VERSION ""

NS_ :

BS_:

BU_: BCMB_AUXM SCMB_PSM HVAC_RCCM SOBDMD_AHCM_FOH TRM GWM _delete RTM PDM SCMH SCMG RSM DDM RGTM DSM GENERIC TSTR

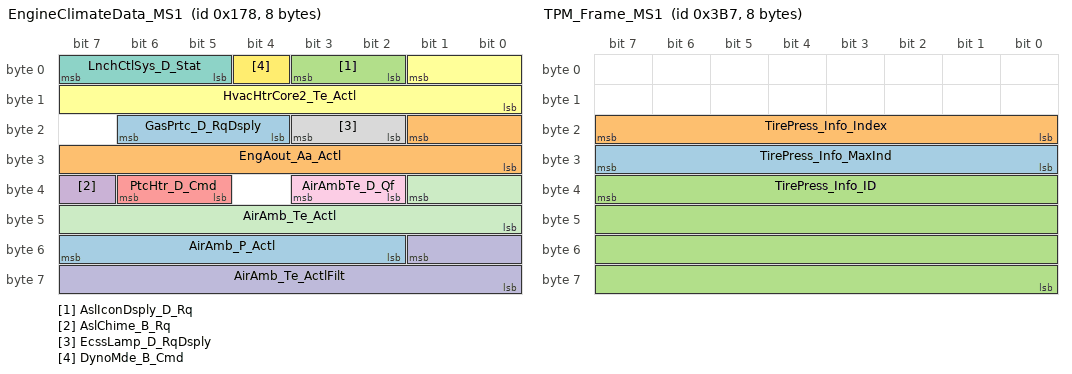
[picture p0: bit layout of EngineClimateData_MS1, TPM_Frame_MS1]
BO_ 376 EngineClimateData_MS1: 8 GWM
 SG_ GasPrtc_D_RqDsply : 22|3@0+ (1,0) [0|7] "SED"  GENERIC
 SG_ EngAout_Aa_Actl : 17|10@0+ (0.05,-25.6) [-25.6|25.55] "rpm/ms"  GENERIC
 SG_ AslIconDsply_D_Rq : 3|2@0+ (1,0) [0|3] "SED"  GENERIC
 SG_ AslChime_B_Rq : 39|1@0+ (1,0) [0|1] "SED"  GENERIC
 SG_ PtcHtr_D_Cmd : 38|2@0+ (1,0) [0|3] "SED"  GENERIC
 SG_ HvacHtrCore2_Te_Actl : 1|10@0+ (0.25,-50) [-50|205.5] "degC"  HVAC_RCCM
 SG_ LnchCtlSys_D_Stat : 7|3@0+ (1,0) [0|7] "SED" Vector__XXX
 SG_ EcssLamp_D_RqDsply : 19|2@0+ (1,0) [0|3] "SED"  GENERIC
 SG_ AirAmbTe_D_Qf : 35|2@0+ (1,0) [0|3] "SED"  HVAC_RCCM
 SG_ AirAmb_Te_ActlFilt : 49|10@0+ (0.25,-128) [-128|127.75] "deg C"  HVAC_RCCM
 SG_ AirAmb_Te_Actl : 33|10@0+ (0.25,-128) [-128|127.75] "degC"  HVAC_RCCM
 SG_ DynoMde_B_Cmd : 4|1@0+ (1,0) [0|1] "SED"  GENERIC
 SG_ AirAmb_P_Actl : 55|6@0+ (10,500) [500|1110] "mbar"  SOBDMD_AHCM_FOH

BO_ 951 TPM_Frame_MS1: 8 GWM
 SG_ TirePress_Info_MaxInd : 31|8@0+ (1,0) [0|255] "Unitless"  RTM
 SG_ TirePress_Info_Index : 23|8@0+ (1,0) [0|255] "Unitless"  RTM
 SG_ TirePress_Info_ID : 39|32@0+ (1,0) [0|4294967295] "Unitless"  RTM

BO_ 1068 Batt_Mgmt_Data_MS1: 8 GWM
 SG_ HvacAirFullOut_B_Rq_UB : 60|1@0+ (1,0) [0|1] "SED"  HVAC_RCCM
 SG_ HvacAirFullOut_B_Rq : 61|1@0+ (1,0) [0|1] "SED"  HVAC_RCCM
 SG_ HvacCmprLim_D_Stat_UB : 56|1@0+ (1,0) [0|1] "SED"  HVAC_RCCM
 SG_ HvacCmprLim_D_Stat : 59|3@0+ (1,0) [0|7] "SED"  HVAC_RCCM
 SG_ HvacAirFlw_B_RqBatt_UB : 62|1@0+ (1,0) [0|1] "SED"  HVAC_RCCM
 SG_ HvacAirFlw_B_RqBatt : 63|1@0+ (1,0) [0|1] "SED"  HVAC_RCCM
 SG_ HvacRec_D_RqMxBatt_UB : 21|1@0+ (1,0) [0|1] "SED"  HVAC_RCCM
 SG_ HvacRec_D_RqMxBatt : 20|4@0+ (1,0) [0|15] "SED"  HVAC_RCCM
 SG_ Batt_Lo_SoC_B_UB : 22|1@0+ (1,0) [0|1] "SED"  HVAC_RCCM,TRM
 SG_ Batt_Lo_SoC_B : 23|1@0+ (1,0) [0|1] "SED"  HVAC_RCCM,TRM
 SG_ Batt_Crit_SoC_B_UB : 14|1@0+ (1,0) [0|1] "SED"  HVAC_RCCM,TRM
 SG_ Batt_Crit_SoC_B : 15|1@0+ (1,0) [0|1] "SED"  HVAC_RCCM,TRM
 SG_ Shed_T_Eng_Off_B_UB : 12|1@0+ (1,0) [0|1] "SED"  HVAC_RCCM,TRM
 SG_ Shed_T_Eng_Off_B : 13|1@0+ (1,0) [0|1] "SED"  HVAC_RCCM,TRM
 SG_ Shed_Level_Req_UB : 8|1@0+ (1,0) [0|1] "SED"  HVAC_RCCM,DDM,PDM,TRM
 SG_ Shed_Level_Req : 11|3@0+ (1,0) [0|7] "SED"  HVAC_RCCM,DDM,PDM,TRM
 SG_ Shed_Feature_Group_ID_UB : 2|1@0+ (1,0) [0|1] "SED"  HVAC_RCCM,TRM
 SG_ Shed_Feature_Group_ID : 7|5@0+ (1,0) [0|31] "SED"  HVAC_RCCM,TRM
 SG_ Shed_Drain_Eng_Off_B_UB : 0|1@0+ (1,0) [0|1] "SED"  HVAC_RCCM,TRM
 SG_ Shed_Drain_Eng_Off_B : 1|1@0+ (1,0) [0|1] "SED"  HVAC_RCCM,TRM
 SG_ HvacAir_Flw_EstBatt_UB : 16|1@0+ (1,0) [0|1] "SED"  HVAC_RCCM
 SG_ HvacAir_Flw_EstBatt : 31|8@0+ (0.5,0) [0|127] "liter/second"  HVAC_RCCM
 SG_ AirCondRec_B_Rq_UB : 44|1@0+ (1,0) [0|1] "SED"  HVAC_RCCM
 SG_ AirCondFluidHi_P_Actl_UB : 45|1@0+ (1,0) [0|1] "SED"  HVAC_RCCM
 SG_ AirCondClutch_B_Stats_UB : 43|1@0+ (1,0) [0|1] "SED"  HVAC_RCCM
 SG_ AirCondRec_B_Rq : 47|1@0+ (1,0) [0|1] "SED"  HVAC_RCCM
 SG_ AirCondFluidHi_P_Actl : 39|8@0+ (0.125,0) [0|31.625] "bar"  HVAC_RCCM
 SG_ AirCondClutch_B_Stats : 46|1@0+ (1,0) [0|1] "SED"  HVAC_RCCM

BO_ 963 BCM_Lamp_Stat_MS1: 8 GWM
 SG_ Illuminated_Entry_Stat : 63|2@0+ (1,0) [0|3] "SED" Vector__XXX
 SG_ Dr_Courtesy_Light_Stat : 49|2@0+ (1,0) [0|3] "SED" Vector__XXX
 SG_ ImpactEvntFdbck_D_Stat : 53|2@0+ (1,0) [0|3] "SED"  GENERIC
 SG_ DrTgateLck_D_Stat : 61|2@0+ (1,0) [0|3] "SED"  GENERIC
 SG_ PudLampPsngr_D_Rq : 57|2@0+ (1,0) [0|3] "SED"  PDM
 SG_ HeadLampLoOut_B_Stat : 32|1@0+ (1,0) [0|1] "SED"  GENERIC
 SG_ CrnrLghtRight_Pc_Rq : 47|7@0+ (1,0) [0|100] "percent"  GENERIC
 SG_ CrnrLghtLeft_Pc_Rq : 39|7@0+ (1,0) [0|100] "percent"  GENERIC
 SG_ HeadLghtHiFdbck_D_Stat : 55|2@0+ (1,0) [0|3] "SED"  GENERIC
 SG_ PrkLightChime_B_Rq : 25|1@0+ (1,0) [0|1] "SED"  GENERIC
 SG_ TrnNotInPrkChime_B_Rq : 24|1@0+ (1,0) [0|1] "SED"  GENERIC
 SG_ HomeSafeLtChime_B_Rq : 28|1@0+ (1,0) [0|1] "SED"  GENERIC
 SG_ StopLghtOn_B_Stat : 8|1@0+ (1,0) [0|1] "SED"  RSM,TRM
 SG_ RvrseLghtOn_B_Stat : 9|1@0+ (1,0) [0|1] "SED"  TRM
 SG_ PrkLght_D_Stat : 13|2@0+ (1,0) [0|3] "SED"  TRM
 SG_ HeadLghtSwtch_D_Stat : 15|2@0+ (1,0) [0|3] "SED"  GENERIC
 SG_ KeyInIgnWarn_B_Cmd : 27|1@0+ (1,0) [0|1] "SED"  GENERIC
 SG_ HeadLampLoFrOn_B_Stat : 2|1@0+ (1,0) [0|1] "SED"  GENERIC
 SG_ HeadLampLoFlOn_B_Stat : 3|1@0+ (1,0) [0|1] "SED"  GENERIC
 SG_ Headlamp_On_Wrning_Cmd : 29|1@0+ (1,0) [0|1] "SED"  GENERIC
 SG_ HeadLampLoActv_B_Stat : 4|1@0+ (1,0) [0|1] "SED"  GENERIC
 SG_ HeadLghtHiOn_B_Stat : 1|1@0+ (1,0) [0|1] "SED"  GENERIC
 SG_ Park_Brake_Chime_Rqst : 26|1@0+ (1,0) [0|1] "SED"  GENERIC
 SG_ BrkWarnInd_B_Rq : 20|1@0+ (1,0) [0|1] "SED"  GENERIC
 SG_ Brk_Fluid_Lvl_Low : 31|2@0+ (1,0) [0|3] "SED"  GENERIC
 SG_ ReducedGuard_D_Stat : 19|2@0+ (1,0) [0|3] "SED"  GENERIC
 SG_ Courtesy_BSave_Stat : 7|2@0+ (1,0) [0|3] "SED"  DDM,PDM
 SG_ DayRnngLampOn_B_Stat : 5|1@0+ (1,0) [0|1] "SED"  GENERIC
 SG_ PerimeterAlarmChimeRq : 0|1@0+ (1,0) [0|1] "SED"  GENERIC
 SG_ PudLampDrv_D_Rq : 59|2@0+ (1,0) [0|3] "SED"  DDM
 SG_ Courtesy_Delay_Status : 51|2@0+ (1,0) [0|3] "SED" Vector__XXX
 SG_ Perimeter_Alarm_Status : 17|2@0+ (1,0) [0|3] "SED"  RSM,TRM
 SG_ WndwGlbl_D_Cmd : 23|3@0+ (1,0) [0|7] "SED"  DDM,PDM
 SG_ PudLamp_D_Rq : 11|2@0+ (1,0) [0|3] "SED"  DDM,PDM

BO_ 964 BodyInfo_MS1: 8 GWM
 SG_ FohEng_D_Rq_UB : 60|1@0+ (1,0) [0|1] "SED"  SOBDMD_AHCM_FOH
 SG_ FohEng_D_Rq : 62|2@0+ (1,0) [0|3] "SED"  SOBDMD_AHCM_FOH
 SG_ EcoMode_B_Stat_UB : 56|1@0+ (1,0) [0|1] "SED"  GENERIC
 SG_ Cta_D_Rq_UB : 57|1@0+ (1,0) [0|1] "SED" Vector__XXX
 SG_ Cta_D_Rq : 59|2@0+ (1,0) [0|3] "SED" Vector__XXX
 SG_ GearRvrse_D_Actl_UB : 48|1@0+ (1,0) [0|1] "SED"  HVAC_RCCM,PDM,DDM
 SG_ GearRvrse_D_Actl : 51|3@0+ (1,0) [0|7] "SED"  HVAC_RCCM,PDM,DDM
 SG_ TurnLghtSwtch_D_Stat_UB : 52|1@0+ (1,0) [0|1] "SED" Vector__XXX
 SG_ TurnLghtSwtch_D_Stat : 54|2@0+ (1,0) [0|3] "SED" Vector__XXX
 SG_ Power_Liftgate_Mode_Cmd_UB : 6|1@0+ (1,0) [0|1] "SED"  RGTM
 SG_ Power_Liftgate_Mode_Cmd : 7|1@0+ (1,0) [0|1] "SED"  RGTM
 SG_ EcoMode_B_Stat : 20|1@0+ (1,0) [0|1] "SED"  GENERIC
 SG_ MetricActvTe_B_Actl_UB : 2|1@0+ (1,0) [0|1] "SED"  HVAC_RCCM
 SG_ MetricActvTe_B_Actl : 3|1@0+ (1,0) [0|1] "SED"  HVAC_RCCM
 SG_ EngClntTe_D_Qf : 22|2@0+ (1,0) [0|3] "SED"  HVAC_RCCM
 SG_ Sod_D_Rq : 1|2@0+ (1,0) [0|3] "SED" Vector__XXX
 SG_ MetricActv_B_Actl : 5|1@0+ (1,0) [0|1] "SED"  HVAC_RCCM
 SG_ EngClnt_Te_Actl : 15|8@0+ (1,-60) [-60|195] "degC"  HVAC_RCCM
 SG_ MetricActv_B_Actl_UB : 4|1@0+ (1,0) [0|1] "SED"  HVAC_RCCM
 SG_ EngClnt_Te_Actl_UB : 23|1@0+ (1,0) [0|1] "SED"  HVAC_RCCM
 SG_ OCSSensrDataUpperLim_UB : 28|1@0+ (1,0) [0|1] "SED"  HVAC_RCCM,SCMG,SCMH
 SG_ OCSSensrDataUpperLim : 47|8@0+ (1,0) [0|254] "SED"  HVAC_RCCM,SCMG,SCMH
 SG_ OCSSensrDataLowerLim_UB : 29|1@0+ (1,0) [0|1] "SED"  HVAC_RCCM,SCMG,SCMH
 SG_ PrkAid_D_Falt : 18|3@0+ (1,0) [0|7] "SED"  GENERIC
 SG_ OCSSensrDataLowerLim : 39|8@0+ (1,0) [0|254] "SED"  HVAC_RCCM,SCMG,SCMH
 SG_ PrkAid_D_Falt_UB : 63|1@0+ (1,0) [0|1] "SED"  GENERIC
 SG_ WiprFront_D_Stat_UB : 55|1@0+ (1,0) [0|1] "SED"  HVAC_RCCM
 SG_ WiprFront_D_Stat : 27|4@0+ (1,0) [0|15] "SED"  HVAC_RCCM
 SG_ CamraDefog_B_Req_UB : 30|1@0+ (1,0) [0|1] "SED"  HVAC_RCCM
 SG_ Sod_D_Rq_UB : 19|1@0+ (1,0) [0|1] "SED" Vector__XXX
 SG_ CamraDefog_B_Req : 31|1@0+ (1,0) [0|1] "SED"  HVAC_RCCM

BO_ 1843 TesterPhysicalReqHVAC_RCCM: 8 TSTR
 SG_ TesterPhysicalReqHVAC_RCCM : 7|64@0+ (1,0) [0|1.84467E+019] "unitless"  HVAC_RCCM

BO_ 1851 TesterPhysicalResHVAC_RCCM: 8 HVAC_RCCM
 SG_ TesterPhysicalResHVAC_RCCM : 7|64@0+ (1,0) [0|1.84467E+019] "unitless"  TSTR

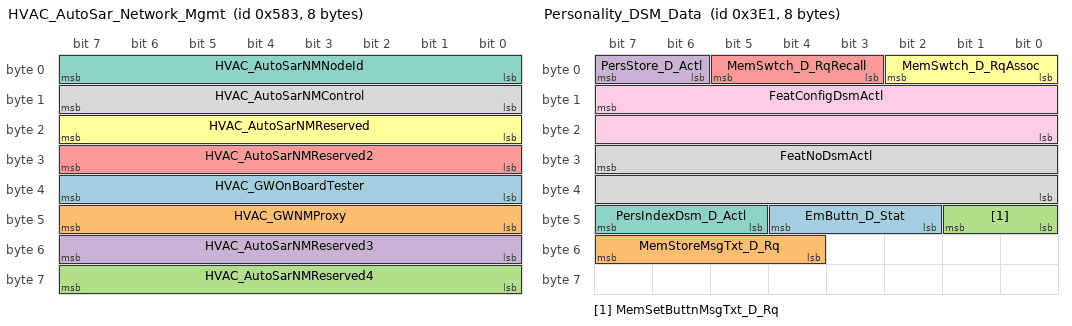
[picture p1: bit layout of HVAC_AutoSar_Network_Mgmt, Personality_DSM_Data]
BO_ 1411 HVAC_AutoSar_Network_Mgmt: 8 HVAC_RCCM
 SG_ HVAC_GWOnBoardTester : 39|8@0+ (1,0) [0|255] "unitless"  GWM
 SG_ HVAC_GWNMProxy : 47|8@0+ (1,0) [0|255] "unitless"  GWM
 SG_ HVAC_AutoSarNMReserved4 : 63|8@0+ (1,0) [0|255] "unitless"  GWM
 SG_ HVAC_AutoSarNMReserved3 : 55|8@0+ (1,0) [0|255] "unitless"  GWM
 SG_ HVAC_AutoSarNMReserved2 : 31|8@0+ (1,0) [0|255] "unitless"  GWM
 SG_ HVAC_AutoSarNMReserved : 23|8@0+ (1,0) [0|255] "unitless"  GWM
 SG_ HVAC_AutoSarNMNodeId : 7|8@0+ (1,0) [0|255] "unitless"  GWM
 SG_ HVAC_AutoSarNMControl : 15|8@0+ (1,0) [0|255] "unitless"  GWM

BO_ 993 Personality_DSM_Data: 8 DSM
 SG_ EmButtn_D_Stat : 44|3@0+ (1,0) [0|7] "SED"  DDM,GWM
 SG_ MemStoreMsgTxt_D_Rq : 55|4@0+ (1,0) [0|15] "SED"  GWM
 SG_ MemSetButtnMsgTxt_D_Rq : 41|2@0+ (1,0) [0|3] "SED"  GWM
 SG_ PersStore_D_Actl : 7|2@0+ (1,0) [0|3] "SED"  GWM
 SG_ MemSwtch_D_RqRecall : 5|3@0+ (1,0) [0|7] "SED"  GWM
 SG_ MemSwtch_D_RqAssoc : 2|3@0+ (1,0) [0|7] "SED"  GWM
 SG_ PersIndexDsm_D_Actl : 47|3@0+ (1,0) [0|7] "SED"  GENERIC,GWM
 SG_ FeatNoDsmActl : 31|16@0+ (1,0) [0|65535] "Number"  GWM
 SG_ FeatConfigDsmActl : 15|16@0+ (1,0) [0|65535] "Undefined"  GWM

BO_ 1881 TesterPhysicalResRTM: 8 RTM
 SG_ TesterPhysicalResRTM : 7|64@0+ (1,0) [0|1.84467E+019] "unitless"  TSTR

BO_ 1873 TesterPhysicalReqRTM: 8 TSTR
 SG_ TesterPhysicalReqRTM : 7|64@0+ (1,0) [0|1.84467E+019] "unitless"  RTM

BO_ 2015 TesterFunctionalReq_M1: 8 TSTR
 SG_ TesterFunctionalReq : 7|64@0+ (1,0) [0|1.84467E+019] "unitless"  BCMB_AUXM,SCMB_PSM,HVAC_RCCM,SOBDMD_AHCM_FOH,PDM,SCMG,SCMH,TRM,RSM,RTM,GWM,DDM,DSM,RGTM

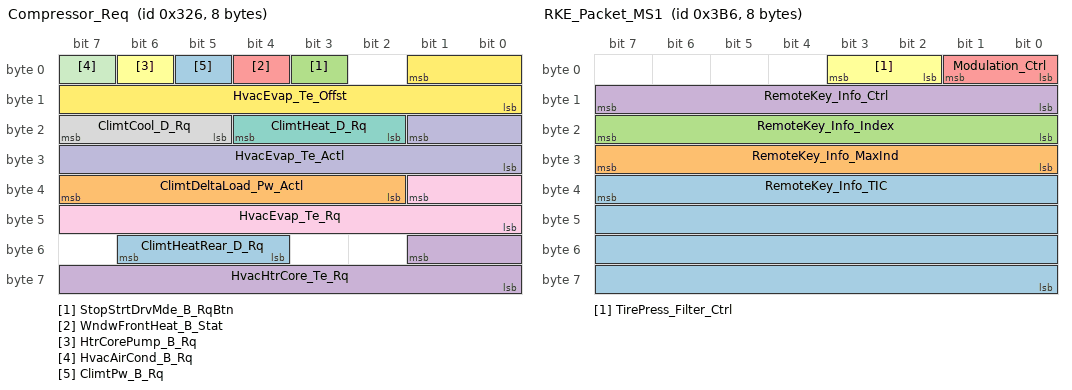
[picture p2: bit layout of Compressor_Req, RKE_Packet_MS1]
BO_ 806 Compressor_Req: 8 HVAC_RCCM
 SG_ ClimtHeatRear_D_Rq : 54|3@0+ (1,0) [0|7] "SED"  GWM
 SG_ ClimtDeltaLoad_Pw_Actl : 39|6@0+ (50,-1600) [-1600|1450] "watts"  GWM
 SG_ StopStrtDrvMde_B_RqBtn : 3|1@0+ (1,0) [0|1] "SED"  GWM
 SG_ HvacHtrCore_Te_Rq : 49|10@0+ (0.25,-50) [-50|205.75] "degC"  GWM
 SG_ WndwFrontHeat_B_Stat : 4|1@0+ (1,0) [0|1] "SED"  GWM
 SG_ HtrCorePump_B_Rq : 6|1@0+ (1,0) [0|1] "SED"  GWM
 SG_ ClimtHeat_D_Rq : 20|3@0+ (1,0) [0|7] "SED"  GWM
 SG_ ClimtCool_D_Rq : 23|3@0+ (1,0) [0|7] "SED"  GWM
 SG_ HvacEvap_Te_Rq : 33|10@0+ (0.125,-50) [-50|77.875] "Degrees C"  GWM
 SG_ HvacEvap_Te_Actl : 17|10@0+ (0.125,-50) [-50|77.75] "Degrees C"  GWM
 SG_ HvacAirCond_B_Rq : 7|1@0+ (1,0) [0|1] "SED"  GWM
 SG_ HvacEvap_Te_Offst : 1|10@0+ (0.125,-50) [-50|77.875] "Degrees C"  GWM
 SG_ ClimtPw_B_Rq : 5|1@0+ (1,0) [0|1] "SED"  GWM

BO_ 950 RKE_Packet_MS1: 8 GWM
 SG_ RemoteKey_Info_TIC : 39|32@0+ (1,0) [0|4294967295] "Unitless"  RTM
 SG_ RemoteKey_Info_MaxInd : 31|8@0+ (1,0) [0|255] "Unitless"  RTM
 SG_ RemoteKey_Info_Index : 23|8@0+ (1,0) [0|255] "Unitless"  RTM
 SG_ RemoteKey_Info_Ctrl : 15|8@0+ (1,0) [0|255] "Unitless"  GENERIC
 SG_ Modulation_Ctrl : 1|2@0+ (1,0) [0|3] "SED"  GENERIC
 SG_ TirePress_Filter_Ctrl : 3|2@0+ (1,0) [0|3] "SED"  RTM

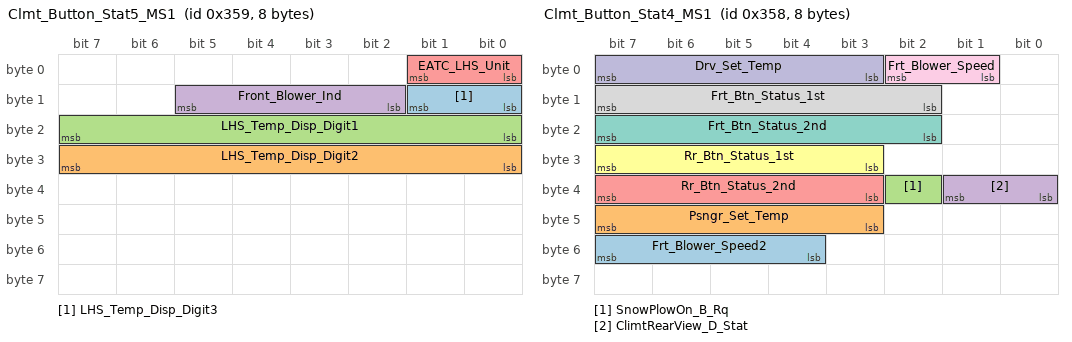
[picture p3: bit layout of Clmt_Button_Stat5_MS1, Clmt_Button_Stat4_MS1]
BO_ 857 Clmt_Button_Stat5_MS1: 8 GWM
 SG_ LHS_Temp_Disp_Digit3 : 9|2@0+ (1,0) [0|3] "SED"  HVAC_RCCM
 SG_ LHS_Temp_Disp_Digit2 : 31|8@0+ (1,0) [0|255] "ASCII"  HVAC_RCCM
 SG_ LHS_Temp_Disp_Digit1 : 23|8@0+ (1,0) [0|255] "ASCII"  HVAC_RCCM
 SG_ Front_Blower_Ind : 13|4@0+ (1,0) [0|15] "SED"  HVAC_RCCM
 SG_ EATC_LHS_Unit : 1|2@0+ (1,0) [0|3] "SED"  HVAC_RCCM

BO_ 856 Clmt_Button_Stat4_MS1: 8 GWM
 SG_ Frt_Blower_Speed2 : 55|4@0+ (1,0) [0|15] "SED"  HVAC_RCCM
 SG_ Psngr_Set_Temp : 47|5@0+ (1,0) [0|31] "SED"  HVAC_RCCM
 SG_ SnowPlowOn_B_Rq : 34|1@0+ (1,0) [0|1] "SED" Vector__XXX
 SG_ ClimtRearView_D_Stat : 33|2@0+ (1,0) [0|3] "SED" Vector__XXX
 SG_ Rr_Btn_Status_2nd : 39|5@0+ (1,0) [0|31] "SED" Vector__XXX
 SG_ Rr_Btn_Status_1st : 31|5@0+ (1,0) [0|31] "SED" Vector__XXX
 SG_ Frt_Btn_Status_2nd : 23|6@0+ (1,0) [0|63] "SED"  HVAC_RCCM
 SG_ Frt_Btn_Status_1st : 15|6@0+ (1,0) [0|63] "SED"  HVAC_RCCM
 SG_ Frt_Blower_Speed : 2|2@0+ (1,0) [0|3] "SED"  HVAC_RCCM
 SG_ Drv_Set_Temp : 7|5@0+ (1,0) [0|31] "SED"  HVAC_RCCM

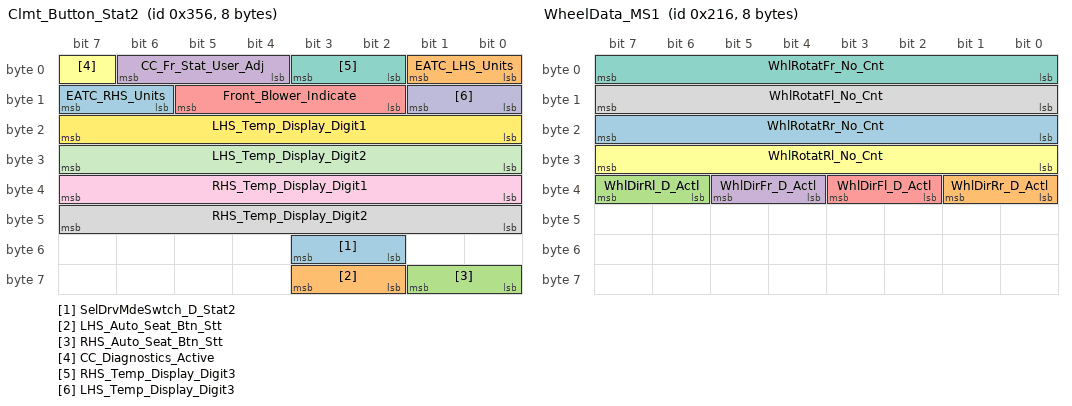
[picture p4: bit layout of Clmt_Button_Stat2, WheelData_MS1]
BO_ 854 Clmt_Button_Stat2: 8 HVAC_RCCM
 SG_ SelDrvMdeSwtch_D_Stat2 : 51|2@0+ (1,0) [0|3] "SED"  GWM
 SG_ LHS_Auto_Seat_Btn_Stt : 59|2@0+ (1,0) [0|3] "SED"  GWM
 SG_ RHS_Auto_Seat_Btn_Stt : 57|2@0+ (1,0) [0|3] "SED"  GWM
 SG_ CC_Fr_Stat_User_Adj : 6|3@0+ (1,0) [0|7] "SED"  GWM
 SG_ Front_Blower_Indicate : 13|4@0+ (1,0) [0|15] "SED"  GWM
 SG_ CC_Diagnostics_Active : 7|1@0+ (1,0) [0|1] "SED"  GWM
 SG_ RHS_Temp_Display_Digit3 : 3|2@0+ (1,0) [0|3] "SED"  GWM
 SG_ RHS_Temp_Display_Digit2 : 47|8@0+ (1,0) [0|255] "ASCII"  GWM
 SG_ RHS_Temp_Display_Digit1 : 39|8@0+ (1,0) [0|255] "ASCII"  GWM
 SG_ LHS_Temp_Display_Digit3 : 9|2@0+ (1,0) [0|3] "SED"  GWM
 SG_ LHS_Temp_Display_Digit2 : 31|8@0+ (1,0) [0|255] "ASCII"  GWM
 SG_ LHS_Temp_Display_Digit1 : 23|8@0+ (1,0) [0|255] "ASCII"  GWM
 SG_ EATC_RHS_Units : 15|2@0+ (1,0) [0|3] "SED"  GWM
 SG_ EATC_LHS_Units : 1|2@0+ (1,0) [0|3] "SED"  GWM

BO_ 534 WheelData_MS1: 8 GWM
 SG_ WhlRotatRr_No_Cnt : 23|8@0+ (1,0) [0|255] "Unitless" Vector__XXX
 SG_ WhlDirRr_D_Actl : 33|2@0+ (1,0) [0|3] "SED"  GENERIC
 SG_ WhlDirRl_D_Actl : 39|2@0+ (1,0) [0|3] "SED"  GENERIC
 SG_ WhlDirFr_D_Actl : 37|2@0+ (1,0) [0|3] "SED"  GENERIC
 SG_ WhlDirFl_D_Actl : 35|2@0+ (1,0) [0|3] "SED"  GENERIC
 SG_ WhlRotatRl_No_Cnt : 31|8@0+ (1,0) [0|255] "Unitless" Vector__XXX
 SG_ WhlRotatFr_No_Cnt : 7|8@0+ (1,0) [0|255] "Unitless" Vector__XXX
 SG_ WhlRotatFl_No_Cnt : 15|8@0+ (1,0) [0|255] "Unitless" Vector__XXX

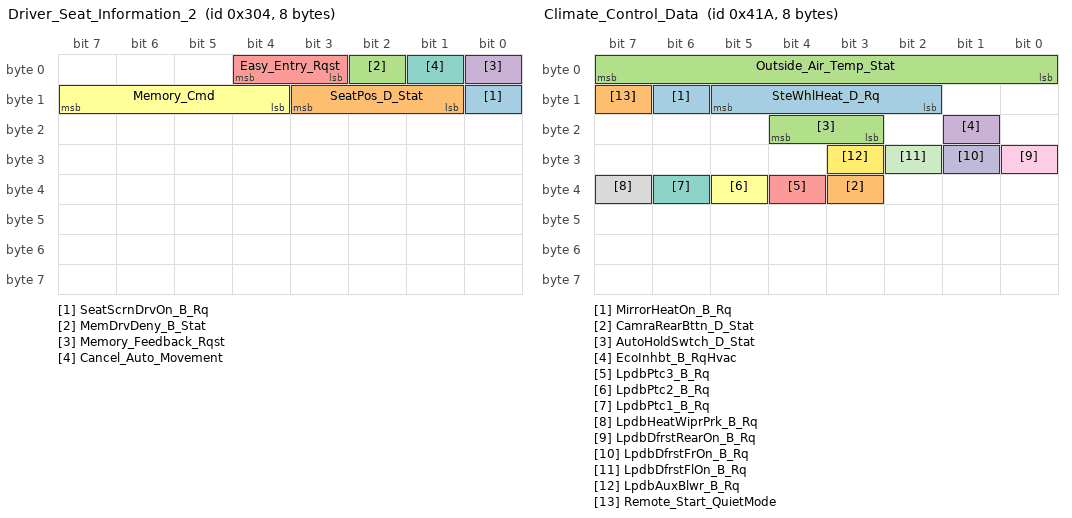
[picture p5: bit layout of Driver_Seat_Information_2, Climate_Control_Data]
BO_ 772 Driver_Seat_Information_2: 8 DSM
 SG_ SeatScrnDrvOn_B_Rq : 8|1@0+ (1,0) [0|1] "SED"  GWM
 SG_ SeatPos_D_Stat : 11|3@0+ (1,0) [0|7] "SED" Vector__XXX
 SG_ MemDrvDeny_B_Stat : 2|1@0+ (1,0) [0|1] "SED"  GWM
 SG_ Memory_Feedback_Rqst : 0|1@0+ (1,0) [0|1] "SED"  GWM
 SG_ Easy_Entry_Rqst : 4|2@0+ (1,0) [0|3] "SED"  SCMH,SCMG
 SG_ Memory_Cmd : 15|4@0+ (1,0) [0|15] "SED"  GWM,SCMH,DDM,PDM,SCMG
 SG_ Cancel_Auto_Movement : 1|1@0+ (1,0) [0|1] "SED"  SCMH,PDM,DDM,SCMG

BO_ 1070 EngineData_2_MS1: 8 GWM
 SG_ StopStrtStdby_D_Indic_UB : 43|1@0+ (1,0) [0|1] "SED"  HVAC_RCCM
 SG_ PassRstrnInd_Req_UB : 42|1@0+ (1,0) [0|1] "SED"  HVAC_RCCM
 SG_ HiElPwInhbt_B_Stat_UB : 61|1@0+ (1,0) [0|1] "SED"  DDM,PDM
 SG_ HiElPwInhbt_B_Stat : 47|1@0+ (1,0) [0|1] "SED"  DDM,PDM
 SG_ StopStrtStdby_D_Indic : 46|3@0+ (1,0) [0|7] "SED"  HVAC_RCCM
 SG_ CoolantFanStepAct_UB : 2|1@0+ (1,0) [0|1] "SED"  HVAC_RCCM
 SG_ CoolantFanStepAct : 7|5@0+ (1,0) [0|31] "Steps"  HVAC_RCCM
 SG_ Reserve_UB : 1|1@0+ (1,0) [0|1] "SED"  GENERIC
 SG_ RstrnImpactEvntStatus_UB : 56|1@0+ (1,0) [0|1] "SED"  DDM,PDM,HVAC_RCCM,SOBDMD_AHCM_FOH
 SG_ EngAirIn_Te_Actl_UB : 60|1@0+ (1,0) [0|1] "SED"  HVAC_RCCM
 SG_ RstrnImpactEvntStatus : 59|3@0+ (1,0) [0|7] "SED"  DDM,PDM,HVAC_RCCM,SOBDMD_AHCM_FOH
 SG_ EngAirIn_Te_Actl : 55|10@0+ (0.25,-128) [-128|127.25] "degC"  HVAC_RCCM
 SG_ EngAout_N_Actl_UB : 0|1@0+ (1,0) [0|1] "SED"  HVAC_RCCM,SOBDMD_AHCM_FOH
 SG_ EngAout_N_Actl : 28|13@0+ (2,0) [0|16382] "rpm"  HVAC_RCCM,SOBDMD_AHCM_FOH
 SG_ VehVActlEng_D_Qf : 31|2@0+ (1,0) [0|3] "SED"  SOBDMD_AHCM_FOH,HVAC_RCCM,DSM,RTM,DDM,PDM
 SG_ Veh_V_ActlEng_UB : 29|1@0+ (1,0) [0|1] "SED"  BCMB_AUXM,TRM,SOBDMD_AHCM_FOH,HVAC_RCCM,RGTM,DSM,SCMG,SCMH,DDM,PDM,RTM
 SG_ Veh_V_ActlEng : 15|16@0+ (0.01,0) [0|655.35] "kph"  BCMB_AUXM,TRM,HVAC_RCCM,SOBDMD_AHCM_FOH,RGTM,DSM,SCMG,SCMH,DDM,PDM,RTM
 SG_ PassRstrnInd_Req : 41|2@0+ (1,0) [0|3] "SED"  HVAC_RCCM

BO_ 1050 Climate_Control_Data: 8 HVAC_RCCM
 SG_ MirrorHeatOn_B_Rq : 14|1@0+ (1,0) [0|1] "SED"  DDM,PDM,GWM
 SG_ CamraRearBttn_D_Stat : 35|1@0+ (1,0) [0|1] "SED"  GWM
 SG_ AutoHoldSwtch_D_Stat : 20|2@0+ (1,0) [0|3] "SED"  GWM
 SG_ EcoInhbt_B_RqHvac : 17|1@0+ (1,0) [0|1] "SED"  GWM
 SG_ LpdbPtc3_B_Rq : 36|1@0+ (1,0) [0|1] "SED"  GWM
 SG_ LpdbPtc2_B_Rq : 37|1@0+ (1,0) [0|1] "SED"  GWM
 SG_ LpdbPtc1_B_Rq : 38|1@0+ (1,0) [0|1] "SED"  GWM
 SG_ LpdbHeatWiprPrk_B_Rq : 39|1@0+ (1,0) [0|1] "SED"  GWM
 SG_ LpdbDfrstRearOn_B_Rq : 24|1@0+ (1,0) [0|1] "SED"  GWM
 SG_ LpdbDfrstFrOn_B_Rq : 25|1@0+ (1,0) [0|1] "SED"  GWM
 SG_ LpdbDfrstFlOn_B_Rq : 26|1@0+ (1,0) [0|1] "SED"  GWM
 SG_ LpdbAuxBlwr_B_Rq : 27|1@0+ (1,0) [0|1] "SED"  GWM
 SG_ SteWhlHeat_D_Rq : 13|4@0+ (1,0) [0|15] "SED"  GWM
 SG_ Remote_Start_QuietMode : 15|1@0+ (1,0) [0|1] "SED"  GWM
 SG_ Outside_Air_Temp_Stat : 7|8@0+ (0.5,-40) [-40|86.5] "Degrees C"  RGTM,GWM,DDM,PDM,SOBDMD_AHCM_FOH

BO_ 1856 TesterPhysicalReqDDM: 8 TSTR
 SG_ TesterPhysicalReqDDM : 7|64@0+ (1,0) [0|1.84467E+019] "unitless"  DDM

BO_ 1864 TesterPhysicalResDDM: 8 DDM
 SG_ TesterPhysicalResDDM : 7|64@0+ (1,0) [0|1.84467E+019] "unitless"  TSTR

BO_ 1937 TesterPhysicalReqTRM: 8 TSTR
 SG_ TesterPhysicalReqTRM : 7|64@0+ (1,0) [0|1.84467E+019] "unitless"  TRM

BO_ 947 BodyInfo_3_MS1: 8 GWM
 SG_ DimmingLvlEvnt_No_Actl : 18|2@0+ (1,0) [0|3] "unitless"  GENERIC
 SG_ DrStatDrvErrCnt_B_Stat : 19|1@0+ (1,0) [0|1] "SED"  GENERIC
 SG_ TurnLghtRightOn_B_Stat : 35|1@0+ (1,0) [0|1] "SED"  GENERIC
 SG_ TurnLghtLeftOn_B_Stat : 54|1@0+ (1,0) [0|1] "SED"  GENERIC
 SG_ Backlit_LED_Status : 23|4@0+ (1,0) [0|15] "SED"  HVAC_RCCM,DDM,PDM
 SG_ FogLghtRearOn_B_Stat : 1|1@0+ (1,0) [0|1] "SED"  TRM
 SG_ ValetMode_D_Mem : 16|1@0+ (1,0) [0|1] "SED"  RGTM
 SG_ IgnKeyType_D_Actl : 39|4@0+ (1,0) [0|15] "SED"  RSM
 SG_ TurnLghtRight_D_Rq : 63|2@0+ (1,0) [0|3] "SED"  RSM,DDM,PDM,TRM
 SG_ Parklamp_Status : 3|2@0+ (1,0) [0|3] "SED"  HVAC_RCCM,TRM,PDM,DDM
 SG_ Litval : 47|8@0+ (1,0) [0|253] "SED"  BCMB_AUXM,HVAC_RCCM,DDM,PDM
 SG_ Key_In_Ignition_Stat : 11|1@0+ (1,0) [0|1] "SED"  RSM,SCMG,SCMH,DSM,RTM
 SG_ Ignition_Status : 7|4@0+ (1,0) [0|15] "SED"  BCMB_AUXM,SCMB_PSM,HVAC_RCCM,RSM,DDM,DSM,PDM,RGTM,RTM,SCMG,SCMH,TRM,SOBDMD_AHCM_FOH
 SG_ Dimming_Lvl : 31|8@0+ (1,0) [0|253] "SED"  BCMB_AUXM,HVAC_RCCM,DDM,PDM
 SG_ Day_Night_Status : 15|2@0+ (1,0) [0|3] "SED"  BCMB_AUXM,TRM,HVAC_RCCM,DDM,PDM
 SG_ Remote_Start_Status : 13|2@0+ (1,0) [0|3] "SED"  HVAC_RCCM,RSM
 SG_ DrStatTgate_B_Actl : 0|1@0+ (1,0) [0|1] "SED"  BCMB_AUXM,DDM,PDM,RSM,TRM,HVAC_RCCM
 SG_ DrStatRr_B_Actl : 49|1@0+ (1,0) [0|1] "SED"  BCMB_AUXM,HVAC_RCCM,DDM,PDM,RSM
 SG_ DrStatRl_B_Actl : 48|1@0+ (1,0) [0|1] "SED"  BCMB_AUXM,HVAC_RCCM,DDM,PDM,RSM
 SG_ DrStatPsngr_B_Actl : 60|1@0+ (1,0) [0|1] "SED"  BCMB_AUXM,SCMB_PSM,DDM,PDM,RSM,HVAC_RCCM
 SG_ DrStatInnrTgate_B_Actl : 58|1@0+ (1,0) [0|1] "SED"  TRM,DDM,RSM,HVAC_RCCM,GENERIC
 SG_ DrStatHood_B_Actl : 59|1@0+ (1,0) [0|1] "SED"  RSM,GENERIC
 SG_ DrStatDrv_B_Actl : 61|1@0+ (1,0) [0|1] "SED"  BCMB_AUXM,TRM,HVAC_RCCM,DDM,PDM,RSM,DSM
 SG_ PrkBrkActv_B_Actl : 55|1@0+ (1,0) [0|1] "SED"  GENERIC
 SG_ LifeCycMde_D_Actl : 53|4@0+ (1,0) [0|15] "SED"  SCMB_PSM,HVAC_RCCM,RGTM,TRM,RTM,DDM,PDM,SOBDMD_AHCM_FOH
 SG_ Delay_Accy : 57|1@0+ (1,0) [0|1] "SED"  DDM,PDM
 SG_ FogLghtFrontOn_B_Stat : 56|1@0+ (1,0) [0|1] "SED"  GENERIC
 SG_ TurnLghtLeft_D_Rq : 9|2@0+ (1,0) [0|3] "SED"  RSM,DDM,PDM,TRM
 SG_ CrashEvnt_D_Stat : 34|2@0+ (1,0) [0|3] "SED"  DDM,PDM,HVAC_RCCM
 SG_ FuelPmpInhbt_B_Stat : 32|1@0+ (1,0) [0|1] "SED"  HVAC_RCCM
 SG_ BodySrvcRqd_B_Rq : 10|1@0+ (1,0) [0|1] "SED"  GENERIC

BO_ 1841 TesterPhysicalReqANT: 8 TSTR
 SG_ TesterPhysicalReqANT : 7|64@0+ (1,0) [0|1.84467E+019] "unitless"  GENERIC

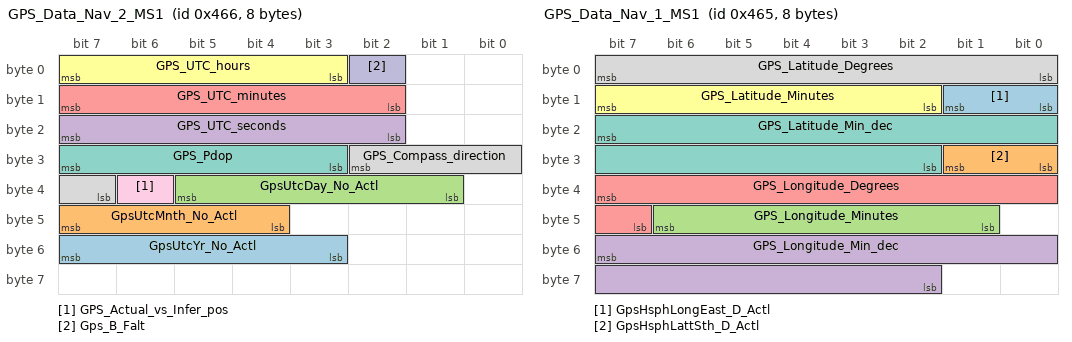
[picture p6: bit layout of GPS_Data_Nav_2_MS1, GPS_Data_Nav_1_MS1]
BO_ 1126 GPS_Data_Nav_2_MS1: 8 GWM
 SG_ GpsUtcYr_No_Actl : 55|5@0+ (1,2010) [2010|2040] "Year" Vector__XXX
 SG_ GpsUtcMnth_No_Actl : 47|4@0+ (1,1) [1|15] "Month" Vector__XXX
 SG_ GpsUtcDay_No_Actl : 37|5@0+ (1,1) [1|32] "Day" Vector__XXX
 SG_ GPS_UTC_seconds : 23|6@0+ (1,0) [0|59] "seconds" Vector__XXX
 SG_ GPS_UTC_minutes : 15|6@0+ (1,0) [0|59] "Minutes" Vector__XXX
 SG_ GPS_UTC_hours : 7|5@0+ (1,0) [0|23] "Hours" Vector__XXX
 SG_ GPS_Pdop : 31|5@0+ (0.2,0) [0|5.8] "unitless" Vector__XXX
 SG_ GPS_Compass_direction : 26|4@0+ (1,0) [0|15] "SED" Vector__XXX
 SG_ GPS_Actual_vs_Infer_pos : 38|1@0+ (1,0) [0|1] "SED" Vector__XXX
 SG_ Gps_B_Falt : 2|1@0+ (1,0) [0|1] "SED" Vector__XXX

BO_ 1125 GPS_Data_Nav_1_MS1: 8 GWM
 SG_ GpsHsphLongEast_D_Actl : 9|2@0+ (1,0) [0|3] "SED" Vector__XXX
 SG_ GpsHsphLattSth_D_Actl : 25|2@0+ (1,0) [0|3] "SED" Vector__XXX
 SG_ GPS_Longitude_Minutes : 46|6@0+ (1,0) [0|61] "Minutes" Vector__XXX
 SG_ GPS_Longitude_Min_dec : 55|14@0+ (0.0001,0) [0|1.6381] "Minutes" Vector__XXX
 SG_ GPS_Longitude_Degrees : 39|9@0+ (1,-179) [-179|330] "Degrees" Vector__XXX
 SG_ GPS_Latitude_Minutes : 15|6@0+ (1,0) [0|61] "Minutes" Vector__XXX
 SG_ GPS_Latitude_Min_dec : 23|14@0+ (0.0001,0) [0|1.6381] "Minutes" Vector__XXX
 SG_ GPS_Latitude_Degrees : 7|8@0+ (1,-89) [-89|164] "Degrees" Vector__XXX

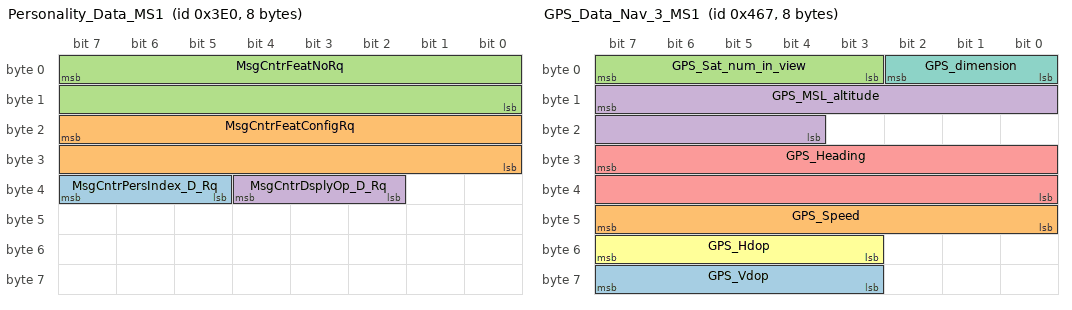
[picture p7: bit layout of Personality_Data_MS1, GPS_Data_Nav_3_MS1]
BO_ 992 Personality_Data_MS1: 8 GWM
 SG_ MsgCntrPersIndex_D_Rq : 39|3@0+ (1,0) [0|7] "SED"  HVAC_RCCM,PDM,DDM,DSM
 SG_ MsgCntrFeatConfigRq : 23|16@0+ (1,0) [0|65535] "unitless"  HVAC_RCCM,PDM,DDM,DSM
 SG_ MsgCntrFeatNoRq : 7|16@0+ (1,0) [0|65535] "Number"  HVAC_RCCM,PDM,DDM,DSM
 SG_ MsgCntrDsplyOp_D_Rq : 36|3@0+ (1,0) [0|7] "SED"  HVAC_RCCM,PDM,DDM,DSM

BO_ 1127 GPS_Data_Nav_3_MS1: 8 GWM
 SG_ GPS_Vdop : 63|5@0+ (0.2,0) [0|5.8] "unitless" Vector__XXX
 SG_ GPS_Speed : 47|8@0+ (1,0) [0|253] "MPH" Vector__XXX
 SG_ GPS_Sat_num_in_view : 7|5@0+ (1,0) [0|29] "unitless" Vector__XXX
 SG_ GPS_MSL_altitude : 15|12@0+ (10,-20460) [-20460|20470] "feet" Vector__XXX
 SG_ GPS_Heading : 31|16@0+ (0.01,0) [0|655.33] "Degrees" Vector__XXX
 SG_ GPS_Hdop : 55|5@0+ (0.2,0) [0|5.8] "unitless" Vector__XXX
 SG_ GPS_dimension : 2|3@0+ (1,0) [0|7] "SED" Vector__XXX

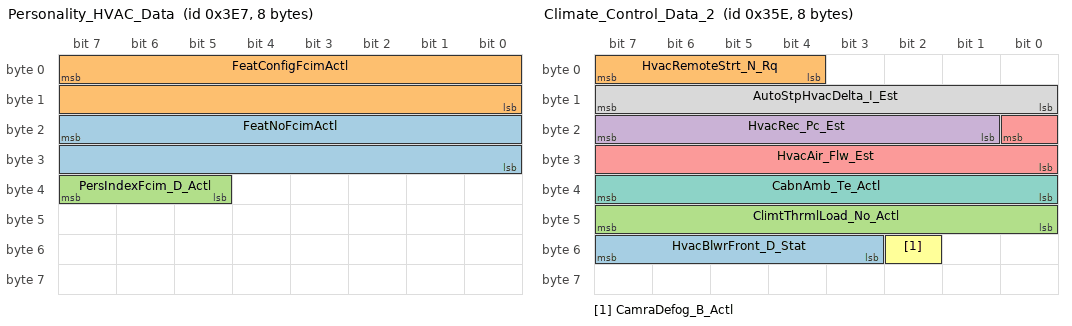
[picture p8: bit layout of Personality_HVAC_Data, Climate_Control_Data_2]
BO_ 999 Personality_HVAC_Data: 8 HVAC_RCCM
 SG_ FeatNoFcimActl : 23|16@0+ (1,0) [0|65535] "Number"  GWM
 SG_ FeatConfigFcimActl : 7|16@0+ (1,0) [0|65535] "Undefined"  GWM
 SG_ PersIndexFcim_D_Actl : 39|3@0+ (1,0) [0|7] "SED"  GWM

BO_ 2027 TesterPhysicalResAHCM: 8 SOBDMD_AHCM_FOH
 SG_ TesterPhysicalResAHCM : 7|64@0+ (1,0) [0|1.84467E+019] "unitless"  TSTR

BO_ 2019 TesterPhysicalReqAHCM: 8 TSTR
 SG_ TesterPhysicalReqAHCM : 7|64@0+ (1,0) [0|1.84467E+019] "unitless"  SOBDMD_AHCM_FOH

BO_ 862 Climate_Control_Data_2: 8 HVAC_RCCM
 SG_ HvacBlwrFront_D_Stat : 55|5@0+ (1,0) [0|31] "SED"  GWM
 SG_ HvacRemoteStrt_N_Rq : 7|4@0+ (100,450) [450|1950] "RPM"  GWM
 SG_ ClimtThrmlLoad_No_Actl : 47|8@0+ (1,0) [0|254] "unitless"  GWM
 SG_ HvacRec_Pc_Est : 23|7@0+ (1,0) [0|127] "Percent"  GWM
 SG_ HvacAir_Flw_Est : 16|9@0+ (0.5,0) [0|255.5] "liter/second"  GWM
 SG_ CamraDefog_B_Actl : 50|1@0+ (1,0) [0|1] "SED"  GWM
 SG_ CabnAmb_Te_Actl : 39|8@0+ (0.5,-57) [-57|70] "degreesC"  SOBDMD_AHCM_FOH,GWM
 SG_ AutoStpHvacDelta_I_Est : 15|8@0+ (1,-192) [-192|62] "ampere"  GWM

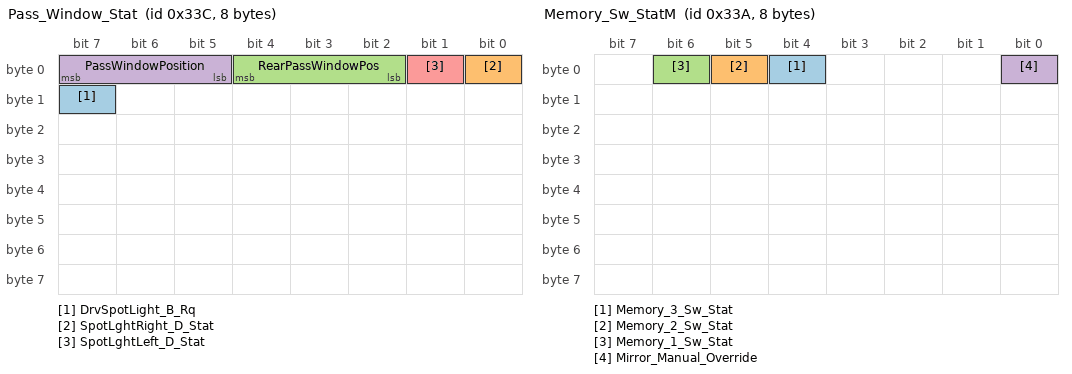
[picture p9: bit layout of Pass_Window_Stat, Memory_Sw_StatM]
BO_ 828 Pass_Window_Stat: 8 PDM
 SG_ DrvSpotLight_B_Rq : 15|1@0+ (1,0) [0|1] "SED"  GWM,DDM
 SG_ SpotLghtRight_D_Stat : 0|1@0+ (1,0) [0|1] "SED"  GWM
 SG_ RearPassWindowPos : 4|3@0+ (1,0) [0|7] "SED"  HVAC_RCCM,GWM
 SG_ PassWindowPosition : 7|3@0+ (1,0) [0|7] "SED"  HVAC_RCCM,GWM
 SG_ SpotLghtLeft_D_Stat : 1|1@0+ (1,0) [0|1] "SED"  GWM

BO_ 1909 TesterPhysicalReqRGTM: 8 TSTR
 SG_ TesterPhysicalReqRGTM : 7|64@0+ (1,0) [0|1.84467E+019] "unitless"  RGTM

BO_ 1917 TesterPhysicalResRGTM: 8 RGTM
 SG_ TesterPhysicalResRGTM : 7|64@0+ (1,0) [0|1.84467E+019] "unitless"  TSTR

BO_ 1860 TesterPhysicalReqDSM: 8 TSTR
 SG_ TesterPhysicalReqDSM : 7|64@0+ (1,0) [0|1.84467E+019] "unitless"  DSM

BO_ 1868 TesterPhysicalResDSM: 8 DSM
 SG_ TesterPhysicalResDSM : 7|64@0+ (1,0) [0|1.84467E+019] "unitless"  TSTR

BO_ 1814 TesterPhysicalReqGWM_M1: 8 TSTR
 SG_ TesterPhysicalReqGWM_M1 : 7|64@0+ (1,0) [0|1.84467E+019] "unitless"  GWM

BO_ 1822 TesterPhysicalResGWM_MS1: 8 GWM
 SG_ TesterPhysicalResGWM_M1 : 7|64@0+ (1,0) [0|1.84467E+019] "unitless"  TSTR

BO_ 826 Memory_Sw_StatM: 8 DDM
 SG_ Memory_3_Sw_Stat : 4|1@0+ (1,0) [0|1] "SED"  GWM,GENERIC,DSM
 SG_ Memory_2_Sw_Stat : 5|1@0+ (1,0) [0|1] "SED"  GWM,GENERIC,DSM
 SG_ Memory_1_Sw_Stat : 6|1@0+ (1,0) [0|1] "SED"  GWM,GENERIC,DSM
 SG_ Mirror_Manual_Override : 0|1@0+ (1,0) [0|1] "SED"  GWM,GENERIC,DSM

BO_ 1098 TrailerInfo_2: 8 TRM

BO_ 853 Clmt_Button_Stat1: 8 HVAC_RCCM
 SG_ RHS_Htd_Seat_Btn_Stt : 53|2@0+ (1,0) [0|3] "SED"  GWM
 SG_ RHS_Cld_Seat_Btn_Stt : 55|2@0+ (1,0) [0|3] "SED"  GWM
 SG_ Outside_Btn_Stt : 47|2@0+ (1,0) [0|3] "SED"  GWM
 SG_ LHS_Htd_Seat_Btn_Stt : 39|2@0+ (1,0) [0|3] "SED"  GWM
 SG_ LHS_Cld_Seat_Btn_Stt : 25|2@0+ (1,0) [0|3] "SED"  GWM
 SG_ FrontMnu_Buttn_Stat : 49|1@0+ (1,0) [0|1] "SED"  GWM
 SG_ Defrost_Btn_Stt : 3|2@0+ (1,0) [0|3] "SED"  GWM
 SG_ Auto_Recirc_Btn_Stt : 5|2@0+ (1,0) [0|3] "SED"  GWM
 SG_ Front_AUTO_Blwr_Lvl : 60|2@0+ (1,0) [0|3] "SED"  GWM
 SG_ RHS_Cond_Seat_Status : 63|3@0+ (1,0) [0|7] "SED"  GWM
 SG_ LHS_Cond_Seat_Status : 10|3@0+ (1,0) [0|7] "SED"  GWM
 SG_ Htd_Strg_Whl_Status : 27|2@0+ (1,0) [0|3] "SED"  GWM
 SG_ Htd_Strg_Whl_Btn_Stt : 29|2@0+ (1,0) [0|3] "SED"  GWM
 SG_ CC_Fr_Btn_User_Adj : 15|5@0+ (1,0) [0|31] "SED"  GWM
 SG_ Htd_Frt_Wsh_Btn_Stt : 31|2@0+ (1,0) [0|3] "SED"  GWM
 SG_ Recirc_Btn_Stt : 41|2@0+ (1,0) [0|3] "SED"  GWM
 SG_ Rear_Defrost_Btn_Stt : 43|2@0+ (1,0) [0|3] "SED"  GWM
 SG_ My_Temp_Btn_Stt : 33|2@0+ (1,0) [0|3] "SED"  GWM
 SG_ Max_Defrost_Btn_Stt : 35|2@0+ (1,0) [0|3] "SED"  GWM
 SG_ Max_AC_Btn_Stt : 37|2@0+ (1,0) [0|3] "SED"  GWM
 SG_ Front_AUTO_Label : 19|2@0+ (1,0) [0|3] "SED"  GWM
 SG_ Windscreen_Btn_Stt : 51|2@0+ (1,0) [0|3] "SED"  GWM
 SG_ Panel_Btn_Stt : 45|2@0+ (1,0) [0|3] "SED"  GWM
 SG_ Front_Power_Btn_Stt : 17|2@0+ (1,0) [0|3] "SED"  GWM
 SG_ Front_AUTO_Btn_Stt : 21|2@0+ (1,0) [0|3] "SED"  GWM
 SG_ Floor_Btn_Stt : 23|2@0+ (1,0) [0|3] "SED"  GWM
 SG_ Dual_Button_Stt : 1|2@0+ (1,0) [0|3] "SED"  GWM
 SG_ AC_Btn_Stt : 7|2@0+ (1,0) [0|3] "SED"  GWM

BO_ 1034 GGCC_Config_Mgmt_ID_1_MS1: 8 GWM
 SG_ VehicleGGCCData : 7|64@0+ (1,0) [0|1.84467E+019] "mixed"  HVAC_RCCM,TRM,PDM,SOBDMD_AHCM_FOH,RTM,DDM,GENERIC,RGTM

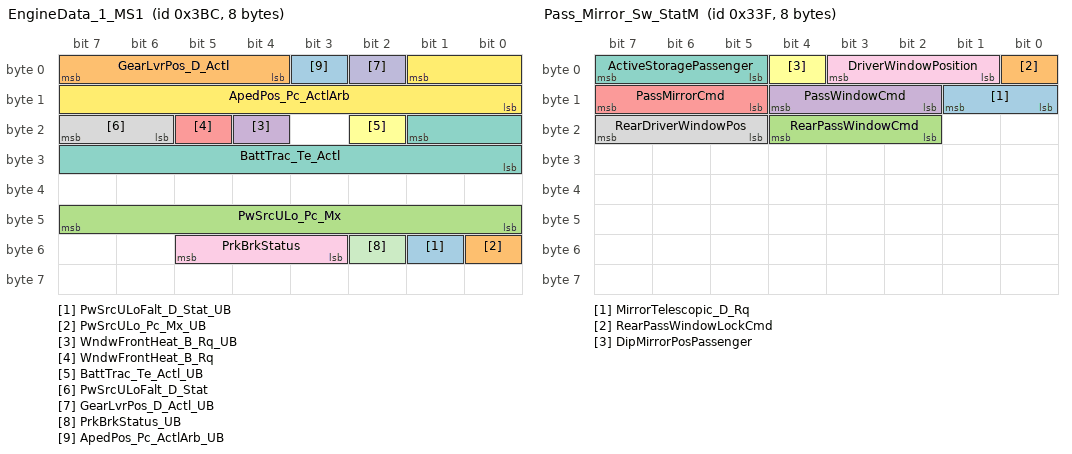
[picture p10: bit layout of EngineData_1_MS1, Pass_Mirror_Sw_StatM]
BO_ 956 EngineData_1_MS1: 8 GWM
 SG_ PwSrcULoFalt_D_Stat_UB : 49|1@0+ (1,0) [0|1] "SED"  HVAC_RCCM
 SG_ PwSrcULo_Pc_Mx_UB : 48|1@0+ (1,0) [0|1] "SED"  HVAC_RCCM
 SG_ PwSrcULo_Pc_Mx : 47|8@0+ (0.4,0) [0|101.6] "%"  HVAC_RCCM
 SG_ WndwFrontHeat_B_Rq_UB : 20|1@0+ (1,0) [0|1] "SED"  HVAC_RCCM
 SG_ WndwFrontHeat_B_Rq : 21|1@0+ (1,0) [0|1] "SED"  HVAC_RCCM
 SG_ BattTrac_Te_Actl_UB : 18|1@0+ (1,0) [0|1] "SED"  HVAC_RCCM
 SG_ BattTrac_Te_Actl : 17|10@0+ (0.5,-50) [-50|460.5] "degC"  HVAC_RCCM
 SG_ PwSrcULoFalt_D_Stat : 23|2@0+ (1,0) [0|3] "SED"  HVAC_RCCM
 SG_ PrkBrkStatus : 53|3@0+ (1,0) [0|7] "SED"  HVAC_RCCM
 SG_ GearLvrPos_D_Actl_UB : 2|1@0+ (1,0) [0|1] "SED"  TRM,SCMB_PSM,HVAC_RCCM,RGTM,DSM,SCMG,SCMH,DDM,PDM
 SG_ PrkBrkStatus_UB : 50|1@0+ (1,0) [0|1] "SED"  HVAC_RCCM
 SG_ ApedPos_Pc_ActlArb : 1|10@0+ (0.1,0) [0|102.3] "%"  HVAC_RCCM
 SG_ ApedPos_Pc_ActlArb_UB : 3|1@0+ (1,0) [0|1] "SED"  HVAC_RCCM
 SG_ GearLvrPos_D_Actl : 7|4@0+ (1,0) [0|15] "SED"  TRM,SCMB_PSM,HVAC_RCCM,RGTM,DSM,SCMG,SCMH,DDM,PDM

BO_ 831 Pass_Mirror_Sw_StatM: 8 DDM
 SG_ MirrorTelescopic_D_Rq : 9|2@0+ (1,0) [0|3] "SED"  PDM,GWM
 SG_ RearPassWindowLockCmd : 0|1@0+ (1,0) [0|1] "SED"  GWM,PDM
 SG_ RearPassWindowCmd : 20|3@0+ (1,0) [0|7] "SED"  GWM,PDM
 SG_ PassWindowCmd : 12|3@0+ (1,0) [0|7] "SED"  GWM,PDM
 SG_ PassMirrorCmd : 15|3@0+ (1,0) [0|7] "SED"  GWM,PDM
 SG_ DipMirrorPosPassenger : 4|1@0+ (1,0) [0|1] "SED"  GWM,PDM
 SG_ ActiveStoragePassenger : 7|3@0+ (1,0) [0|7] "SED"  GWM,PDM
 SG_ RearDriverWindowPos : 23|3@0+ (1,0) [0|7] "SED"  HVAC_RCCM,GWM
 SG_ DriverWindowPosition : 3|3@0+ (1,0) [0|7] "SED"  HVAC_RCCM,GWM

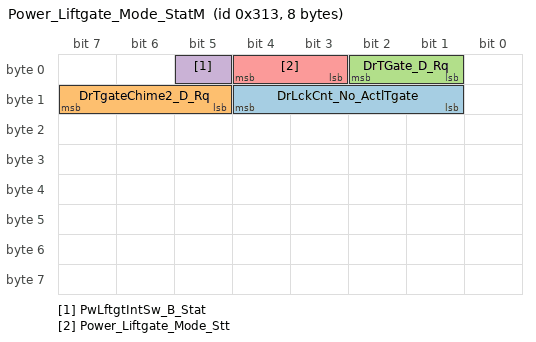
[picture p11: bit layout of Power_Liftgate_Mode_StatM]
BO_ 787 Power_Liftgate_Mode_StatM: 8 RGTM
 SG_ DrLckCnt_No_ActlTgate : 12|4@0+ (1,0) [0|15] "unitless"  GENERIC,GWM
 SG_ DrTgateChime2_D_Rq : 15|3@0+ (1,0) [0|7] "SED"  GENERIC,GWM
 SG_ DrTGate_D_Rq : 2|2@0+ (1,0) [0|3] "SED"  HVAC_RCCM,GWM
 SG_ PwLftgtIntSw_B_Stat : 5|1@0+ (1,0) [0|1] "SED"  GENERIC,GWM
 SG_ Power_Liftgate_Mode_Stt : 4|2@0+ (1,0) [0|3] "SED"  GENERIC,GWM

CM_ SG_ 376 EngAout_Aa_Actl "Signal not transmitted on HEV variants.";
CM_ SG_ 1068 AirCondRec_B_Rq "Signal not transmitted on diesel variants.";
CM_ SG_ 1068 AirCondClutch_B_Stats "Signal not transmitted on diesel variants.";
CM_ SG_ 964 FohEng_D_Rq "Signal not transmitted on vehicles that do not have the fuel operated heater feature.";
CM_ SG_ 964 GearRvrse_D_Actl "Do not implement GearRvrse_D_Actl  until eTracker 8804151 is approved, 11/24/09";
CM_ SG_ 964 MetricActv_B_Actl "0 =Inactive(English), 1=Active(Metric)";
CM_ BO_ 2015 "OBDII Request ($7DF) messages are for FNOS 1.0.1 only.
Diagnostic Functional Addressing ($7DF) and Dual Rate Periodic messages are for FNOS I3 only.";
CM_ SG_ 857 LHS_Temp_Disp_Digit3 "Added for MY 08";
CM_ SG_ 857 LHS_Temp_Disp_Digit2 "Added for MY 08";
CM_ SG_ 857 LHS_Temp_Disp_Digit1 "Added for MY 08";
CM_ SG_ 857 EATC_LHS_Unit "Added for MY 08";
CM_ SG_ 854 RHS_Temp_Display_Digit3 "Added for MY 08";
CM_ SG_ 854 RHS_Temp_Display_Digit2 "Added for MY 08";
CM_ SG_ 854 RHS_Temp_Display_Digit1 "Added for MY 08";
CM_ SG_ 854 LHS_Temp_Display_Digit3 "Added for MY 08";
CM_ SG_ 854 LHS_Temp_Display_Digit2 "Added for MY 08";
CM_ SG_ 854 LHS_Temp_Display_Digit1 "Added for MY 08";
CM_ SG_ 854 EATC_RHS_Units "Added for MY 08";
CM_ SG_ 854 EATC_LHS_Units "Added for MY 08";
CM_ SG_ 534 WhlRotatRr_No_Cnt "DCR 1833 to update Tx from GWM to EP100ms. Wheel Count signals are used by complex algorithm to determine Tire Pressure by Location & can't change from 20msec. (jweinfur)";
CM_ SG_ 534 WhlRotatRl_No_Cnt "DCR 1833 to update Tx from GWM to EP100ms. Wheel Count signals are used by complex algorithm to determine Tire Pressure by Location & can't change from 20msec. (jweinfur)";
CM_ SG_ 534 WhlRotatFr_No_Cnt "DCR 1833 to update Tx from GWM to EP100ms. Wheel Count signals are used by complex algorithm to determine Tire Pressure by Location & can't change from 20msec. (jweinfur)";
CM_ SG_ 534 WhlRotatFl_No_Cnt "DCR 1833 to update Tx from GWM to EP100ms. Wheel Count signals are used by complex algorithm to determine Tire Pressure by Location & can't change from 20msec. (jweinfur)";
CM_ SG_ 772 Memory_Feedback_Rqst "Updated to 1 bit for CGEA, Not backwards compatible";
CM_ SG_ 1070 HiElPwInhbt_B_Stat "Signal not transmitted on HEV programs";
CM_ SG_ 1070 Reserve_UB "Reserve for legacy VehVActlEng_D_Qf";
CM_ SG_ 1050 Outside_Air_Temp_Stat "Filtered value, i.e. same as disply for customer";
CM_ SG_ 947 Dimming_Lvl "Refer to Vehicle Interior Illum Dimming Ctrl Sys Eng Spec, Table 2

";
CM_ SG_ 947 PrkBrkActv_B_Actl "Signal not transmitted on vehicles with electric park brake. ";
CM_ BO_ 1126 "HS3 APIM Sync Gen3 Tx 0x463.  FrameGateway to 0x466 on HS1, HS2, HS3 and MS1.";
CM_ BO_ 1125 "HS3 APIM Sync Gen3 Tx 0x462.  FrameGateway to 0x465 on HS1, HS2, HS3 and MS1.";
CM_ BO_ 1127 "HS3 APIM Sync Gen3 Tx 0x464.  FrameGateway to 0x467 on HS1, HS2, HS3 and MS1.";
CM_ BO_ 828 "Set GenSigSendType = NoSigSendType (Cyclic) for the following signals, D.Card 3/31/08
Driver_Lock_Sw_Stat
";
CM_ SG_ 1034 VehicleGGCCData "RCMGenSigTimeout=6000";
BA_DEF_ BO_  "FrameRouting" STRING ;
BA_DEF_ BO_  "FrameGatewayNetwork" STRING ;
BA_DEF_ BO_  "NetworkInitialization" ENUM  "No","Yes";
BA_DEF_ BO_  "FrameGatewayId" HEX 0 1407;
BA_DEF_ BO_  "EventRateOfChange" INT 10 10000;
BA_DEF_ BO_  "GenMsgStartDelayTime" INT 0 10000;
BA_DEF_ BO_  "GenMsgNrOfRepetition" INT 0 100;
BA_DEF_ BO_  "GenMsgDelayTime" INT 0 1000;
BA_DEF_ BO_  "GenMsgCycleTime" INT 0 100000;
BA_DEF_ BO_  "GenMsgSendType" ENUM  "FixedPeriodic","Event","EnabledPeriodic","NotUsed","NotUsed","EventPeriodic","NotUsed","NotUsed","NoMsgSendType";
BA_DEF_ SG_  "U_CD764_MY2022_Tx" ENUM  "No","Yes";
BA_DEF_ SG_  "U_U55X_MY2022_Tx" ENUM  "No","Yes";
BA_DEF_ SG_  "U_CD542_MY2021_Tx" ENUM  "No","Yes";
BA_DEF_ SG_  "ECGUsedTxSignal" ENUM  "No","Yes";
BA_DEF_ SG_  "U_T6_MCA_MY2020_Tx" ENUM  "No","Yes";
BA_DEF_ SG_  "U_P702_MY2021_Tx" ENUM  "No","Yes";
BA_DEF_ SG_  "U_CX727_MY2021_Tx" ENUM  "No","Yes";
BA_DEF_ SG_  "U_CD764_MY2022_Rx" ENUM  "No","Yes";
BA_DEF_ SG_  "U_U55X_MY2022_Rx" ENUM  "No","Yes";
BA_DEF_ SG_  "U_CD542_MY2021_Rx" ENUM  "No","Yes";
BA_DEF_ SG_  "ECGUsedRxSignal" ENUM  "No","Yes";
BA_DEF_ SG_  "U_T6_MCA_MY2020_Rx" ENUM  "No","Yes";
BA_DEF_ SG_  "U_P702_MY2021_Rx" ENUM  "No","Yes";
BA_DEF_ SG_  "U_CX727_MY2021_Rx" ENUM  "No","Yes";
BA_DEF_ SG_  "GenSigStartValue" HEX 0 268435455;
BA_DEF_ SG_  "MetaData" ENUM  "No","Yes";
BA_DEF_ SG_  "ContentDependant" ENUM  "No","Yes";
BA_DEF_ SG_  "GenSigStartValueInteger" INT 0 1000000000;
BA_DEF_ SG_  "UsedOnPgmDBC" ENUM  "No","Yes";
BA_DEF_ SG_  "WakeupSignal" ENUM  "No","Yes";
BA_DEF_ SG_  "GenSigInactiveValue" INT 0 100000;
BA_DEF_ SG_  "GenSigSendType" ENUM  "Cyclic","OnWrite","vector_leerstring","OnChange","vector_leerstring","IfActive","vector_leerstring","NoSigSendType";
BA_DEF_ BO_  "OvtpPushApplication" ENUM  "FALSE","TRUE";
BA_DEF_ BO_  "SCP_FreshnessValueLength" INT 0 512;
BA_DEF_ BO_  "SCP_FreshnessValueTxLength" INT 0 512;
BA_DEF_ BO_  "SCP_AuthInfoTxLength" INT 0 512;
BA_DEF_ BO_  "GenMsgRoutingTimeoutTime" INT 0 5000;
BA_DEF_ BO_  "MessageGateway" ENUM  "No","Yes";
BA_DEF_ BO_  "NmAsrMessage" ENUM  "No","Yes";
BA_DEF_ BO_  "DiagState" ENUM  "No","Yes";
BA_DEF_ BO_  "TpTxIndex" INT 0 536870911;
BA_DEF_ BO_  "DiagRequest" ENUM  "No","Yes";
BA_DEF_ BO_  "DiagResponse" ENUM  "No","Yes";
BA_DEF_ BO_  "NmMessage" ENUM  "No","Yes";
BA_DEF_ BO_  "GenMsgILSupport" ENUM  "No","Yes";
BA_DEF_DEF_  "FrameRouting" "";
BA_DEF_DEF_  "FrameGatewayNetwork" "NONE";
BA_DEF_DEF_  "NetworkInitialization" "Yes";
BA_DEF_DEF_  "FrameGatewayId" 0;
BA_DEF_DEF_  "EventRateOfChange" 10000;
BA_DEF_DEF_  "GenMsgStartDelayTime" 0;
BA_DEF_DEF_  "GenMsgNrOfRepetition" 1;
BA_DEF_DEF_  "GenMsgDelayTime" 20;
BA_DEF_DEF_  "GenMsgCycleTime" 0;
BA_DEF_DEF_  "GenMsgSendType" "NoMsgSendType";
BA_DEF_DEF_  "U_CD764_MY2022_Tx" "No";
BA_DEF_DEF_  "U_U55X_MY2022_Tx" "No";
BA_DEF_DEF_  "U_CD542_MY2021_Tx" "No";
BA_DEF_DEF_  "ECGUsedTxSignal" "No";
BA_DEF_DEF_  "U_T6_MCA_MY2020_Tx" "No";
BA_DEF_DEF_  "U_P702_MY2021_Tx" "No";
BA_DEF_DEF_  "U_CX727_MY2021_Tx" "No";
BA_DEF_DEF_  "U_CD764_MY2022_Rx" "No";
BA_DEF_DEF_  "U_U55X_MY2022_Rx" "No";
BA_DEF_DEF_  "U_CD542_MY2021_Rx" "No";
BA_DEF_DEF_  "ECGUsedRxSignal" "No";
BA_DEF_DEF_  "U_T6_MCA_MY2020_Rx" "No";
BA_DEF_DEF_  "U_P702_MY2021_Rx" "No";
BA_DEF_DEF_  "U_CX727_MY2021_Rx" "No";
BA_DEF_DEF_  "GenSigStartValue" 0;
BA_DEF_DEF_  "MetaData" "No";
BA_DEF_DEF_  "ContentDependant" "No";
BA_DEF_DEF_  "GenSigStartValueInteger" 0;
BA_DEF_DEF_  "UsedOnPgmDBC" "Yes";
BA_DEF_DEF_  "WakeupSignal" "No";
BA_DEF_DEF_  "GenSigInactiveValue" 0;
BA_DEF_DEF_  "GenSigSendType" "NoSigSendType";
BA_DEF_DEF_  "OvtpPushApplication" "FALSE";
BA_DEF_DEF_  "SCP_FreshnessValueLength" 64;
BA_DEF_DEF_  "SCP_FreshnessValueTxLength" 11;
BA_DEF_DEF_  "SCP_AuthInfoTxLength" 53;
BA_DEF_DEF_  "GenMsgRoutingTimeoutTime" 0;
BA_DEF_DEF_  "MessageGateway" "No";
BA_DEF_DEF_  "NmAsrMessage" "No";
BA_DEF_DEF_  "DiagState" "No";
BA_DEF_DEF_  "TpTxIndex" 0;
BA_DEF_DEF_  "DiagRequest" "No";
BA_DEF_DEF_  "DiagResponse" "No";
BA_DEF_DEF_  "NmMessage" "No";
BA_DEF_DEF_  "GenMsgILSupport" "Yes";
BA_ "FrameRouting" BO_ 376 "FD1_CAN,0x178;";
BA_ "FrameGatewayNetwork" BO_ 376 "FD1_CAN";
BA_ "FrameGatewayId" BO_ 376 376;
BA_ "FrameRouting" BO_ 951 "HS1_CAN,0x3B7;";
BA_ "FrameGatewayNetwork" BO_ 951 "HS1_CAN";
BA_ "FrameGatewayId" BO_ 951 951;
BA_ "GenMsgCycleTime" BO_ 1068 50;
BA_ "GenMsgSendType" BO_ 1068 0;
BA_ "FrameRouting" BO_ 963 "HS1_CAN,0x3C3;";
BA_ "FrameGatewayNetwork" BO_ 963 "HS1_CAN";
BA_ "FrameGatewayId" BO_ 963 963;
BA_ "GenMsgCycleTime" BO_ 964 200;
BA_ "GenMsgSendType" BO_ 964 5;
BA_ "NetworkInitialization" BO_ 1843 0;
BA_ "GenMsgDelayTime" BO_ 1843 0;
BA_ "GenMsgSendType" BO_ 1843 1;
BA_ "DiagRequest" BO_ 1843 1;
BA_ "GenMsgILSupport" BO_ 1843 0;
BA_ "NetworkInitialization" BO_ 1851 0;
BA_ "GenMsgDelayTime" BO_ 1851 0;
BA_ "GenMsgSendType" BO_ 1851 1;
BA_ "DiagResponse" BO_ 1851 1;
BA_ "GenMsgILSupport" BO_ 1851 0;
BA_ "NetworkInitialization" BO_ 1411 0;
BA_ "GenMsgCycleTime" BO_ 1411 1000;
BA_ "GenMsgSendType" BO_ 1411 0;
BA_ "NmAsrMessage" BO_ 1411 1;
BA_ "GenMsgILSupport" BO_ 1411 0;
BA_ "GenMsgStartDelayTime" BO_ 993 100;
BA_ "GenMsgCycleTime" BO_ 993 1000;
BA_ "GenMsgSendType" BO_ 993 5;
BA_ "NetworkInitialization" BO_ 1881 0;
BA_ "GenMsgDelayTime" BO_ 1881 0;
BA_ "GenMsgSendType" BO_ 1881 1;
BA_ "DiagResponse" BO_ 1881 1;
BA_ "GenMsgILSupport" BO_ 1881 0;
BA_ "NetworkInitialization" BO_ 1873 0;
BA_ "GenMsgDelayTime" BO_ 1873 0;
BA_ "GenMsgSendType" BO_ 1873 1;
BA_ "DiagRequest" BO_ 1873 1;
BA_ "GenMsgILSupport" BO_ 1873 0;
BA_ "NetworkInitialization" BO_ 2015 0;
BA_ "GenMsgDelayTime" BO_ 2015 0;
BA_ "GenMsgSendType" BO_ 2015 1;
BA_ "DiagState" BO_ 2015 1;
BA_ "GenMsgILSupport" BO_ 2015 0;
BA_ "GenMsgCycleTime" BO_ 806 100;
BA_ "GenMsgSendType" BO_ 806 0;
BA_ "FrameRouting" BO_ 950 "HS1_CAN,0x3B6;";
BA_ "FrameGatewayNetwork" BO_ 950 "HS1_CAN";
BA_ "FrameGatewayId" BO_ 950 950;
BA_ "FrameRouting" BO_ 857 "HS3_CAN,0x363;";
BA_ "FrameGatewayNetwork" BO_ 857 "HS3_CAN";
BA_ "FrameGatewayId" BO_ 857 867;
BA_ "FrameRouting" BO_ 856 "HS3_CAN,0x362;";
BA_ "FrameGatewayNetwork" BO_ 856 "HS3_CAN";
BA_ "FrameGatewayId" BO_ 856 866;
BA_ "GenMsgCycleTime" BO_ 854 1000;
BA_ "GenMsgSendType" BO_ 854 5;
BA_ "GenMsgDelayTime" BO_ 534 10;
BA_ "GenMsgCycleTime" BO_ 534 100;
BA_ "GenMsgSendType" BO_ 534 0;
BA_ "GenMsgRoutingTimeoutTime" BO_ 534 60;
BA_ "MessageGateway" BO_ 534 1;
BA_ "GenMsgCycleTime" BO_ 772 1000;
BA_ "GenMsgSendType" BO_ 772 5;
BA_ "GenMsgCycleTime" BO_ 1070 100;
BA_ "GenMsgSendType" BO_ 1070 5;
BA_ "GenMsgCycleTime" BO_ 1050 1000;
BA_ "GenMsgSendType" BO_ 1050 5;
BA_ "NetworkInitialization" BO_ 1856 0;
BA_ "GenMsgDelayTime" BO_ 1856 0;
BA_ "GenMsgSendType" BO_ 1856 1;
BA_ "DiagRequest" BO_ 1856 1;
BA_ "GenMsgILSupport" BO_ 1856 0;
BA_ "NetworkInitialization" BO_ 1864 0;
BA_ "GenMsgDelayTime" BO_ 1864 0;
BA_ "GenMsgSendType" BO_ 1864 1;
BA_ "DiagResponse" BO_ 1864 1;
BA_ "GenMsgILSupport" BO_ 1864 0;
BA_ "NetworkInitialization" BO_ 1937 0;
BA_ "GenMsgDelayTime" BO_ 1937 0;
BA_ "GenMsgSendType" BO_ 1937 1;
BA_ "DiagRequest" BO_ 1937 1;
BA_ "GenMsgILSupport" BO_ 1937 0;
BA_ "FrameRouting" BO_ 947 "HS1_CAN,0x3B3;";
BA_ "FrameGatewayNetwork" BO_ 947 "HS1_CAN";
BA_ "FrameGatewayId" BO_ 947 947;
BA_ "NetworkInitialization" BO_ 1841 0;
BA_ "GenMsgDelayTime" BO_ 1841 0;
BA_ "GenMsgSendType" BO_ 1841 1;
BA_ "DiagRequest" BO_ 1841 1;
BA_ "GenMsgILSupport" BO_ 1841 0;
BA_ "FrameRouting" BO_ 1126 "HS3_CAN,0x463;";
BA_ "FrameGatewayNetwork" BO_ 1126 "HS3_CAN";
BA_ "FrameGatewayId" BO_ 1126 1123;
BA_ "FrameRouting" BO_ 1125 "HS3_CAN,0x462;";
BA_ "FrameGatewayNetwork" BO_ 1125 "HS3_CAN";
BA_ "FrameGatewayId" BO_ 1125 1122;
BA_ "FrameRouting" BO_ 992 "HS3_CAN,0x3E0;";
BA_ "FrameGatewayNetwork" BO_ 992 "HS3_CAN";
BA_ "FrameGatewayId" BO_ 992 992;
BA_ "FrameRouting" BO_ 1127 "HS3_CAN,0x464;";
BA_ "FrameGatewayNetwork" BO_ 1127 "HS3_CAN";
BA_ "FrameGatewayId" BO_ 1127 1124;
BA_ "GenMsgCycleTime" BO_ 999 1000;
BA_ "GenMsgSendType" BO_ 999 5;
BA_ "NetworkInitialization" BO_ 2027 0;
BA_ "GenMsgDelayTime" BO_ 2027 0;
BA_ "GenMsgSendType" BO_ 2027 1;
BA_ "DiagResponse" BO_ 2027 1;
BA_ "GenMsgILSupport" BO_ 2027 0;
BA_ "NetworkInitialization" BO_ 2019 0;
BA_ "GenMsgDelayTime" BO_ 2019 0;
BA_ "GenMsgSendType" BO_ 2019 1;
BA_ "DiagRequest" BO_ 2019 1;
BA_ "GenMsgILSupport" BO_ 2019 0;
BA_ "GenMsgCycleTime" BO_ 862 1000;
BA_ "GenMsgSendType" BO_ 862 5;
BA_ "GenMsgCycleTime" BO_ 828 1000;
BA_ "GenMsgSendType" BO_ 828 5;
BA_ "NetworkInitialization" BO_ 1909 0;
BA_ "GenMsgDelayTime" BO_ 1909 0;
BA_ "GenMsgSendType" BO_ 1909 1;
BA_ "DiagRequest" BO_ 1909 1;
BA_ "GenMsgILSupport" BO_ 1909 0;
BA_ "NetworkInitialization" BO_ 1917 0;
BA_ "GenMsgDelayTime" BO_ 1917 0;
BA_ "GenMsgSendType" BO_ 1917 1;
BA_ "DiagResponse" BO_ 1917 1;
BA_ "GenMsgILSupport" BO_ 1917 0;
BA_ "NetworkInitialization" BO_ 1860 0;
BA_ "GenMsgDelayTime" BO_ 1860 0;
BA_ "GenMsgSendType" BO_ 1860 1;
BA_ "DiagRequest" BO_ 1860 1;
BA_ "GenMsgILSupport" BO_ 1860 0;
BA_ "NetworkInitialization" BO_ 1868 0;
BA_ "GenMsgDelayTime" BO_ 1868 0;
BA_ "GenMsgSendType" BO_ 1868 1;
BA_ "DiagResponse" BO_ 1868 1;
BA_ "GenMsgILSupport" BO_ 1868 0;
BA_ "NetworkInitialization" BO_ 1814 0;
BA_ "GenMsgDelayTime" BO_ 1814 0;
BA_ "GenMsgSendType" BO_ 1814 1;
BA_ "DiagRequest" BO_ 1814 1;
BA_ "GenMsgILSupport" BO_ 1814 0;
BA_ "NetworkInitialization" BO_ 1822 0;
BA_ "GenMsgDelayTime" BO_ 1822 0;
BA_ "GenMsgSendType" BO_ 1822 1;
BA_ "DiagResponse" BO_ 1822 1;
BA_ "GenMsgILSupport" BO_ 1822 0;
BA_ "GenMsgStartDelayTime" BO_ 826 100;
BA_ "GenMsgCycleTime" BO_ 826 100;
BA_ "GenMsgSendType" BO_ 826 5;
BA_ "GenMsgCycleTime" BO_ 1098 50;
BA_ "GenMsgSendType" BO_ 1098 0;
BA_ "GenMsgCycleTime" BO_ 853 1000;
BA_ "GenMsgSendType" BO_ 853 5;
BA_ "FrameRouting" BO_ 1034 "HS1_CAN,0x40A;";
BA_ "FrameGatewayNetwork" BO_ 1034 "HS1_CAN";
BA_ "FrameGatewayId" BO_ 1034 1034;
BA_ "GenMsgCycleTime" BO_ 956 50;
BA_ "GenMsgSendType" BO_ 956 0;
BA_ "GenMsgStartDelayTime" BO_ 831 200;
BA_ "GenMsgCycleTime" BO_ 831 1000;
BA_ "GenMsgSendType" BO_ 831 5;
BA_ "GenMsgCycleTime" BO_ 787 1000;
BA_ "GenMsgSendType" BO_ 787 5;
BA_ "ContentDependant" SG_ 376 EngAout_Aa_Actl 1;
BA_ "U_CD764_MY2022_Rx" SG_ 376 HvacHtrCore2_Te_Actl 1;
BA_ "U_U55X_MY2022_Rx" SG_ 376 HvacHtrCore2_Te_Actl 1;
BA_ "U_CD542_MY2021_Rx" SG_ 376 HvacHtrCore2_Te_Actl 1;
BA_ "U_P702_MY2021_Rx" SG_ 376 HvacHtrCore2_Te_Actl 1;
BA_ "U_CX727_MY2021_Rx" SG_ 376 HvacHtrCore2_Te_Actl 1;
BA_ "GenSigStartValueInteger" SG_ 376 HvacHtrCore2_Te_Actl 200;
BA_ "U_CD764_MY2022_Rx" SG_ 376 AirAmbTe_D_Qf 1;
BA_ "U_U55X_MY2022_Rx" SG_ 376 AirAmbTe_D_Qf 1;
BA_ "U_CD542_MY2021_Rx" SG_ 376 AirAmbTe_D_Qf 1;
BA_ "U_T6_MCA_MY2020_Rx" SG_ 376 AirAmbTe_D_Qf 1;
BA_ "U_P702_MY2021_Rx" SG_ 376 AirAmbTe_D_Qf 1;
BA_ "U_CX727_MY2021_Rx" SG_ 376 AirAmbTe_D_Qf 1;
BA_ "GenSigStartValue" SG_ 376 AirAmbTe_D_Qf 1;
BA_ "MetaData" SG_ 376 AirAmbTe_D_Qf 1;
BA_ "GenSigStartValueInteger" SG_ 376 AirAmbTe_D_Qf 1;
BA_ "U_CD764_MY2022_Rx" SG_ 376 AirAmb_Te_ActlFilt 1;
BA_ "U_CD542_MY2021_Rx" SG_ 376 AirAmb_Te_ActlFilt 1;
BA_ "U_T6_MCA_MY2020_Rx" SG_ 376 AirAmb_Te_ActlFilt 1;
BA_ "U_P702_MY2021_Rx" SG_ 376 AirAmb_Te_ActlFilt 1;
BA_ "U_CX727_MY2021_Rx" SG_ 376 AirAmb_Te_ActlFilt 1;
BA_ "U_U55X_MY2022_Rx" SG_ 376 AirAmb_Te_ActlFilt 1;
BA_ "GenSigStartValueInteger" SG_ 376 AirAmb_Te_ActlFilt 512;
BA_ "U_CD764_MY2022_Rx" SG_ 376 AirAmb_Te_Actl 1;
BA_ "U_U55X_MY2022_Rx" SG_ 376 AirAmb_Te_Actl 1;
BA_ "U_CD542_MY2021_Rx" SG_ 376 AirAmb_Te_Actl 1;
BA_ "U_T6_MCA_MY2020_Rx" SG_ 376 AirAmb_Te_Actl 1;
BA_ "U_P702_MY2021_Rx" SG_ 376 AirAmb_Te_Actl 1;
BA_ "U_CX727_MY2021_Rx" SG_ 376 AirAmb_Te_Actl 1;
BA_ "GenSigStartValueInteger" SG_ 376 AirAmb_Te_Actl 512;
BA_ "U_U55X_MY2022_Rx" SG_ 951 TirePress_Info_MaxInd 1;
BA_ "U_T6_MCA_MY2020_Rx" SG_ 951 TirePress_Info_MaxInd 1;
BA_ "U_P702_MY2021_Rx" SG_ 951 TirePress_Info_MaxInd 1;
BA_ "U_CX727_MY2021_Rx" SG_ 951 TirePress_Info_MaxInd 1;
BA_ "U_U55X_MY2022_Rx" SG_ 951 TirePress_Info_Index 1;
BA_ "U_T6_MCA_MY2020_Rx" SG_ 951 TirePress_Info_Index 1;
BA_ "U_P702_MY2021_Rx" SG_ 951 TirePress_Info_Index 1;
BA_ "U_CX727_MY2021_Rx" SG_ 951 TirePress_Info_Index 1;
BA_ "U_U55X_MY2022_Rx" SG_ 951 TirePress_Info_ID 1;
BA_ "U_T6_MCA_MY2020_Rx" SG_ 951 TirePress_Info_ID 1;
BA_ "U_P702_MY2021_Rx" SG_ 951 TirePress_Info_ID 1;
BA_ "U_CX727_MY2021_Rx" SG_ 951 TirePress_Info_ID 1;
BA_ "U_CD764_MY2022_Rx" SG_ 1068 HvacAirFullOut_B_Rq_UB 1;
BA_ "U_U55X_MY2022_Rx" SG_ 1068 HvacAirFullOut_B_Rq_UB 1;
BA_ "U_CD542_MY2021_Rx" SG_ 1068 HvacAirFullOut_B_Rq_UB 1;
BA_ "U_T6_MCA_MY2020_Rx" SG_ 1068 HvacAirFullOut_B_Rq_UB 1;
BA_ "U_P702_MY2021_Rx" SG_ 1068 HvacAirFullOut_B_Rq_UB 1;
BA_ "U_CD764_MY2022_Rx" SG_ 1068 HvacAirFullOut_B_Rq 1;
BA_ "U_U55X_MY2022_Rx" SG_ 1068 HvacAirFullOut_B_Rq 1;
BA_ "U_CD542_MY2021_Rx" SG_ 1068 HvacAirFullOut_B_Rq 1;
BA_ "U_T6_MCA_MY2020_Rx" SG_ 1068 HvacAirFullOut_B_Rq 1;
BA_ "U_P702_MY2021_Rx" SG_ 1068 HvacAirFullOut_B_Rq 1;
BA_ "U_CD764_MY2022_Rx" SG_ 1068 HvacCmprLim_D_Stat_UB 1;
BA_ "U_U55X_MY2022_Rx" SG_ 1068 HvacCmprLim_D_Stat_UB 1;
BA_ "U_CD542_MY2021_Rx" SG_ 1068 HvacCmprLim_D_Stat_UB 1;
BA_ "U_T6_MCA_MY2020_Rx" SG_ 1068 HvacCmprLim_D_Stat_UB 1;
BA_ "U_CD764_MY2022_Rx" SG_ 1068 HvacCmprLim_D_Stat 1;
BA_ "U_U55X_MY2022_Rx" SG_ 1068 HvacCmprLim_D_Stat 1;
BA_ "U_CD542_MY2021_Rx" SG_ 1068 HvacCmprLim_D_Stat 1;
BA_ "U_T6_MCA_MY2020_Rx" SG_ 1068 HvacCmprLim_D_Stat 1;
BA_ "U_CX727_MY2021_Rx" SG_ 1068 HvacAirFlw_B_RqBatt_UB 1;
BA_ "U_CX727_MY2021_Rx" SG_ 1068 HvacAirFlw_B_RqBatt 1;
BA_ "WakeupSignal" SG_ 1068 HvacAirFlw_B_RqBatt 1;
BA_ "U_CD764_MY2022_Rx" SG_ 1068 HvacRec_D_RqMxBatt_UB 1;
BA_ "U_U55X_MY2022_Rx" SG_ 1068 HvacRec_D_RqMxBatt_UB 1;
BA_ "U_CD542_MY2021_Rx" SG_ 1068 HvacRec_D_RqMxBatt_UB 1;
BA_ "U_CX727_MY2021_Rx" SG_ 1068 HvacRec_D_RqMxBatt_UB 1;
BA_ "U_CD764_MY2022_Rx" SG_ 1068 HvacRec_D_RqMxBatt 1;
BA_ "U_U55X_MY2022_Rx" SG_ 1068 HvacRec_D_RqMxBatt 1;
BA_ "U_CD542_MY2021_Rx" SG_ 1068 HvacRec_D_RqMxBatt 1;
BA_ "U_CX727_MY2021_Rx" SG_ 1068 HvacRec_D_RqMxBatt 1;
BA_ "GenSigStartValue" SG_ 1068 HvacRec_D_RqMxBatt 10;
BA_ "GenSigStartValueInteger" SG_ 1068 HvacRec_D_RqMxBatt 10;
BA_ "U_CD764_MY2022_Rx" SG_ 1068 Batt_Lo_SoC_B_UB 1;
BA_ "U_U55X_MY2022_Rx" SG_ 1068 Batt_Lo_SoC_B_UB 1;
BA_ "U_CX727_MY2021_Rx" SG_ 1068 Batt_Lo_SoC_B_UB 1;
BA_ "U_CD542_MY2021_Rx" SG_ 1068 Batt_Lo_SoC_B_UB 1;
BA_ "U_T6_MCA_MY2020_Rx" SG_ 1068 Batt_Lo_SoC_B_UB 1;
BA_ "U_P702_MY2021_Rx" SG_ 1068 Batt_Lo_SoC_B_UB 1;
BA_ "U_CD764_MY2022_Rx" SG_ 1068 Batt_Lo_SoC_B 1;
BA_ "U_U55X_MY2022_Rx" SG_ 1068 Batt_Lo_SoC_B 1;
BA_ "U_CX727_MY2021_Rx" SG_ 1068 Batt_Lo_SoC_B 1;
BA_ "U_CD542_MY2021_Rx" SG_ 1068 Batt_Lo_SoC_B 1;
BA_ "U_T6_MCA_MY2020_Rx" SG_ 1068 Batt_Lo_SoC_B 1;
BA_ "U_P702_MY2021_Rx" SG_ 1068 Batt_Lo_SoC_B 1;
BA_ "U_CD764_MY2022_Rx" SG_ 1068 Batt_Crit_SoC_B_UB 1;
BA_ "U_U55X_MY2022_Rx" SG_ 1068 Batt_Crit_SoC_B_UB 1;
BA_ "U_CX727_MY2021_Rx" SG_ 1068 Batt_Crit_SoC_B_UB 1;
BA_ "U_CD542_MY2021_Rx" SG_ 1068 Batt_Crit_SoC_B_UB 1;
BA_ "U_T6_MCA_MY2020_Rx" SG_ 1068 Batt_Crit_SoC_B_UB 1;
BA_ "U_P702_MY2021_Rx" SG_ 1068 Batt_Crit_SoC_B_UB 1;
BA_ "U_CD764_MY2022_Rx" SG_ 1068 Batt_Crit_SoC_B 1;
BA_ "U_U55X_MY2022_Rx" SG_ 1068 Batt_Crit_SoC_B 1;
BA_ "U_CX727_MY2021_Rx" SG_ 1068 Batt_Crit_SoC_B 1;
BA_ "U_CD542_MY2021_Rx" SG_ 1068 Batt_Crit_SoC_B 1;
BA_ "U_T6_MCA_MY2020_Rx" SG_ 1068 Batt_Crit_SoC_B 1;
BA_ "U_P702_MY2021_Rx" SG_ 1068 Batt_Crit_SoC_B 1;
BA_ "U_CD764_MY2022_Rx" SG_ 1068 Shed_T_Eng_Off_B_UB 1;
BA_ "U_CX727_MY2021_Rx" SG_ 1068 Shed_T_Eng_Off_B_UB 1;
BA_ "U_U55X_MY2022_Rx" SG_ 1068 Shed_T_Eng_Off_B_UB 1;
BA_ "U_CD542_MY2021_Rx" SG_ 1068 Shed_T_Eng_Off_B_UB 1;
BA_ "U_T6_MCA_MY2020_Rx" SG_ 1068 Shed_T_Eng_Off_B_UB 1;
BA_ "U_P702_MY2021_Rx" SG_ 1068 Shed_T_Eng_Off_B_UB 1;
BA_ "U_CD764_MY2022_Rx" SG_ 1068 Shed_T_Eng_Off_B 1;
BA_ "U_CX727_MY2021_Rx" SG_ 1068 Shed_T_Eng_Off_B 1;
BA_ "U_U55X_MY2022_Rx" SG_ 1068 Shed_T_Eng_Off_B 1;
BA_ "U_CD542_MY2021_Rx" SG_ 1068 Shed_T_Eng_Off_B 1;
BA_ "U_T6_MCA_MY2020_Rx" SG_ 1068 Shed_T_Eng_Off_B 1;
BA_ "U_P702_MY2021_Rx" SG_ 1068 Shed_T_Eng_Off_B 1;
BA_ "U_CX727_MY2021_Rx" SG_ 1068 Shed_Level_Req_UB 1;
BA_ "U_CD764_MY2022_Rx" SG_ 1068 Shed_Level_Req_UB 1;
BA_ "U_U55X_MY2022_Rx" SG_ 1068 Shed_Level_Req_UB 1;
BA_ "U_CD542_MY2021_Rx" SG_ 1068 Shed_Level_Req_UB 1;
BA_ "U_T6_MCA_MY2020_Rx" SG_ 1068 Shed_Level_Req_UB 1;
BA_ "U_P702_MY2021_Rx" SG_ 1068 Shed_Level_Req_UB 1;
BA_ "U_CX727_MY2021_Rx" SG_ 1068 Shed_Level_Req 1;
BA_ "U_CD764_MY2022_Rx" SG_ 1068 Shed_Level_Req 1;
BA_ "U_U55X_MY2022_Rx" SG_ 1068 Shed_Level_Req 1;
BA_ "U_CD542_MY2021_Rx" SG_ 1068 Shed_Level_Req 1;
BA_ "U_T6_MCA_MY2020_Rx" SG_ 1068 Shed_Level_Req 1;
BA_ "U_P702_MY2021_Rx" SG_ 1068 Shed_Level_Req 1;
BA_ "WakeupSignal" SG_ 1068 Shed_Level_Req 1;
BA_ "U_CD764_MY2022_Rx" SG_ 1068 Shed_Feature_Group_ID_UB 1;
BA_ "U_CX727_MY2021_Rx" SG_ 1068 Shed_Feature_Group_ID_UB 1;
BA_ "U_U55X_MY2022_Rx" SG_ 1068 Shed_Feature_Group_ID_UB 1;
BA_ "U_CD542_MY2021_Rx" SG_ 1068 Shed_Feature_Group_ID_UB 1;
BA_ "U_T6_MCA_MY2020_Rx" SG_ 1068 Shed_Feature_Group_ID_UB 1;
BA_ "U_P702_MY2021_Rx" SG_ 1068 Shed_Feature_Group_ID_UB 1;
BA_ "U_CD764_MY2022_Rx" SG_ 1068 Shed_Feature_Group_ID 1;
BA_ "U_CX727_MY2021_Rx" SG_ 1068 Shed_Feature_Group_ID 1;
BA_ "U_U55X_MY2022_Rx" SG_ 1068 Shed_Feature_Group_ID 1;
BA_ "U_CD542_MY2021_Rx" SG_ 1068 Shed_Feature_Group_ID 1;
BA_ "U_T6_MCA_MY2020_Rx" SG_ 1068 Shed_Feature_Group_ID 1;
BA_ "U_P702_MY2021_Rx" SG_ 1068 Shed_Feature_Group_ID 1;
BA_ "WakeupSignal" SG_ 1068 Shed_Feature_Group_ID 1;
BA_ "U_CD764_MY2022_Rx" SG_ 1068 Shed_Drain_Eng_Off_B_UB 1;
BA_ "U_CX727_MY2021_Rx" SG_ 1068 Shed_Drain_Eng_Off_B_UB 1;
BA_ "U_U55X_MY2022_Rx" SG_ 1068 Shed_Drain_Eng_Off_B_UB 1;
BA_ "U_CD542_MY2021_Rx" SG_ 1068 Shed_Drain_Eng_Off_B_UB 1;
BA_ "U_T6_MCA_MY2020_Rx" SG_ 1068 Shed_Drain_Eng_Off_B_UB 1;
BA_ "U_P702_MY2021_Rx" SG_ 1068 Shed_Drain_Eng_Off_B_UB 1;
BA_ "U_CD764_MY2022_Rx" SG_ 1068 Shed_Drain_Eng_Off_B 1;
BA_ "U_CX727_MY2021_Rx" SG_ 1068 Shed_Drain_Eng_Off_B 1;
BA_ "U_U55X_MY2022_Rx" SG_ 1068 Shed_Drain_Eng_Off_B 1;
BA_ "U_CD542_MY2021_Rx" SG_ 1068 Shed_Drain_Eng_Off_B 1;
BA_ "U_T6_MCA_MY2020_Rx" SG_ 1068 Shed_Drain_Eng_Off_B 1;
BA_ "U_P702_MY2021_Rx" SG_ 1068 Shed_Drain_Eng_Off_B 1;
BA_ "U_CX727_MY2021_Rx" SG_ 1068 HvacAir_Flw_EstBatt_UB 1;
BA_ "U_CX727_MY2021_Rx" SG_ 1068 HvacAir_Flw_EstBatt 1;
BA_ "U_CD764_MY2022_Rx" SG_ 1068 AirCondRec_B_Rq_UB 1;
BA_ "U_U55X_MY2022_Rx" SG_ 1068 AirCondRec_B_Rq_UB 1;
BA_ "U_CD542_MY2021_Rx" SG_ 1068 AirCondRec_B_Rq_UB 1;
BA_ "U_T6_MCA_MY2020_Rx" SG_ 1068 AirCondRec_B_Rq_UB 1;
BA_ "U_P702_MY2021_Rx" SG_ 1068 AirCondRec_B_Rq_UB 1;
BA_ "U_CX727_MY2021_Rx" SG_ 1068 AirCondRec_B_Rq_UB 1;
BA_ "U_CD764_MY2022_Rx" SG_ 1068 AirCondFluidHi_P_Actl_UB 1;
BA_ "U_U55X_MY2022_Rx" SG_ 1068 AirCondFluidHi_P_Actl_UB 1;
BA_ "U_CD542_MY2021_Rx" SG_ 1068 AirCondFluidHi_P_Actl_UB 1;
BA_ "U_T6_MCA_MY2020_Rx" SG_ 1068 AirCondFluidHi_P_Actl_UB 1;
BA_ "U_P702_MY2021_Rx" SG_ 1068 AirCondFluidHi_P_Actl_UB 1;
BA_ "U_CX727_MY2021_Rx" SG_ 1068 AirCondFluidHi_P_Actl_UB 1;
BA_ "U_CD764_MY2022_Rx" SG_ 1068 AirCondClutch_B_Stats_UB 1;
BA_ "U_U55X_MY2022_Rx" SG_ 1068 AirCondClutch_B_Stats_UB 1;
BA_ "U_CD542_MY2021_Rx" SG_ 1068 AirCondClutch_B_Stats_UB 1;
BA_ "U_T6_MCA_MY2020_Rx" SG_ 1068 AirCondClutch_B_Stats_UB 1;
BA_ "U_P702_MY2021_Rx" SG_ 1068 AirCondClutch_B_Stats_UB 1;
BA_ "U_CX727_MY2021_Rx" SG_ 1068 AirCondClutch_B_Stats_UB 1;
BA_ "U_CD764_MY2022_Rx" SG_ 1068 AirCondRec_B_Rq 1;
BA_ "U_U55X_MY2022_Rx" SG_ 1068 AirCondRec_B_Rq 1;
BA_ "U_CD542_MY2021_Rx" SG_ 1068 AirCondRec_B_Rq 1;
BA_ "U_T6_MCA_MY2020_Rx" SG_ 1068 AirCondRec_B_Rq 1;
BA_ "U_P702_MY2021_Rx" SG_ 1068 AirCondRec_B_Rq 1;
BA_ "U_CX727_MY2021_Rx" SG_ 1068 AirCondRec_B_Rq 1;
BA_ "ContentDependant" SG_ 1068 AirCondRec_B_Rq 1;
BA_ "U_CD764_MY2022_Rx" SG_ 1068 AirCondFluidHi_P_Actl 1;
BA_ "U_U55X_MY2022_Rx" SG_ 1068 AirCondFluidHi_P_Actl 1;
BA_ "U_CD542_MY2021_Rx" SG_ 1068 AirCondFluidHi_P_Actl 1;
BA_ "U_T6_MCA_MY2020_Rx" SG_ 1068 AirCondFluidHi_P_Actl 1;
BA_ "U_P702_MY2021_Rx" SG_ 1068 AirCondFluidHi_P_Actl 1;
BA_ "U_CX727_MY2021_Rx" SG_ 1068 AirCondFluidHi_P_Actl 1;
BA_ "U_CD764_MY2022_Rx" SG_ 1068 AirCondClutch_B_Stats 1;
BA_ "U_U55X_MY2022_Rx" SG_ 1068 AirCondClutch_B_Stats 1;
BA_ "U_CD542_MY2021_Rx" SG_ 1068 AirCondClutch_B_Stats 1;
BA_ "U_T6_MCA_MY2020_Rx" SG_ 1068 AirCondClutch_B_Stats 1;
BA_ "U_P702_MY2021_Rx" SG_ 1068 AirCondClutch_B_Stats 1;
BA_ "U_CX727_MY2021_Rx" SG_ 1068 AirCondClutch_B_Stats 1;
BA_ "ContentDependant" SG_ 1068 AirCondClutch_B_Stats 1;
BA_ "WakeupSignal" SG_ 963 ImpactEvntFdbck_D_Stat 1;
BA_ "U_CD764_MY2022_Rx" SG_ 963 PudLampPsngr_D_Rq 1;
BA_ "U_CD542_MY2021_Rx" SG_ 963 PudLampPsngr_D_Rq 1;
BA_ "U_T6_MCA_MY2020_Rx" SG_ 963 PudLampPsngr_D_Rq 1;
BA_ "U_P702_MY2021_Rx" SG_ 963 PudLampPsngr_D_Rq 1;
BA_ "U_U55X_MY2022_Rx" SG_ 963 PudLampPsngr_D_Rq 1;
BA_ "WakeupSignal" SG_ 963 HomeSafeLtChime_B_Rq 1;
BA_ "U_U55X_MY2022_Rx" SG_ 963 StopLghtOn_B_Stat 1;
BA_ "U_CX727_MY2021_Rx" SG_ 963 StopLghtOn_B_Stat 1;
BA_ "U_CD542_MY2021_Rx" SG_ 963 StopLghtOn_B_Stat 1;
BA_ "U_T6_MCA_MY2020_Rx" SG_ 963 StopLghtOn_B_Stat 1;
BA_ "U_P702_MY2021_Rx" SG_ 963 StopLghtOn_B_Stat 1;
BA_ "WakeupSignal" SG_ 963 StopLghtOn_B_Stat 1;
BA_ "U_CD542_MY2021_Rx" SG_ 963 RvrseLghtOn_B_Stat 1;
BA_ "U_T6_MCA_MY2020_Rx" SG_ 963 RvrseLghtOn_B_Stat 1;
BA_ "U_P702_MY2021_Rx" SG_ 963 RvrseLghtOn_B_Stat 1;
BA_ "U_CD542_MY2021_Rx" SG_ 963 PrkLght_D_Stat 1;
BA_ "U_T6_MCA_MY2020_Rx" SG_ 963 PrkLght_D_Stat 1;
BA_ "U_P702_MY2021_Rx" SG_ 963 PrkLght_D_Stat 1;
BA_ "WakeupSignal" SG_ 963 PrkLght_D_Stat 1;
BA_ "GenSigStartValue" SG_ 963 HeadLghtSwtch_D_Stat 2;
BA_ "GenSigStartValueInteger" SG_ 963 HeadLghtSwtch_D_Stat 2;
BA_ "WakeupSignal" SG_ 963 HeadLghtSwtch_D_Stat 1;
BA_ "WakeupSignal" SG_ 963 KeyInIgnWarn_B_Cmd 1;
BA_ "GenSigStartValue" SG_ 963 HeadLampLoFrOn_B_Stat 1;
BA_ "GenSigStartValueInteger" SG_ 963 HeadLampLoFrOn_B_Stat 1;
BA_ "GenSigStartValue" SG_ 963 HeadLampLoFlOn_B_Stat 1;
BA_ "GenSigStartValueInteger" SG_ 963 HeadLampLoFlOn_B_Stat 1;
BA_ "WakeupSignal" SG_ 963 Headlamp_On_Wrning_Cmd 1;
BA_ "GenSigStartValue" SG_ 963 HeadLampLoActv_B_Stat 1;
BA_ "GenSigStartValueInteger" SG_ 963 HeadLampLoActv_B_Stat 1;
BA_ "WakeupSignal" SG_ 963 HeadLghtHiOn_B_Stat 1;
BA_ "U_CX727_MY2021_Rx" SG_ 963 Courtesy_BSave_Stat 1;
BA_ "U_CD764_MY2022_Rx" SG_ 963 Courtesy_BSave_Stat 1;
BA_ "U_U55X_MY2022_Rx" SG_ 963 Courtesy_BSave_Stat 1;
BA_ "U_CD542_MY2021_Rx" SG_ 963 Courtesy_BSave_Stat 1;
BA_ "U_T6_MCA_MY2020_Rx" SG_ 963 Courtesy_BSave_Stat 1;
BA_ "U_P702_MY2021_Rx" SG_ 963 Courtesy_BSave_Stat 1;
BA_ "GenSigStartValue" SG_ 963 Courtesy_BSave_Stat 1;
BA_ "GenSigStartValueInteger" SG_ 963 Courtesy_BSave_Stat 1;
BA_ "WakeupSignal" SG_ 963 Courtesy_BSave_Stat 1;
BA_ "WakeupSignal" SG_ 963 PerimeterAlarmChimeRq 1;
BA_ "U_CD764_MY2022_Rx" SG_ 963 PudLampDrv_D_Rq 1;
BA_ "U_CX727_MY2021_Rx" SG_ 963 PudLampDrv_D_Rq 1;
BA_ "U_CD542_MY2021_Rx" SG_ 963 PudLampDrv_D_Rq 1;
BA_ "U_T6_MCA_MY2020_Rx" SG_ 963 PudLampDrv_D_Rq 1;
BA_ "U_P702_MY2021_Rx" SG_ 963 PudLampDrv_D_Rq 1;
BA_ "U_U55X_MY2022_Rx" SG_ 963 PudLampDrv_D_Rq 1;
BA_ "U_U55X_MY2022_Rx" SG_ 963 Perimeter_Alarm_Status 1;
BA_ "U_P702_MY2021_Rx" SG_ 963 Perimeter_Alarm_Status 1;
BA_ "U_CX727_MY2021_Rx" SG_ 963 Perimeter_Alarm_Status 1;
BA_ "U_T6_MCA_MY2020_Rx" SG_ 963 Perimeter_Alarm_Status 1;
BA_ "WakeupSignal" SG_ 963 Perimeter_Alarm_Status 1;
BA_ "U_CX727_MY2021_Rx" SG_ 963 WndwGlbl_D_Cmd 1;
BA_ "U_CD764_MY2022_Rx" SG_ 963 WndwGlbl_D_Cmd 1;
BA_ "U_U55X_MY2022_Rx" SG_ 963 WndwGlbl_D_Cmd 1;
BA_ "U_CD542_MY2021_Rx" SG_ 963 WndwGlbl_D_Cmd 1;
BA_ "U_T6_MCA_MY2020_Rx" SG_ 963 WndwGlbl_D_Cmd 1;
BA_ "U_P702_MY2021_Rx" SG_ 963 WndwGlbl_D_Cmd 1;
BA_ "WakeupSignal" SG_ 963 WndwGlbl_D_Cmd 1;
BA_ "U_CX727_MY2021_Rx" SG_ 963 PudLamp_D_Rq 1;
BA_ "U_CD764_MY2022_Rx" SG_ 963 PudLamp_D_Rq 1;
BA_ "U_U55X_MY2022_Rx" SG_ 963 PudLamp_D_Rq 1;
BA_ "U_CD542_MY2021_Rx" SG_ 963 PudLamp_D_Rq 1;
BA_ "U_T6_MCA_MY2020_Rx" SG_ 963 PudLamp_D_Rq 1;
BA_ "U_P702_MY2021_Rx" SG_ 963 PudLamp_D_Rq 1;
BA_ "WakeupSignal" SG_ 963 PudLamp_D_Rq 1;
BA_ "GenSigSendType" SG_ 964 FohEng_D_Rq 3;
BA_ "GenSigStartValue" SG_ 964 FohEng_D_Rq 2;
BA_ "ContentDependant" SG_ 964 FohEng_D_Rq 1;
BA_ "GenSigStartValueInteger" SG_ 964 FohEng_D_Rq 2;
BA_ "U_U55X_MY2022_Rx" SG_ 964 EcoMode_B_Stat_UB 1;
BA_ "U_T6_MCA_MY2020_Rx" SG_ 964 EcoMode_B_Stat_UB 1;
BA_ "U_T6_MCA_MY2020_Rx" SG_ 964 Cta_D_Rq_UB 1;
BA_ "U_CX727_MY2021_Rx" SG_ 964 Cta_D_Rq_UB 1;
BA_ "U_T6_MCA_MY2020_Rx" SG_ 964 Cta_D_Rq 1;
BA_ "U_CX727_MY2021_Rx" SG_ 964 Cta_D_Rq 1;
BA_ "GenSigSendType" SG_ 964 Cta_D_Rq 3;
BA_ "GenSigStartValue" SG_ 964 Cta_D_Rq 1;
BA_ "GenSigStartValueInteger" SG_ 964 Cta_D_Rq 1;
BA_ "U_CD764_MY2022_Rx" SG_ 964 GearRvrse_D_Actl_UB 1;
BA_ "U_U55X_MY2022_Rx" SG_ 964 GearRvrse_D_Actl_UB 1;
BA_ "U_CD542_MY2021_Rx" SG_ 964 GearRvrse_D_Actl_UB 1;
BA_ "U_T6_MCA_MY2020_Rx" SG_ 964 GearRvrse_D_Actl_UB 1;
BA_ "U_P702_MY2021_Rx" SG_ 964 GearRvrse_D_Actl_UB 1;
BA_ "U_CX727_MY2021_Rx" SG_ 964 GearRvrse_D_Actl_UB 1;
BA_ "U_CD764_MY2022_Rx" SG_ 964 GearRvrse_D_Actl 1;
BA_ "U_U55X_MY2022_Rx" SG_ 964 GearRvrse_D_Actl 1;
BA_ "U_CD542_MY2021_Rx" SG_ 964 GearRvrse_D_Actl 1;
BA_ "U_T6_MCA_MY2020_Rx" SG_ 964 GearRvrse_D_Actl 1;
BA_ "U_P702_MY2021_Rx" SG_ 964 GearRvrse_D_Actl 1;
BA_ "U_CX727_MY2021_Rx" SG_ 964 GearRvrse_D_Actl 1;
BA_ "GenSigSendType" SG_ 964 GearRvrse_D_Actl 3;
BA_ "GenSigStartValue" SG_ 964 GearRvrse_D_Actl 7;
BA_ "GenSigStartValueInteger" SG_ 964 GearRvrse_D_Actl 7;
BA_ "U_T6_MCA_MY2020_Rx" SG_ 964 TurnLghtSwtch_D_Stat_UB 1;
BA_ "U_CX727_MY2021_Rx" SG_ 964 TurnLghtSwtch_D_Stat_UB 1;
BA_ "U_T6_MCA_MY2020_Rx" SG_ 964 TurnLghtSwtch_D_Stat 1;
BA_ "U_CX727_MY2021_Rx" SG_ 964 TurnLghtSwtch_D_Stat 1;
BA_ "GenSigSendType" SG_ 964 TurnLghtSwtch_D_Stat 3;
BA_ "WakeupSignal" SG_ 964 TurnLghtSwtch_D_Stat 1;
BA_ "U_U55X_MY2022_Rx" SG_ 964 Power_Liftgate_Mode_Cmd_UB 1;
BA_ "U_CD542_MY2021_Rx" SG_ 964 Power_Liftgate_Mode_Cmd_UB 1;
BA_ "U_T6_MCA_MY2020_Rx" SG_ 964 Power_Liftgate_Mode_Cmd_UB 1;
BA_ "U_CX727_MY2021_Rx" SG_ 964 Power_Liftgate_Mode_Cmd_UB 1;
BA_ "U_U55X_MY2022_Rx" SG_ 964 Power_Liftgate_Mode_Cmd 1;
BA_ "U_CD542_MY2021_Rx" SG_ 964 Power_Liftgate_Mode_Cmd 1;
BA_ "U_T6_MCA_MY2020_Rx" SG_ 964 Power_Liftgate_Mode_Cmd 1;
BA_ "U_CX727_MY2021_Rx" SG_ 964 Power_Liftgate_Mode_Cmd 1;
BA_ "GenSigSendType" SG_ 964 Power_Liftgate_Mode_Cmd 3;
BA_ "WakeupSignal" SG_ 964 Power_Liftgate_Mode_Cmd 1;
BA_ "U_U55X_MY2022_Rx" SG_ 964 EcoMode_B_Stat 1;
BA_ "U_T6_MCA_MY2020_Rx" SG_ 964 EcoMode_B_Stat 1;
BA_ "GenSigSendType" SG_ 964 EcoMode_B_Stat 3;
BA_ "U_CD764_MY2022_Rx" SG_ 964 MetricActvTe_B_Actl_UB 1;
BA_ "U_U55X_MY2022_Rx" SG_ 964 MetricActvTe_B_Actl_UB 1;
BA_ "U_CD542_MY2021_Rx" SG_ 964 MetricActvTe_B_Actl_UB 1;
BA_ "U_T6_MCA_MY2020_Rx" SG_ 964 MetricActvTe_B_Actl_UB 1;
BA_ "U_P702_MY2021_Rx" SG_ 964 MetricActvTe_B_Actl_UB 1;
BA_ "U_CX727_MY2021_Rx" SG_ 964 MetricActvTe_B_Actl_UB 1;
BA_ "U_CD764_MY2022_Rx" SG_ 964 MetricActvTe_B_Actl 1;
BA_ "U_U55X_MY2022_Rx" SG_ 964 MetricActvTe_B_Actl 1;
BA_ "U_CD542_MY2021_Rx" SG_ 964 MetricActvTe_B_Actl 1;
BA_ "U_T6_MCA_MY2020_Rx" SG_ 964 MetricActvTe_B_Actl 1;
BA_ "U_P702_MY2021_Rx" SG_ 964 MetricActvTe_B_Actl 1;
BA_ "U_CX727_MY2021_Rx" SG_ 964 MetricActvTe_B_Actl 1;
BA_ "GenSigSendType" SG_ 964 MetricActvTe_B_Actl 3;
BA_ "U_CD764_MY2022_Rx" SG_ 964 EngClntTe_D_Qf 1;
BA_ "U_U55X_MY2022_Rx" SG_ 964 EngClntTe_D_Qf 1;
BA_ "U_CD542_MY2021_Rx" SG_ 964 EngClntTe_D_Qf 1;
BA_ "U_T6_MCA_MY2020_Rx" SG_ 964 EngClntTe_D_Qf 1;
BA_ "U_P702_MY2021_Rx" SG_ 964 EngClntTe_D_Qf 1;
BA_ "U_CX727_MY2021_Rx" SG_ 964 EngClntTe_D_Qf 1;
BA_ "GenSigSendType" SG_ 964 EngClntTe_D_Qf 3;
BA_ "MetaData" SG_ 964 EngClntTe_D_Qf 1;
BA_ "U_T6_MCA_MY2020_Rx" SG_ 964 Sod_D_Rq 1;
BA_ "U_CX727_MY2021_Rx" SG_ 964 Sod_D_Rq 1;
BA_ "GenSigSendType" SG_ 964 Sod_D_Rq 3;
BA_ "GenSigStartValue" SG_ 964 Sod_D_Rq 2;
BA_ "GenSigStartValueInteger" SG_ 964 Sod_D_Rq 2;
BA_ "U_CD764_MY2022_Rx" SG_ 964 MetricActv_B_Actl 1;
BA_ "U_U55X_MY2022_Rx" SG_ 964 MetricActv_B_Actl 1;
BA_ "U_CD542_MY2021_Rx" SG_ 964 MetricActv_B_Actl 1;
BA_ "U_T6_MCA_MY2020_Rx" SG_ 964 MetricActv_B_Actl 1;
BA_ "U_P702_MY2021_Rx" SG_ 964 MetricActv_B_Actl 1;
BA_ "U_CX727_MY2021_Rx" SG_ 964 MetricActv_B_Actl 1;
BA_ "GenSigSendType" SG_ 964 MetricActv_B_Actl 3;
BA_ "U_CD764_MY2022_Rx" SG_ 964 EngClnt_Te_Actl 1;
BA_ "U_U55X_MY2022_Rx" SG_ 964 EngClnt_Te_Actl 1;
BA_ "U_CD542_MY2021_Rx" SG_ 964 EngClnt_Te_Actl 1;
BA_ "U_T6_MCA_MY2020_Rx" SG_ 964 EngClnt_Te_Actl 1;
BA_ "U_P702_MY2021_Rx" SG_ 964 EngClnt_Te_Actl 1;
BA_ "U_CX727_MY2021_Rx" SG_ 964 EngClnt_Te_Actl 1;
BA_ "GenSigSendType" SG_ 964 EngClnt_Te_Actl 3;
BA_ "U_CD764_MY2022_Rx" SG_ 964 MetricActv_B_Actl_UB 1;
BA_ "U_U55X_MY2022_Rx" SG_ 964 MetricActv_B_Actl_UB 1;
BA_ "U_CD542_MY2021_Rx" SG_ 964 MetricActv_B_Actl_UB 1;
BA_ "U_T6_MCA_MY2020_Rx" SG_ 964 MetricActv_B_Actl_UB 1;
BA_ "U_P702_MY2021_Rx" SG_ 964 MetricActv_B_Actl_UB 1;
BA_ "U_CX727_MY2021_Rx" SG_ 964 MetricActv_B_Actl_UB 1;
BA_ "U_CD764_MY2022_Rx" SG_ 964 EngClnt_Te_Actl_UB 1;
BA_ "U_U55X_MY2022_Rx" SG_ 964 EngClnt_Te_Actl_UB 1;
BA_ "U_CD542_MY2021_Rx" SG_ 964 EngClnt_Te_Actl_UB 1;
BA_ "U_T6_MCA_MY2020_Rx" SG_ 964 EngClnt_Te_Actl_UB 1;
BA_ "U_P702_MY2021_Rx" SG_ 964 EngClnt_Te_Actl_UB 1;
BA_ "U_CX727_MY2021_Rx" SG_ 964 EngClnt_Te_Actl_UB 1;
BA_ "U_CD542_MY2021_Rx" SG_ 964 OCSSensrDataUpperLim_UB 1;
BA_ "U_T6_MCA_MY2020_Rx" SG_ 964 OCSSensrDataUpperLim_UB 1;
BA_ "U_CX727_MY2021_Rx" SG_ 964 OCSSensrDataUpperLim_UB 1;
BA_ "U_CD764_MY2022_Rx" SG_ 964 OCSSensrDataUpperLim_UB 1;
BA_ "U_U55X_MY2022_Rx" SG_ 964 OCSSensrDataUpperLim_UB 1;
BA_ "U_P702_MY2021_Rx" SG_ 964 OCSSensrDataUpperLim_UB 1;
BA_ "U_CD542_MY2021_Rx" SG_ 964 OCSSensrDataUpperLim 1;
BA_ "U_T6_MCA_MY2020_Rx" SG_ 964 OCSSensrDataUpperLim 1;
BA_ "U_CX727_MY2021_Rx" SG_ 964 OCSSensrDataUpperLim 1;
BA_ "U_CD764_MY2022_Rx" SG_ 964 OCSSensrDataUpperLim 1;
BA_ "U_U55X_MY2022_Rx" SG_ 964 OCSSensrDataUpperLim 1;
BA_ "U_P702_MY2021_Rx" SG_ 964 OCSSensrDataUpperLim 1;
BA_ "GenSigSendType" SG_ 964 OCSSensrDataUpperLim 3;
BA_ "U_CD542_MY2021_Rx" SG_ 964 OCSSensrDataLowerLim_UB 1;
BA_ "U_T6_MCA_MY2020_Rx" SG_ 964 OCSSensrDataLowerLim_UB 1;
BA_ "U_CX727_MY2021_Rx" SG_ 964 OCSSensrDataLowerLim_UB 1;
BA_ "U_CD764_MY2022_Rx" SG_ 964 OCSSensrDataLowerLim_UB 1;
BA_ "U_U55X_MY2022_Rx" SG_ 964 OCSSensrDataLowerLim_UB 1;
BA_ "U_P702_MY2021_Rx" SG_ 964 OCSSensrDataLowerLim_UB 1;
BA_ "GenSigSendType" SG_ 964 PrkAid_D_Falt 3;
BA_ "U_CD542_MY2021_Rx" SG_ 964 OCSSensrDataLowerLim 1;
BA_ "U_T6_MCA_MY2020_Rx" SG_ 964 OCSSensrDataLowerLim 1;
BA_ "U_CX727_MY2021_Rx" SG_ 964 OCSSensrDataLowerLim 1;
BA_ "U_CD764_MY2022_Rx" SG_ 964 OCSSensrDataLowerLim 1;
BA_ "U_U55X_MY2022_Rx" SG_ 964 OCSSensrDataLowerLim 1;
BA_ "U_P702_MY2021_Rx" SG_ 964 OCSSensrDataLowerLim 1;
BA_ "GenSigSendType" SG_ 964 OCSSensrDataLowerLim 3;
BA_ "U_CD764_MY2022_Rx" SG_ 964 WiprFront_D_Stat_UB 1;
BA_ "U_U55X_MY2022_Rx" SG_ 964 WiprFront_D_Stat_UB 1;
BA_ "U_CD542_MY2021_Rx" SG_ 964 WiprFront_D_Stat_UB 1;
BA_ "U_P702_MY2021_Rx" SG_ 964 WiprFront_D_Stat_UB 1;
BA_ "U_T6_MCA_MY2020_Rx" SG_ 964 WiprFront_D_Stat_UB 1;
BA_ "U_CX727_MY2021_Rx" SG_ 964 WiprFront_D_Stat_UB 1;
BA_ "U_CD764_MY2022_Rx" SG_ 964 WiprFront_D_Stat 1;
BA_ "U_U55X_MY2022_Rx" SG_ 964 WiprFront_D_Stat 1;
BA_ "U_CD542_MY2021_Rx" SG_ 964 WiprFront_D_Stat 1;
BA_ "U_P702_MY2021_Rx" SG_ 964 WiprFront_D_Stat 1;
BA_ "U_T6_MCA_MY2020_Rx" SG_ 964 WiprFront_D_Stat 1;
BA_ "U_CX727_MY2021_Rx" SG_ 964 WiprFront_D_Stat 1;
BA_ "GenSigSendType" SG_ 964 WiprFront_D_Stat 3;
BA_ "GenSigStartValue" SG_ 964 WiprFront_D_Stat 15;
BA_ "GenSigStartValueInteger" SG_ 964 WiprFront_D_Stat 15;
BA_ "U_CD764_MY2022_Rx" SG_ 964 CamraDefog_B_Req_UB 1;
BA_ "U_U55X_MY2022_Rx" SG_ 964 CamraDefog_B_Req_UB 1;
BA_ "U_CD542_MY2021_Rx" SG_ 964 CamraDefog_B_Req_UB 1;
BA_ "U_CX727_MY2021_Rx" SG_ 964 CamraDefog_B_Req_UB 1;
BA_ "U_T6_MCA_MY2020_Rx" SG_ 964 Sod_D_Rq_UB 1;
BA_ "U_CX727_MY2021_Rx" SG_ 964 Sod_D_Rq_UB 1;
BA_ "U_CD764_MY2022_Rx" SG_ 964 CamraDefog_B_Req 1;
BA_ "U_U55X_MY2022_Rx" SG_ 964 CamraDefog_B_Req 1;
BA_ "U_CD542_MY2021_Rx" SG_ 964 CamraDefog_B_Req 1;
BA_ "U_CX727_MY2021_Rx" SG_ 964 CamraDefog_B_Req 1;
BA_ "GenSigSendType" SG_ 964 CamraDefog_B_Req 3;
BA_ "U_CD764_MY2022_Rx" SG_ 1843 TesterPhysicalReqHVAC_RCCM 1;
BA_ "U_U55X_MY2022_Rx" SG_ 1843 TesterPhysicalReqHVAC_RCCM 1;
BA_ "U_CD542_MY2021_Rx" SG_ 1843 TesterPhysicalReqHVAC_RCCM 1;
BA_ "U_T6_MCA_MY2020_Rx" SG_ 1843 TesterPhysicalReqHVAC_RCCM 1;
BA_ "U_P702_MY2021_Rx" SG_ 1843 TesterPhysicalReqHVAC_RCCM 1;
BA_ "U_CX727_MY2021_Rx" SG_ 1843 TesterPhysicalReqHVAC_RCCM 1;
BA_ "GenSigSendType" SG_ 1843 TesterPhysicalReqHVAC_RCCM 3;
BA_ "U_CD764_MY2022_Tx" SG_ 1851 TesterPhysicalResHVAC_RCCM 1;
BA_ "U_U55X_MY2022_Tx" SG_ 1851 TesterPhysicalResHVAC_RCCM 1;
BA_ "U_CD542_MY2021_Tx" SG_ 1851 TesterPhysicalResHVAC_RCCM 1;
BA_ "U_T6_MCA_MY2020_Tx" SG_ 1851 TesterPhysicalResHVAC_RCCM 1;
BA_ "U_P702_MY2021_Tx" SG_ 1851 TesterPhysicalResHVAC_RCCM 1;
BA_ "U_CX727_MY2021_Tx" SG_ 1851 TesterPhysicalResHVAC_RCCM 1;
BA_ "GenSigSendType" SG_ 1851 TesterPhysicalResHVAC_RCCM 3;
BA_ "U_CD764_MY2022_Tx" SG_ 1411 HVAC_GWOnBoardTester 1;
BA_ "U_U55X_MY2022_Tx" SG_ 1411 HVAC_GWOnBoardTester 1;
BA_ "U_CD542_MY2021_Tx" SG_ 1411 HVAC_GWOnBoardTester 1;
BA_ "U_T6_MCA_MY2020_Tx" SG_ 1411 HVAC_GWOnBoardTester 1;
BA_ "U_P702_MY2021_Tx" SG_ 1411 HVAC_GWOnBoardTester 1;
BA_ "U_CX727_MY2021_Tx" SG_ 1411 HVAC_GWOnBoardTester 1;
BA_ "GenSigStartValue" SG_ 1411 HVAC_GWOnBoardTester 255;
BA_ "ContentDependant" SG_ 1411 HVAC_GWOnBoardTester 1;
BA_ "GenSigStartValueInteger" SG_ 1411 HVAC_GWOnBoardTester 255;
BA_ "U_CD764_MY2022_Tx" SG_ 1411 HVAC_GWNMProxy 1;
BA_ "U_U55X_MY2022_Tx" SG_ 1411 HVAC_GWNMProxy 1;
BA_ "U_CD542_MY2021_Tx" SG_ 1411 HVAC_GWNMProxy 1;
BA_ "U_T6_MCA_MY2020_Tx" SG_ 1411 HVAC_GWNMProxy 1;
BA_ "U_P702_MY2021_Tx" SG_ 1411 HVAC_GWNMProxy 1;
BA_ "U_CX727_MY2021_Tx" SG_ 1411 HVAC_GWNMProxy 1;
BA_ "GenSigStartValue" SG_ 1411 HVAC_GWNMProxy 255;
BA_ "ContentDependant" SG_ 1411 HVAC_GWNMProxy 1;
BA_ "GenSigStartValueInteger" SG_ 1411 HVAC_GWNMProxy 255;
BA_ "U_CD764_MY2022_Tx" SG_ 1411 HVAC_AutoSarNMReserved4 1;
BA_ "U_U55X_MY2022_Tx" SG_ 1411 HVAC_AutoSarNMReserved4 1;
BA_ "U_CD542_MY2021_Tx" SG_ 1411 HVAC_AutoSarNMReserved4 1;
BA_ "U_T6_MCA_MY2020_Tx" SG_ 1411 HVAC_AutoSarNMReserved4 1;
BA_ "U_P702_MY2021_Tx" SG_ 1411 HVAC_AutoSarNMReserved4 1;
BA_ "U_CX727_MY2021_Tx" SG_ 1411 HVAC_AutoSarNMReserved4 1;
BA_ "GenSigStartValue" SG_ 1411 HVAC_AutoSarNMReserved4 255;
BA_ "ContentDependant" SG_ 1411 HVAC_AutoSarNMReserved4 1;
BA_ "GenSigStartValueInteger" SG_ 1411 HVAC_AutoSarNMReserved4 255;
BA_ "U_CD764_MY2022_Tx" SG_ 1411 HVAC_AutoSarNMReserved3 1;
BA_ "U_U55X_MY2022_Tx" SG_ 1411 HVAC_AutoSarNMReserved3 1;
BA_ "U_CD542_MY2021_Tx" SG_ 1411 HVAC_AutoSarNMReserved3 1;
BA_ "U_T6_MCA_MY2020_Tx" SG_ 1411 HVAC_AutoSarNMReserved3 1;
BA_ "U_P702_MY2021_Tx" SG_ 1411 HVAC_AutoSarNMReserved3 1;
BA_ "U_CX727_MY2021_Tx" SG_ 1411 HVAC_AutoSarNMReserved3 1;
BA_ "GenSigStartValue" SG_ 1411 HVAC_AutoSarNMReserved3 255;
BA_ "ContentDependant" SG_ 1411 HVAC_AutoSarNMReserved3 1;
BA_ "GenSigStartValueInteger" SG_ 1411 HVAC_AutoSarNMReserved3 255;
BA_ "U_CD764_MY2022_Tx" SG_ 1411 HVAC_AutoSarNMReserved2 1;
BA_ "U_U55X_MY2022_Tx" SG_ 1411 HVAC_AutoSarNMReserved2 1;
BA_ "U_CD542_MY2021_Tx" SG_ 1411 HVAC_AutoSarNMReserved2 1;
BA_ "U_T6_MCA_MY2020_Tx" SG_ 1411 HVAC_AutoSarNMReserved2 1;
BA_ "U_P702_MY2021_Tx" SG_ 1411 HVAC_AutoSarNMReserved2 1;
BA_ "U_CX727_MY2021_Tx" SG_ 1411 HVAC_AutoSarNMReserved2 1;
BA_ "GenSigStartValue" SG_ 1411 HVAC_AutoSarNMReserved2 255;
BA_ "ContentDependant" SG_ 1411 HVAC_AutoSarNMReserved2 1;
BA_ "GenSigStartValueInteger" SG_ 1411 HVAC_AutoSarNMReserved2 255;
BA_ "U_CD764_MY2022_Tx" SG_ 1411 HVAC_AutoSarNMReserved 1;
BA_ "U_U55X_MY2022_Tx" SG_ 1411 HVAC_AutoSarNMReserved 1;
BA_ "U_CD542_MY2021_Tx" SG_ 1411 HVAC_AutoSarNMReserved 1;
BA_ "U_T6_MCA_MY2020_Tx" SG_ 1411 HVAC_AutoSarNMReserved 1;
BA_ "U_P702_MY2021_Tx" SG_ 1411 HVAC_AutoSarNMReserved 1;
BA_ "U_CX727_MY2021_Tx" SG_ 1411 HVAC_AutoSarNMReserved 1;
BA_ "GenSigStartValue" SG_ 1411 HVAC_AutoSarNMReserved 255;
BA_ "ContentDependant" SG_ 1411 HVAC_AutoSarNMReserved 1;
BA_ "GenSigStartValueInteger" SG_ 1411 HVAC_AutoSarNMReserved 255;
BA_ "U_CD764_MY2022_Tx" SG_ 1411 HVAC_AutoSarNMNodeId 1;
BA_ "U_U55X_MY2022_Tx" SG_ 1411 HVAC_AutoSarNMNodeId 1;
BA_ "U_CD542_MY2021_Tx" SG_ 1411 HVAC_AutoSarNMNodeId 1;
BA_ "U_T6_MCA_MY2020_Tx" SG_ 1411 HVAC_AutoSarNMNodeId 1;
BA_ "U_P702_MY2021_Tx" SG_ 1411 HVAC_AutoSarNMNodeId 1;
BA_ "U_CX727_MY2021_Tx" SG_ 1411 HVAC_AutoSarNMNodeId 1;
BA_ "GenSigStartValue" SG_ 1411 HVAC_AutoSarNMNodeId 131;
BA_ "ContentDependant" SG_ 1411 HVAC_AutoSarNMNodeId 1;
BA_ "GenSigStartValueInteger" SG_ 1411 HVAC_AutoSarNMNodeId 83;
BA_ "U_CD764_MY2022_Tx" SG_ 1411 HVAC_AutoSarNMControl 1;
BA_ "U_U55X_MY2022_Tx" SG_ 1411 HVAC_AutoSarNMControl 1;
BA_ "U_CD542_MY2021_Tx" SG_ 1411 HVAC_AutoSarNMControl 1;
BA_ "U_T6_MCA_MY2020_Tx" SG_ 1411 HVAC_AutoSarNMControl 1;
BA_ "U_P702_MY2021_Tx" SG_ 1411 HVAC_AutoSarNMControl 1;
BA_ "U_CX727_MY2021_Tx" SG_ 1411 HVAC_AutoSarNMControl 1;
BA_ "ContentDependant" SG_ 1411 HVAC_AutoSarNMControl 1;
BA_ "U_CD764_MY2022_Tx" SG_ 993 EmButtn_D_Stat 1;
BA_ "U_U55X_MY2022_Tx" SG_ 993 EmButtn_D_Stat 1;
BA_ "U_CD542_MY2021_Tx" SG_ 993 EmButtn_D_Stat 1;
BA_ "U_T6_MCA_MY2020_Tx" SG_ 993 EmButtn_D_Stat 1;
BA_ "U_P702_MY2021_Tx" SG_ 993 EmButtn_D_Stat 1;
BA_ "U_CX727_MY2021_Tx" SG_ 993 EmButtn_D_Stat 1;
BA_ "GenSigSendType" SG_ 993 EmButtn_D_Stat 3;
BA_ "U_CD542_MY2021_Tx" SG_ 993 MemStoreMsgTxt_D_Rq 1;
BA_ "U_T6_MCA_MY2020_Tx" SG_ 993 MemStoreMsgTxt_D_Rq 1;
BA_ "GenSigSendType" SG_ 993 MemStoreMsgTxt_D_Rq 3;
BA_ "GenSigSendType" SG_ 993 MemSetButtnMsgTxt_D_Rq 3;
BA_ "U_CD764_MY2022_Tx" SG_ 993 PersStore_D_Actl 1;
BA_ "U_U55X_MY2022_Tx" SG_ 993 PersStore_D_Actl 1;
BA_ "U_CD542_MY2021_Tx" SG_ 993 PersStore_D_Actl 1;
BA_ "U_T6_MCA_MY2020_Tx" SG_ 993 PersStore_D_Actl 1;
BA_ "U_P702_MY2021_Tx" SG_ 993 PersStore_D_Actl 1;
BA_ "U_CX727_MY2021_Tx" SG_ 993 PersStore_D_Actl 1;
BA_ "GenSigSendType" SG_ 993 PersStore_D_Actl 3;
BA_ "U_CD764_MY2022_Tx" SG_ 993 MemSwtch_D_RqRecall 1;
BA_ "U_U55X_MY2022_Tx" SG_ 993 MemSwtch_D_RqRecall 1;
BA_ "U_CD542_MY2021_Tx" SG_ 993 MemSwtch_D_RqRecall 1;
BA_ "U_T6_MCA_MY2020_Tx" SG_ 993 MemSwtch_D_RqRecall 1;
BA_ "U_P702_MY2021_Tx" SG_ 993 MemSwtch_D_RqRecall 1;
BA_ "U_CX727_MY2021_Tx" SG_ 993 MemSwtch_D_RqRecall 1;
BA_ "U_U55X_MY2022_Rx" SG_ 993 MemSwtch_D_RqRecall 1;
BA_ "GenSigSendType" SG_ 993 MemSwtch_D_RqRecall 3;
BA_ "WakeupSignal" SG_ 993 MemSwtch_D_RqRecall 1;
BA_ "U_CD764_MY2022_Tx" SG_ 993 MemSwtch_D_RqAssoc 1;
BA_ "U_U55X_MY2022_Tx" SG_ 993 MemSwtch_D_RqAssoc 1;
BA_ "U_CD542_MY2021_Tx" SG_ 993 MemSwtch_D_RqAssoc 1;
BA_ "U_T6_MCA_MY2020_Tx" SG_ 993 MemSwtch_D_RqAssoc 1;
BA_ "U_P702_MY2021_Tx" SG_ 993 MemSwtch_D_RqAssoc 1;
BA_ "U_CX727_MY2021_Tx" SG_ 993 MemSwtch_D_RqAssoc 1;
BA_ "GenSigSendType" SG_ 993 MemSwtch_D_RqAssoc 3;
BA_ "WakeupSignal" SG_ 993 MemSwtch_D_RqAssoc 1;
BA_ "U_CD764_MY2022_Tx" SG_ 993 PersIndexDsm_D_Actl 1;
BA_ "U_U55X_MY2022_Tx" SG_ 993 PersIndexDsm_D_Actl 1;
BA_ "U_CD542_MY2021_Tx" SG_ 993 PersIndexDsm_D_Actl 1;
BA_ "U_T6_MCA_MY2020_Tx" SG_ 993 PersIndexDsm_D_Actl 1;
BA_ "U_P702_MY2021_Tx" SG_ 993 PersIndexDsm_D_Actl 1;
BA_ "U_CX727_MY2021_Tx" SG_ 993 PersIndexDsm_D_Actl 1;
BA_ "GenSigSendType" SG_ 993 PersIndexDsm_D_Actl 3;
BA_ "GenSigStartValue" SG_ 993 PersIndexDsm_D_Actl 4;
BA_ "GenSigStartValueInteger" SG_ 993 PersIndexDsm_D_Actl 4;
BA_ "U_CD764_MY2022_Tx" SG_ 993 FeatNoDsmActl 1;
BA_ "U_U55X_MY2022_Tx" SG_ 993 FeatNoDsmActl 1;
BA_ "U_CD542_MY2021_Tx" SG_ 993 FeatNoDsmActl 1;
BA_ "U_T6_MCA_MY2020_Tx" SG_ 993 FeatNoDsmActl 1;
BA_ "U_P702_MY2021_Tx" SG_ 993 FeatNoDsmActl 1;
BA_ "U_CX727_MY2021_Tx" SG_ 993 FeatNoDsmActl 1;
BA_ "GenSigSendType" SG_ 993 FeatNoDsmActl 3;
BA_ "U_CD764_MY2022_Tx" SG_ 993 FeatConfigDsmActl 1;
BA_ "U_U55X_MY2022_Tx" SG_ 993 FeatConfigDsmActl 1;
BA_ "U_CD542_MY2021_Tx" SG_ 993 FeatConfigDsmActl 1;
BA_ "U_T6_MCA_MY2020_Tx" SG_ 993 FeatConfigDsmActl 1;
BA_ "U_P702_MY2021_Tx" SG_ 993 FeatConfigDsmActl 1;
BA_ "U_CX727_MY2021_Tx" SG_ 993 FeatConfigDsmActl 1;
BA_ "GenSigSendType" SG_ 993 FeatConfigDsmActl 3;
BA_ "U_U55X_MY2022_Tx" SG_ 1881 TesterPhysicalResRTM 1;
BA_ "U_T6_MCA_MY2020_Tx" SG_ 1881 TesterPhysicalResRTM 1;
BA_ "U_P702_MY2021_Tx" SG_ 1881 TesterPhysicalResRTM 1;
BA_ "U_CX727_MY2021_Tx" SG_ 1881 TesterPhysicalResRTM 1;
BA_ "GenSigSendType" SG_ 1881 TesterPhysicalResRTM 3;
BA_ "U_U55X_MY2022_Rx" SG_ 1873 TesterPhysicalReqRTM 1;
BA_ "U_T6_MCA_MY2020_Rx" SG_ 1873 TesterPhysicalReqRTM 1;
BA_ "U_P702_MY2021_Rx" SG_ 1873 TesterPhysicalReqRTM 1;
BA_ "U_CX727_MY2021_Rx" SG_ 1873 TesterPhysicalReqRTM 1;
BA_ "GenSigSendType" SG_ 1873 TesterPhysicalReqRTM 3;
BA_ "ECGUsedRxSignal" SG_ 2015 TesterFunctionalReq 1;
BA_ "U_CD764_MY2022_Rx" SG_ 2015 TesterFunctionalReq 1;
BA_ "U_CD542_MY2021_Rx" SG_ 2015 TesterFunctionalReq 1;
BA_ "U_T6_MCA_MY2020_Rx" SG_ 2015 TesterFunctionalReq 1;
BA_ "U_CX727_MY2021_Rx" SG_ 2015 TesterFunctionalReq 1;
BA_ "U_P702_MY2021_Rx" SG_ 2015 TesterFunctionalReq 1;
BA_ "U_U55X_MY2022_Rx" SG_ 2015 TesterFunctionalReq 1;
BA_ "GenSigSendType" SG_ 2015 TesterFunctionalReq 3;
BA_ "GenSigSendType" SG_ 806 ClimtHeatRear_D_Rq 3;
BA_ "U_CD764_MY2022_Tx" SG_ 806 ClimtDeltaLoad_Pw_Actl 1;
BA_ "U_U55X_MY2022_Tx" SG_ 806 ClimtDeltaLoad_Pw_Actl 1;
BA_ "U_CD542_MY2021_Tx" SG_ 806 ClimtDeltaLoad_Pw_Actl 1;
BA_ "U_T6_MCA_MY2020_Tx" SG_ 806 ClimtDeltaLoad_Pw_Actl 1;
BA_ "U_CX727_MY2021_Tx" SG_ 806 ClimtDeltaLoad_Pw_Actl 1;
BA_ "GenSigStartValueInteger" SG_ 806 ClimtDeltaLoad_Pw_Actl 32;
BA_ "U_CD764_MY2022_Tx" SG_ 806 StopStrtDrvMde_B_RqBtn 1;
BA_ "U_U55X_MY2022_Tx" SG_ 806 StopStrtDrvMde_B_RqBtn 1;
BA_ "U_CD542_MY2021_Tx" SG_ 806 StopStrtDrvMde_B_RqBtn 1;
BA_ "U_T6_MCA_MY2020_Tx" SG_ 806 StopStrtDrvMde_B_RqBtn 1;
BA_ "U_CX727_MY2021_Tx" SG_ 806 StopStrtDrvMde_B_RqBtn 1;
BA_ "GenSigSendType" SG_ 806 StopStrtDrvMde_B_RqBtn 3;
BA_ "U_CD764_MY2022_Tx" SG_ 806 HvacHtrCore_Te_Rq 1;
BA_ "U_U55X_MY2022_Tx" SG_ 806 HvacHtrCore_Te_Rq 1;
BA_ "U_CD542_MY2021_Tx" SG_ 806 HvacHtrCore_Te_Rq 1;
BA_ "U_T6_MCA_MY2020_Tx" SG_ 806 HvacHtrCore_Te_Rq 1;
BA_ "U_CX727_MY2021_Tx" SG_ 806 HvacHtrCore_Te_Rq 1;
BA_ "U_CD764_MY2022_Tx" SG_ 806 WndwFrontHeat_B_Stat 1;
BA_ "U_U55X_MY2022_Tx" SG_ 806 WndwFrontHeat_B_Stat 1;
BA_ "U_CD542_MY2021_Tx" SG_ 806 WndwFrontHeat_B_Stat 1;
BA_ "U_T6_MCA_MY2020_Tx" SG_ 806 WndwFrontHeat_B_Stat 1;
BA_ "U_CX727_MY2021_Tx" SG_ 806 WndwFrontHeat_B_Stat 1;
BA_ "U_CX727_MY2021_Tx" SG_ 806 HtrCorePump_B_Rq 1;
BA_ "U_CD764_MY2022_Tx" SG_ 806 ClimtHeat_D_Rq 1;
BA_ "U_U55X_MY2022_Tx" SG_ 806 ClimtHeat_D_Rq 1;
BA_ "U_CD542_MY2021_Tx" SG_ 806 ClimtHeat_D_Rq 1;
BA_ "U_T6_MCA_MY2020_Tx" SG_ 806 ClimtHeat_D_Rq 1;
BA_ "U_P702_MY2021_Tx" SG_ 806 ClimtHeat_D_Rq 1;
BA_ "U_CX727_MY2021_Tx" SG_ 806 ClimtHeat_D_Rq 1;
BA_ "U_CD764_MY2022_Tx" SG_ 806 ClimtCool_D_Rq 1;
BA_ "U_U55X_MY2022_Tx" SG_ 806 ClimtCool_D_Rq 1;
BA_ "U_CD542_MY2021_Tx" SG_ 806 ClimtCool_D_Rq 1;
BA_ "U_T6_MCA_MY2020_Tx" SG_ 806 ClimtCool_D_Rq 1;
BA_ "U_P702_MY2021_Tx" SG_ 806 ClimtCool_D_Rq 1;
BA_ "U_CX727_MY2021_Tx" SG_ 806 ClimtCool_D_Rq 1;
BA_ "U_CD764_MY2022_Tx" SG_ 806 HvacEvap_Te_Rq 1;
BA_ "U_U55X_MY2022_Tx" SG_ 806 HvacEvap_Te_Rq 1;
BA_ "U_CD542_MY2021_Tx" SG_ 806 HvacEvap_Te_Rq 1;
BA_ "U_T6_MCA_MY2020_Tx" SG_ 806 HvacEvap_Te_Rq 1;
BA_ "U_P702_MY2021_Tx" SG_ 806 HvacEvap_Te_Rq 1;
BA_ "U_CX727_MY2021_Tx" SG_ 806 HvacEvap_Te_Rq 1;
BA_ "GenSigStartValueInteger" SG_ 806 HvacEvap_Te_Rq 400;
BA_ "U_CD764_MY2022_Tx" SG_ 806 HvacEvap_Te_Actl 1;
BA_ "U_U55X_MY2022_Tx" SG_ 806 HvacEvap_Te_Actl 1;
BA_ "U_CD542_MY2021_Tx" SG_ 806 HvacEvap_Te_Actl 1;
BA_ "U_T6_MCA_MY2020_Tx" SG_ 806 HvacEvap_Te_Actl 1;
BA_ "U_P702_MY2021_Tx" SG_ 806 HvacEvap_Te_Actl 1;
BA_ "U_CX727_MY2021_Tx" SG_ 806 HvacEvap_Te_Actl 1;
BA_ "GenSigStartValueInteger" SG_ 806 HvacEvap_Te_Actl 400;
BA_ "U_CD764_MY2022_Tx" SG_ 806 HvacAirCond_B_Rq 1;
BA_ "U_U55X_MY2022_Tx" SG_ 806 HvacAirCond_B_Rq 1;
BA_ "U_CD542_MY2021_Tx" SG_ 806 HvacAirCond_B_Rq 1;
BA_ "U_T6_MCA_MY2020_Tx" SG_ 806 HvacAirCond_B_Rq 1;
BA_ "U_P702_MY2021_Tx" SG_ 806 HvacAirCond_B_Rq 1;
BA_ "U_CX727_MY2021_Tx" SG_ 806 HvacAirCond_B_Rq 1;
BA_ "U_CD764_MY2022_Tx" SG_ 806 HvacEvap_Te_Offst 1;
BA_ "U_U55X_MY2022_Tx" SG_ 806 HvacEvap_Te_Offst 1;
BA_ "U_CD542_MY2021_Tx" SG_ 806 HvacEvap_Te_Offst 1;
BA_ "U_T6_MCA_MY2020_Tx" SG_ 806 HvacEvap_Te_Offst 1;
BA_ "U_P702_MY2021_Tx" SG_ 806 HvacEvap_Te_Offst 1;
BA_ "U_CX727_MY2021_Tx" SG_ 806 HvacEvap_Te_Offst 1;
BA_ "GenSigStartValueInteger" SG_ 806 HvacEvap_Te_Offst 400;
BA_ "U_CD764_MY2022_Tx" SG_ 806 ClimtPw_B_Rq 1;
BA_ "U_U55X_MY2022_Tx" SG_ 806 ClimtPw_B_Rq 1;
BA_ "U_CD542_MY2021_Tx" SG_ 806 ClimtPw_B_Rq 1;
BA_ "U_T6_MCA_MY2020_Tx" SG_ 806 ClimtPw_B_Rq 1;
BA_ "U_CX727_MY2021_Tx" SG_ 806 ClimtPw_B_Rq 1;
BA_ "U_U55X_MY2022_Rx" SG_ 950 RemoteKey_Info_TIC 1;
BA_ "U_T6_MCA_MY2020_Rx" SG_ 950 RemoteKey_Info_TIC 1;
BA_ "U_P702_MY2021_Rx" SG_ 950 RemoteKey_Info_TIC 1;
BA_ "U_CX727_MY2021_Rx" SG_ 950 RemoteKey_Info_TIC 1;
BA_ "U_U55X_MY2022_Rx" SG_ 950 RemoteKey_Info_MaxInd 1;
BA_ "U_T6_MCA_MY2020_Rx" SG_ 950 RemoteKey_Info_MaxInd 1;
BA_ "U_P702_MY2021_Rx" SG_ 950 RemoteKey_Info_MaxInd 1;
BA_ "U_CX727_MY2021_Rx" SG_ 950 RemoteKey_Info_MaxInd 1;
BA_ "U_U55X_MY2022_Rx" SG_ 950 RemoteKey_Info_Index 1;
BA_ "U_T6_MCA_MY2020_Rx" SG_ 950 RemoteKey_Info_Index 1;
BA_ "U_P702_MY2021_Rx" SG_ 950 RemoteKey_Info_Index 1;
BA_ "U_CX727_MY2021_Rx" SG_ 950 RemoteKey_Info_Index 1;
BA_ "U_U55X_MY2022_Rx" SG_ 950 TirePress_Filter_Ctrl 1;
BA_ "U_T6_MCA_MY2020_Rx" SG_ 950 TirePress_Filter_Ctrl 1;
BA_ "U_P702_MY2021_Rx" SG_ 950 TirePress_Filter_Ctrl 1;
BA_ "U_CX727_MY2021_Rx" SG_ 950 TirePress_Filter_Ctrl 1;
BA_ "GenSigStartValue" SG_ 950 TirePress_Filter_Ctrl 2;
BA_ "GenSigStartValueInteger" SG_ 950 TirePress_Filter_Ctrl 2;
BA_ "U_CD764_MY2022_Rx" SG_ 857 LHS_Temp_Disp_Digit3 1;
BA_ "U_U55X_MY2022_Rx" SG_ 857 LHS_Temp_Disp_Digit3 1;
BA_ "U_CD542_MY2021_Rx" SG_ 857 LHS_Temp_Disp_Digit3 1;
BA_ "U_T6_MCA_MY2020_Rx" SG_ 857 LHS_Temp_Disp_Digit3 1;
BA_ "U_CX727_MY2021_Rx" SG_ 857 LHS_Temp_Disp_Digit3 1;
BA_ "U_CD764_MY2022_Rx" SG_ 857 LHS_Temp_Disp_Digit2 1;
BA_ "U_U55X_MY2022_Rx" SG_ 857 LHS_Temp_Disp_Digit2 1;
BA_ "U_CD542_MY2021_Rx" SG_ 857 LHS_Temp_Disp_Digit2 1;
BA_ "U_T6_MCA_MY2020_Rx" SG_ 857 LHS_Temp_Disp_Digit2 1;
BA_ "U_CX727_MY2021_Rx" SG_ 857 LHS_Temp_Disp_Digit2 1;
BA_ "U_CD764_MY2022_Rx" SG_ 857 LHS_Temp_Disp_Digit1 1;
BA_ "U_U55X_MY2022_Rx" SG_ 857 LHS_Temp_Disp_Digit1 1;
BA_ "U_CD542_MY2021_Rx" SG_ 857 LHS_Temp_Disp_Digit1 1;
BA_ "U_T6_MCA_MY2020_Rx" SG_ 857 LHS_Temp_Disp_Digit1 1;
BA_ "U_CX727_MY2021_Rx" SG_ 857 LHS_Temp_Disp_Digit1 1;
BA_ "U_CD764_MY2022_Rx" SG_ 857 Front_Blower_Ind 1;
BA_ "U_U55X_MY2022_Rx" SG_ 857 Front_Blower_Ind 1;
BA_ "U_CD542_MY2021_Rx" SG_ 857 Front_Blower_Ind 1;
BA_ "U_T6_MCA_MY2020_Rx" SG_ 857 Front_Blower_Ind 1;
BA_ "U_CX727_MY2021_Rx" SG_ 857 Front_Blower_Ind 1;
BA_ "GenSigStartValue" SG_ 857 Front_Blower_Ind 15;
BA_ "GenSigStartValueInteger" SG_ 857 Front_Blower_Ind 15;
BA_ "U_CD764_MY2022_Rx" SG_ 857 EATC_LHS_Unit 1;
BA_ "U_U55X_MY2022_Rx" SG_ 857 EATC_LHS_Unit 1;
BA_ "U_CD542_MY2021_Rx" SG_ 857 EATC_LHS_Unit 1;
BA_ "U_T6_MCA_MY2020_Rx" SG_ 857 EATC_LHS_Unit 1;
BA_ "U_CX727_MY2021_Rx" SG_ 857 EATC_LHS_Unit 1;
BA_ "U_CD764_MY2022_Rx" SG_ 856 Frt_Blower_Speed2 1;
BA_ "U_U55X_MY2022_Rx" SG_ 856 Frt_Blower_Speed2 1;
BA_ "U_CD542_MY2021_Rx" SG_ 856 Frt_Blower_Speed2 1;
BA_ "U_T6_MCA_MY2020_Rx" SG_ 856 Frt_Blower_Speed2 1;
BA_ "U_CD764_MY2022_Rx" SG_ 856 Psngr_Set_Temp 1;
BA_ "U_U55X_MY2022_Rx" SG_ 856 Psngr_Set_Temp 1;
BA_ "U_CD542_MY2021_Rx" SG_ 856 Psngr_Set_Temp 1;
BA_ "U_T6_MCA_MY2020_Rx" SG_ 856 Psngr_Set_Temp 1;
BA_ "U_CD764_MY2022_Rx" SG_ 856 SnowPlowOn_B_Rq 1;
BA_ "U_U55X_MY2022_Rx" SG_ 856 SnowPlowOn_B_Rq 1;
BA_ "U_CD542_MY2021_Rx" SG_ 856 SnowPlowOn_B_Rq 1;
BA_ "U_T6_MCA_MY2020_Rx" SG_ 856 SnowPlowOn_B_Rq 1;
BA_ "U_CD764_MY2022_Rx" SG_ 856 Rr_Btn_Status_2nd 1;
BA_ "U_U55X_MY2022_Rx" SG_ 856 Rr_Btn_Status_2nd 1;
BA_ "U_CD542_MY2021_Rx" SG_ 856 Rr_Btn_Status_2nd 1;
BA_ "U_T6_MCA_MY2020_Rx" SG_ 856 Rr_Btn_Status_2nd 1;
BA_ "U_CD764_MY2022_Rx" SG_ 856 Rr_Btn_Status_1st 1;
BA_ "U_U55X_MY2022_Rx" SG_ 856 Rr_Btn_Status_1st 1;
BA_ "U_CD542_MY2021_Rx" SG_ 856 Rr_Btn_Status_1st 1;
BA_ "U_T6_MCA_MY2020_Rx" SG_ 856 Rr_Btn_Status_1st 1;
BA_ "U_CD764_MY2022_Rx" SG_ 856 Frt_Btn_Status_2nd 1;
BA_ "U_U55X_MY2022_Rx" SG_ 856 Frt_Btn_Status_2nd 1;
BA_ "U_CD542_MY2021_Rx" SG_ 856 Frt_Btn_Status_2nd 1;
BA_ "U_T6_MCA_MY2020_Rx" SG_ 856 Frt_Btn_Status_2nd 1;
BA_ "U_P702_MY2021_Rx" SG_ 856 Frt_Btn_Status_2nd 1;
BA_ "U_CX727_MY2021_Rx" SG_ 856 Frt_Btn_Status_2nd 1;
BA_ "U_CD764_MY2022_Rx" SG_ 856 Frt_Btn_Status_1st 1;
BA_ "U_U55X_MY2022_Rx" SG_ 856 Frt_Btn_Status_1st 1;
BA_ "U_CD542_MY2021_Rx" SG_ 856 Frt_Btn_Status_1st 1;
BA_ "U_T6_MCA_MY2020_Rx" SG_ 856 Frt_Btn_Status_1st 1;
BA_ "U_P702_MY2021_Rx" SG_ 856 Frt_Btn_Status_1st 1;
BA_ "U_CX727_MY2021_Rx" SG_ 856 Frt_Btn_Status_1st 1;
BA_ "U_CD764_MY2022_Rx" SG_ 856 Frt_Blower_Speed 1;
BA_ "U_U55X_MY2022_Rx" SG_ 856 Frt_Blower_Speed 1;
BA_ "U_CD542_MY2021_Rx" SG_ 856 Frt_Blower_Speed 1;
BA_ "U_T6_MCA_MY2020_Rx" SG_ 856 Frt_Blower_Speed 1;
BA_ "U_P702_MY2021_Rx" SG_ 856 Frt_Blower_Speed 1;
BA_ "U_CX727_MY2021_Rx" SG_ 856 Frt_Blower_Speed 1;
BA_ "U_CD764_MY2022_Rx" SG_ 856 Drv_Set_Temp 1;
BA_ "U_U55X_MY2022_Rx" SG_ 856 Drv_Set_Temp 1;
BA_ "U_CD542_MY2021_Rx" SG_ 856 Drv_Set_Temp 1;
BA_ "U_T6_MCA_MY2020_Rx" SG_ 856 Drv_Set_Temp 1;
BA_ "U_P702_MY2021_Rx" SG_ 856 Drv_Set_Temp 1;
BA_ "U_CX727_MY2021_Rx" SG_ 856 Drv_Set_Temp 1;
BA_ "U_U55X_MY2022_Tx" SG_ 854 SelDrvMdeSwtch_D_Stat2 1;
BA_ "U_CD542_MY2021_Tx" SG_ 854 SelDrvMdeSwtch_D_Stat2 1;
BA_ "U_T6_MCA_MY2020_Tx" SG_ 854 SelDrvMdeSwtch_D_Stat2 1;
BA_ "U_CX727_MY2021_Tx" SG_ 854 SelDrvMdeSwtch_D_Stat2 1;
BA_ "GenSigSendType" SG_ 854 SelDrvMdeSwtch_D_Stat2 3;
BA_ "U_CD764_MY2022_Tx" SG_ 854 LHS_Auto_Seat_Btn_Stt 1;
BA_ "U_CD542_MY2021_Tx" SG_ 854 LHS_Auto_Seat_Btn_Stt 1;
BA_ "U_U55X_MY2022_Tx" SG_ 854 LHS_Auto_Seat_Btn_Stt 1;
BA_ "U_T6_MCA_MY2020_Tx" SG_ 854 LHS_Auto_Seat_Btn_Stt 1;
BA_ "GenSigSendType" SG_ 854 LHS_Auto_Seat_Btn_Stt 3;
BA_ "GenSigStartValue" SG_ 854 LHS_Auto_Seat_Btn_Stt 2;
BA_ "U_CD764_MY2022_Tx" SG_ 854 RHS_Auto_Seat_Btn_Stt 1;
BA_ "U_CD542_MY2021_Tx" SG_ 854 RHS_Auto_Seat_Btn_Stt 1;
BA_ "U_U55X_MY2022_Tx" SG_ 854 RHS_Auto_Seat_Btn_Stt 1;
BA_ "U_T6_MCA_MY2020_Tx" SG_ 854 RHS_Auto_Seat_Btn_Stt 1;
BA_ "GenSigSendType" SG_ 854 RHS_Auto_Seat_Btn_Stt 3;
BA_ "GenSigStartValue" SG_ 854 RHS_Auto_Seat_Btn_Stt 2;
BA_ "U_CD764_MY2022_Tx" SG_ 854 CC_Fr_Stat_User_Adj 1;
BA_ "U_U55X_MY2022_Tx" SG_ 854 CC_Fr_Stat_User_Adj 1;
BA_ "U_CD542_MY2021_Tx" SG_ 854 CC_Fr_Stat_User_Adj 1;
BA_ "U_T6_MCA_MY2020_Tx" SG_ 854 CC_Fr_Stat_User_Adj 1;
BA_ "U_P702_MY2021_Tx" SG_ 854 CC_Fr_Stat_User_Adj 1;
BA_ "U_CX727_MY2021_Tx" SG_ 854 CC_Fr_Stat_User_Adj 1;
BA_ "GenSigSendType" SG_ 854 CC_Fr_Stat_User_Adj 3;
BA_ "U_CD764_MY2022_Tx" SG_ 854 Front_Blower_Indicate 1;
BA_ "U_U55X_MY2022_Tx" SG_ 854 Front_Blower_Indicate 1;
BA_ "U_CD542_MY2021_Tx" SG_ 854 Front_Blower_Indicate 1;
BA_ "U_T6_MCA_MY2020_Tx" SG_ 854 Front_Blower_Indicate 1;
BA_ "U_P702_MY2021_Tx" SG_ 854 Front_Blower_Indicate 1;
BA_ "U_CX727_MY2021_Tx" SG_ 854 Front_Blower_Indicate 1;
BA_ "GenSigSendType" SG_ 854 Front_Blower_Indicate 3;
BA_ "GenSigStartValue" SG_ 854 Front_Blower_Indicate 15;
BA_ "GenSigStartValueInteger" SG_ 854 Front_Blower_Indicate 15;
BA_ "U_CD764_MY2022_Tx" SG_ 854 CC_Diagnostics_Active 1;
BA_ "U_U55X_MY2022_Tx" SG_ 854 CC_Diagnostics_Active 1;
BA_ "U_CD542_MY2021_Tx" SG_ 854 CC_Diagnostics_Active 1;
BA_ "U_T6_MCA_MY2020_Tx" SG_ 854 CC_Diagnostics_Active 1;
BA_ "U_P702_MY2021_Tx" SG_ 854 CC_Diagnostics_Active 1;
BA_ "U_CX727_MY2021_Tx" SG_ 854 CC_Diagnostics_Active 1;
BA_ "GenSigSendType" SG_ 854 CC_Diagnostics_Active 3;
BA_ "U_CD764_MY2022_Tx" SG_ 854 RHS_Temp_Display_Digit3 1;
BA_ "U_U55X_MY2022_Tx" SG_ 854 RHS_Temp_Display_Digit3 1;
BA_ "U_CD542_MY2021_Tx" SG_ 854 RHS_Temp_Display_Digit3 1;
BA_ "U_T6_MCA_MY2020_Tx" SG_ 854 RHS_Temp_Display_Digit3 1;
BA_ "U_P702_MY2021_Tx" SG_ 854 RHS_Temp_Display_Digit3 1;
BA_ "U_CX727_MY2021_Tx" SG_ 854 RHS_Temp_Display_Digit3 1;
BA_ "GenSigSendType" SG_ 854 RHS_Temp_Display_Digit3 3;
BA_ "U_CD764_MY2022_Tx" SG_ 854 RHS_Temp_Display_Digit2 1;
BA_ "U_U55X_MY2022_Tx" SG_ 854 RHS_Temp_Display_Digit2 1;
BA_ "U_CD542_MY2021_Tx" SG_ 854 RHS_Temp_Display_Digit2 1;
BA_ "U_T6_MCA_MY2020_Tx" SG_ 854 RHS_Temp_Display_Digit2 1;
BA_ "U_P702_MY2021_Tx" SG_ 854 RHS_Temp_Display_Digit2 1;
BA_ "U_CX727_MY2021_Tx" SG_ 854 RHS_Temp_Display_Digit2 1;
BA_ "GenSigSendType" SG_ 854 RHS_Temp_Display_Digit2 3;
BA_ "U_CD764_MY2022_Tx" SG_ 854 RHS_Temp_Display_Digit1 1;
BA_ "U_U55X_MY2022_Tx" SG_ 854 RHS_Temp_Display_Digit1 1;
BA_ "U_CD542_MY2021_Tx" SG_ 854 RHS_Temp_Display_Digit1 1;
BA_ "U_T6_MCA_MY2020_Tx" SG_ 854 RHS_Temp_Display_Digit1 1;
BA_ "U_P702_MY2021_Tx" SG_ 854 RHS_Temp_Display_Digit1 1;
BA_ "U_CX727_MY2021_Tx" SG_ 854 RHS_Temp_Display_Digit1 1;
BA_ "GenSigSendType" SG_ 854 RHS_Temp_Display_Digit1 3;
BA_ "U_CD764_MY2022_Tx" SG_ 854 LHS_Temp_Display_Digit3 1;
BA_ "U_U55X_MY2022_Tx" SG_ 854 LHS_Temp_Display_Digit3 1;
BA_ "U_CD542_MY2021_Tx" SG_ 854 LHS_Temp_Display_Digit3 1;
BA_ "U_T6_MCA_MY2020_Tx" SG_ 854 LHS_Temp_Display_Digit3 1;
BA_ "U_P702_MY2021_Tx" SG_ 854 LHS_Temp_Display_Digit3 1;
BA_ "U_CX727_MY2021_Tx" SG_ 854 LHS_Temp_Display_Digit3 1;
BA_ "GenSigSendType" SG_ 854 LHS_Temp_Display_Digit3 3;
BA_ "U_CD764_MY2022_Tx" SG_ 854 LHS_Temp_Display_Digit2 1;
BA_ "U_U55X_MY2022_Tx" SG_ 854 LHS_Temp_Display_Digit2 1;
BA_ "U_CD542_MY2021_Tx" SG_ 854 LHS_Temp_Display_Digit2 1;
BA_ "U_T6_MCA_MY2020_Tx" SG_ 854 LHS_Temp_Display_Digit2 1;
BA_ "U_P702_MY2021_Tx" SG_ 854 LHS_Temp_Display_Digit2 1;
BA_ "U_CX727_MY2021_Tx" SG_ 854 LHS_Temp_Display_Digit2 1;
BA_ "GenSigSendType" SG_ 854 LHS_Temp_Display_Digit2 3;
BA_ "U_CD764_MY2022_Tx" SG_ 854 LHS_Temp_Display_Digit1 1;
BA_ "U_U55X_MY2022_Tx" SG_ 854 LHS_Temp_Display_Digit1 1;
BA_ "U_CD542_MY2021_Tx" SG_ 854 LHS_Temp_Display_Digit1 1;
BA_ "U_T6_MCA_MY2020_Tx" SG_ 854 LHS_Temp_Display_Digit1 1;
BA_ "U_P702_MY2021_Tx" SG_ 854 LHS_Temp_Display_Digit1 1;
BA_ "U_CX727_MY2021_Tx" SG_ 854 LHS_Temp_Display_Digit1 1;
BA_ "GenSigSendType" SG_ 854 LHS_Temp_Display_Digit1 3;
BA_ "U_CD764_MY2022_Tx" SG_ 854 EATC_RHS_Units 1;
BA_ "U_U55X_MY2022_Tx" SG_ 854 EATC_RHS_Units 1;
BA_ "U_CD542_MY2021_Tx" SG_ 854 EATC_RHS_Units 1;
BA_ "U_T6_MCA_MY2020_Tx" SG_ 854 EATC_RHS_Units 1;
BA_ "U_P702_MY2021_Tx" SG_ 854 EATC_RHS_Units 1;
BA_ "U_CX727_MY2021_Tx" SG_ 854 EATC_RHS_Units 1;
BA_ "GenSigSendType" SG_ 854 EATC_RHS_Units 3;
BA_ "U_CD764_MY2022_Tx" SG_ 854 EATC_LHS_Units 1;
BA_ "U_U55X_MY2022_Tx" SG_ 854 EATC_LHS_Units 1;
BA_ "U_CD542_MY2021_Tx" SG_ 854 EATC_LHS_Units 1;
BA_ "U_T6_MCA_MY2020_Tx" SG_ 854 EATC_LHS_Units 1;
BA_ "U_P702_MY2021_Tx" SG_ 854 EATC_LHS_Units 1;
BA_ "U_CX727_MY2021_Tx" SG_ 854 EATC_LHS_Units 1;
BA_ "GenSigSendType" SG_ 854 EATC_LHS_Units 3;
BA_ "U_CX727_MY2021_Rx" SG_ 534 WhlDirFr_D_Actl 1;
BA_ "U_T6_MCA_MY2020_Rx" SG_ 534 WhlRotatFr_No_Cnt 1;
BA_ "U_CX727_MY2021_Rx" SG_ 534 WhlRotatFr_No_Cnt 1;
BA_ "U_CD764_MY2022_Tx" SG_ 772 SeatScrnDrvOn_B_Rq 1;
BA_ "U_U55X_MY2022_Tx" SG_ 772 SeatScrnDrvOn_B_Rq 1;
BA_ "U_CD542_MY2021_Tx" SG_ 772 SeatScrnDrvOn_B_Rq 1;
BA_ "U_T6_MCA_MY2020_Tx" SG_ 772 SeatScrnDrvOn_B_Rq 1;
BA_ "U_P702_MY2021_Tx" SG_ 772 SeatScrnDrvOn_B_Rq 1;
BA_ "U_CX727_MY2021_Tx" SG_ 772 SeatScrnDrvOn_B_Rq 1;
BA_ "GenSigSendType" SG_ 772 SeatScrnDrvOn_B_Rq 3;
BA_ "WakeupSignal" SG_ 772 SeatScrnDrvOn_B_Rq 1;
BA_ "U_CD764_MY2022_Tx" SG_ 772 SeatPos_D_Stat 1;
BA_ "U_U55X_MY2022_Tx" SG_ 772 SeatPos_D_Stat 1;
BA_ "U_T6_MCA_MY2020_Tx" SG_ 772 SeatPos_D_Stat 1;
BA_ "U_U55X_MY2022_Rx" SG_ 772 SeatPos_D_Stat 1;
BA_ "GenSigSendType" SG_ 772 SeatPos_D_Stat 3;
BA_ "U_CD764_MY2022_Tx" SG_ 772 MemDrvDeny_B_Stat 1;
BA_ "U_U55X_MY2022_Tx" SG_ 772 MemDrvDeny_B_Stat 1;
BA_ "U_CD542_MY2021_Tx" SG_ 772 MemDrvDeny_B_Stat 1;
BA_ "U_T6_MCA_MY2020_Tx" SG_ 772 MemDrvDeny_B_Stat 1;
BA_ "U_P702_MY2021_Tx" SG_ 772 MemDrvDeny_B_Stat 1;
BA_ "U_CX727_MY2021_Tx" SG_ 772 MemDrvDeny_B_Stat 1;
BA_ "GenSigSendType" SG_ 772 MemDrvDeny_B_Stat 3;
BA_ "U_CD764_MY2022_Tx" SG_ 772 Memory_Feedback_Rqst 1;
BA_ "U_U55X_MY2022_Tx" SG_ 772 Memory_Feedback_Rqst 1;
BA_ "U_CD542_MY2021_Tx" SG_ 772 Memory_Feedback_Rqst 1;
BA_ "U_T6_MCA_MY2020_Tx" SG_ 772 Memory_Feedback_Rqst 1;
BA_ "U_P702_MY2021_Tx" SG_ 772 Memory_Feedback_Rqst 1;
BA_ "U_CX727_MY2021_Tx" SG_ 772 Memory_Feedback_Rqst 1;
BA_ "GenSigSendType" SG_ 772 Memory_Feedback_Rqst 3;
BA_ "WakeupSignal" SG_ 772 Memory_Feedback_Rqst 1;
BA_ "U_CD764_MY2022_Tx" SG_ 772 Easy_Entry_Rqst 1;
BA_ "U_U55X_MY2022_Tx" SG_ 772 Easy_Entry_Rqst 1;
BA_ "U_CD542_MY2021_Tx" SG_ 772 Easy_Entry_Rqst 1;
BA_ "U_T6_MCA_MY2020_Tx" SG_ 772 Easy_Entry_Rqst 1;
BA_ "U_P702_MY2021_Tx" SG_ 772 Easy_Entry_Rqst 1;
BA_ "U_CX727_MY2021_Tx" SG_ 772 Easy_Entry_Rqst 1;
BA_ "U_CD764_MY2022_Rx" SG_ 772 Easy_Entry_Rqst 1;
BA_ "U_U55X_MY2022_Rx" SG_ 772 Easy_Entry_Rqst 1;
BA_ "U_P702_MY2021_Rx" SG_ 772 Easy_Entry_Rqst 1;
BA_ "GenSigSendType" SG_ 772 Easy_Entry_Rqst 3;
BA_ "WakeupSignal" SG_ 772 Easy_Entry_Rqst 1;
BA_ "U_CD764_MY2022_Tx" SG_ 772 Memory_Cmd 1;
BA_ "U_U55X_MY2022_Tx" SG_ 772 Memory_Cmd 1;
BA_ "U_CD542_MY2021_Tx" SG_ 772 Memory_Cmd 1;
BA_ "U_T6_MCA_MY2020_Tx" SG_ 772 Memory_Cmd 1;
BA_ "U_P702_MY2021_Tx" SG_ 772 Memory_Cmd 1;
BA_ "U_CX727_MY2021_Tx" SG_ 772 Memory_Cmd 1;
BA_ "U_CD542_MY2021_Rx" SG_ 772 Memory_Cmd 1;
BA_ "U_CX727_MY2021_Rx" SG_ 772 Memory_Cmd 1;
BA_ "U_T6_MCA_MY2020_Rx" SG_ 772 Memory_Cmd 1;
BA_ "U_CD764_MY2022_Rx" SG_ 772 Memory_Cmd 1;
BA_ "U_U55X_MY2022_Rx" SG_ 772 Memory_Cmd 1;
BA_ "U_P702_MY2021_Rx" SG_ 772 Memory_Cmd 1;
BA_ "GenSigSendType" SG_ 772 Memory_Cmd 3;
BA_ "WakeupSignal" SG_ 772 Memory_Cmd 1;
BA_ "U_CD764_MY2022_Tx" SG_ 772 Cancel_Auto_Movement 1;
BA_ "U_U55X_MY2022_Tx" SG_ 772 Cancel_Auto_Movement 1;
BA_ "U_CD542_MY2021_Tx" SG_ 772 Cancel_Auto_Movement 1;
BA_ "U_T6_MCA_MY2020_Tx" SG_ 772 Cancel_Auto_Movement 1;
BA_ "U_P702_MY2021_Tx" SG_ 772 Cancel_Auto_Movement 1;
BA_ "U_CX727_MY2021_Tx" SG_ 772 Cancel_Auto_Movement 1;
BA_ "U_CD542_MY2021_Rx" SG_ 772 Cancel_Auto_Movement 1;
BA_ "U_T6_MCA_MY2020_Rx" SG_ 772 Cancel_Auto_Movement 1;
BA_ "U_CX727_MY2021_Rx" SG_ 772 Cancel_Auto_Movement 1;
BA_ "U_CD764_MY2022_Rx" SG_ 772 Cancel_Auto_Movement 1;
BA_ "U_U55X_MY2022_Rx" SG_ 772 Cancel_Auto_Movement 1;
BA_ "U_P702_MY2021_Rx" SG_ 772 Cancel_Auto_Movement 1;
BA_ "GenSigSendType" SG_ 772 Cancel_Auto_Movement 3;
BA_ "WakeupSignal" SG_ 772 Cancel_Auto_Movement 1;
BA_ "U_U55X_MY2022_Rx" SG_ 1070 StopStrtStdby_D_Indic_UB 1;
BA_ "U_T6_MCA_MY2020_Rx" SG_ 1070 StopStrtStdby_D_Indic_UB 1;
BA_ "U_CD764_MY2022_Rx" SG_ 1070 StopStrtStdby_D_Indic_UB 1;
BA_ "U_CX727_MY2021_Rx" SG_ 1070 StopStrtStdby_D_Indic_UB 1;
BA_ "U_CD764_MY2022_Rx" SG_ 1070 PassRstrnInd_Req_UB 1;
BA_ "U_U55X_MY2022_Rx" SG_ 1070 PassRstrnInd_Req_UB 1;
BA_ "U_CD542_MY2021_Rx" SG_ 1070 PassRstrnInd_Req_UB 1;
BA_ "U_T6_MCA_MY2020_Rx" SG_ 1070 PassRstrnInd_Req_UB 1;
BA_ "U_CX727_MY2021_Rx" SG_ 1070 HiElPwInhbt_B_Stat_UB 1;
BA_ "U_CD764_MY2022_Rx" SG_ 1070 HiElPwInhbt_B_Stat_UB 1;
BA_ "U_U55X_MY2022_Rx" SG_ 1070 HiElPwInhbt_B_Stat_UB 1;
BA_ "U_CD542_MY2021_Rx" SG_ 1070 HiElPwInhbt_B_Stat_UB 1;
BA_ "U_T6_MCA_MY2020_Rx" SG_ 1070 HiElPwInhbt_B_Stat_UB 1;
BA_ "U_P702_MY2021_Rx" SG_ 1070 HiElPwInhbt_B_Stat_UB 1;
BA_ "U_CX727_MY2021_Rx" SG_ 1070 HiElPwInhbt_B_Stat 1;
BA_ "U_CD764_MY2022_Rx" SG_ 1070 HiElPwInhbt_B_Stat 1;
BA_ "U_U55X_MY2022_Rx" SG_ 1070 HiElPwInhbt_B_Stat 1;
BA_ "U_CD542_MY2021_Rx" SG_ 1070 HiElPwInhbt_B_Stat 1;
BA_ "U_T6_MCA_MY2020_Rx" SG_ 1070 HiElPwInhbt_B_Stat 1;
BA_ "U_P702_MY2021_Rx" SG_ 1070 HiElPwInhbt_B_Stat 1;
BA_ "GenSigSendType" SG_ 1070 HiElPwInhbt_B_Stat 3;
BA_ "ContentDependant" SG_ 1070 HiElPwInhbt_B_Stat 1;
BA_ "U_U55X_MY2022_Rx" SG_ 1070 StopStrtStdby_D_Indic 1;
BA_ "U_T6_MCA_MY2020_Rx" SG_ 1070 StopStrtStdby_D_Indic 1;
BA_ "U_CD764_MY2022_Rx" SG_ 1070 StopStrtStdby_D_Indic 1;
BA_ "U_CX727_MY2021_Rx" SG_ 1070 StopStrtStdby_D_Indic 1;
BA_ "GenSigSendType" SG_ 1070 StopStrtStdby_D_Indic 3;
BA_ "U_CD764_MY2022_Rx" SG_ 1070 CoolantFanStepAct_UB 1;
BA_ "U_U55X_MY2022_Rx" SG_ 1070 CoolantFanStepAct_UB 1;
BA_ "U_CD542_MY2021_Rx" SG_ 1070 CoolantFanStepAct_UB 1;
BA_ "U_T6_MCA_MY2020_Rx" SG_ 1070 CoolantFanStepAct_UB 1;
BA_ "U_P702_MY2021_Rx" SG_ 1070 CoolantFanStepAct_UB 1;
BA_ "U_CX727_MY2021_Rx" SG_ 1070 CoolantFanStepAct_UB 1;
BA_ "U_CD764_MY2022_Rx" SG_ 1070 CoolantFanStepAct 1;
BA_ "U_U55X_MY2022_Rx" SG_ 1070 CoolantFanStepAct 1;
BA_ "U_CD542_MY2021_Rx" SG_ 1070 CoolantFanStepAct 1;
BA_ "U_T6_MCA_MY2020_Rx" SG_ 1070 CoolantFanStepAct 1;
BA_ "U_P702_MY2021_Rx" SG_ 1070 CoolantFanStepAct 1;
BA_ "U_CX727_MY2021_Rx" SG_ 1070 CoolantFanStepAct 1;
BA_ "GenSigSendType" SG_ 1070 CoolantFanStepAct 3;
BA_ "U_CD764_MY2022_Rx" SG_ 1070 RstrnImpactEvntStatus_UB 1;
BA_ "U_U55X_MY2022_Rx" SG_ 1070 RstrnImpactEvntStatus_UB 1;
BA_ "U_CD542_MY2021_Rx" SG_ 1070 RstrnImpactEvntStatus_UB 1;
BA_ "U_T6_MCA_MY2020_Rx" SG_ 1070 RstrnImpactEvntStatus_UB 1;
BA_ "U_P702_MY2021_Rx" SG_ 1070 RstrnImpactEvntStatus_UB 1;
BA_ "U_CX727_MY2021_Rx" SG_ 1070 RstrnImpactEvntStatus_UB 1;
BA_ "U_CD764_MY2022_Rx" SG_ 1070 EngAirIn_Te_Actl_UB 1;
BA_ "U_U55X_MY2022_Rx" SG_ 1070 EngAirIn_Te_Actl_UB 1;
BA_ "U_CD542_MY2021_Rx" SG_ 1070 EngAirIn_Te_Actl_UB 1;
BA_ "U_T6_MCA_MY2020_Rx" SG_ 1070 EngAirIn_Te_Actl_UB 1;
BA_ "U_P702_MY2021_Rx" SG_ 1070 EngAirIn_Te_Actl_UB 1;
BA_ "U_CX727_MY2021_Rx" SG_ 1070 EngAirIn_Te_Actl_UB 1;
BA_ "U_CD764_MY2022_Rx" SG_ 1070 RstrnImpactEvntStatus 1;
BA_ "U_U55X_MY2022_Rx" SG_ 1070 RstrnImpactEvntStatus 1;
BA_ "U_CD542_MY2021_Rx" SG_ 1070 RstrnImpactEvntStatus 1;
BA_ "U_T6_MCA_MY2020_Rx" SG_ 1070 RstrnImpactEvntStatus 1;
BA_ "U_P702_MY2021_Rx" SG_ 1070 RstrnImpactEvntStatus 1;
BA_ "U_CX727_MY2021_Rx" SG_ 1070 RstrnImpactEvntStatus 1;
BA_ "GenSigSendType" SG_ 1070 RstrnImpactEvntStatus 3;
BA_ "WakeupSignal" SG_ 1070 RstrnImpactEvntStatus 1;
BA_ "U_CD764_MY2022_Rx" SG_ 1070 EngAirIn_Te_Actl 1;
BA_ "U_U55X_MY2022_Rx" SG_ 1070 EngAirIn_Te_Actl 1;
BA_ "U_CD542_MY2021_Rx" SG_ 1070 EngAirIn_Te_Actl 1;
BA_ "U_T6_MCA_MY2020_Rx" SG_ 1070 EngAirIn_Te_Actl 1;
BA_ "U_P702_MY2021_Rx" SG_ 1070 EngAirIn_Te_Actl 1;
BA_ "U_CX727_MY2021_Rx" SG_ 1070 EngAirIn_Te_Actl 1;
BA_ "U_CD764_MY2022_Rx" SG_ 1070 EngAout_N_Actl_UB 1;
BA_ "U_U55X_MY2022_Rx" SG_ 1070 EngAout_N_Actl_UB 1;
BA_ "U_CD542_MY2021_Rx" SG_ 1070 EngAout_N_Actl_UB 1;
BA_ "U_T6_MCA_MY2020_Rx" SG_ 1070 EngAout_N_Actl_UB 1;
BA_ "U_P702_MY2021_Rx" SG_ 1070 EngAout_N_Actl_UB 1;
BA_ "U_CX727_MY2021_Rx" SG_ 1070 EngAout_N_Actl_UB 1;
BA_ "U_CD764_MY2022_Rx" SG_ 1070 EngAout_N_Actl 1;
BA_ "U_U55X_MY2022_Rx" SG_ 1070 EngAout_N_Actl 1;
BA_ "U_CD542_MY2021_Rx" SG_ 1070 EngAout_N_Actl 1;
BA_ "U_T6_MCA_MY2020_Rx" SG_ 1070 EngAout_N_Actl 1;
BA_ "U_P702_MY2021_Rx" SG_ 1070 EngAout_N_Actl 1;
BA_ "U_CX727_MY2021_Rx" SG_ 1070 EngAout_N_Actl 1;
BA_ "U_CX727_MY2021_Rx" SG_ 1070 VehVActlEng_D_Qf 1;
BA_ "U_CD764_MY2022_Rx" SG_ 1070 VehVActlEng_D_Qf 1;
BA_ "U_U55X_MY2022_Rx" SG_ 1070 VehVActlEng_D_Qf 1;
BA_ "U_CD542_MY2021_Rx" SG_ 1070 VehVActlEng_D_Qf 1;
BA_ "U_T6_MCA_MY2020_Rx" SG_ 1070 VehVActlEng_D_Qf 1;
BA_ "U_P702_MY2021_Rx" SG_ 1070 VehVActlEng_D_Qf 1;
BA_ "MetaData" SG_ 1070 VehVActlEng_D_Qf 1;
BA_ "U_CD764_MY2022_Rx" SG_ 1070 Veh_V_ActlEng_UB 1;
BA_ "U_U55X_MY2022_Rx" SG_ 1070 Veh_V_ActlEng_UB 1;
BA_ "U_CD542_MY2021_Rx" SG_ 1070 Veh_V_ActlEng_UB 1;
BA_ "U_T6_MCA_MY2020_Rx" SG_ 1070 Veh_V_ActlEng_UB 1;
BA_ "U_P702_MY2021_Rx" SG_ 1070 Veh_V_ActlEng_UB 1;
BA_ "U_CX727_MY2021_Rx" SG_ 1070 Veh_V_ActlEng_UB 1;
BA_ "U_CD764_MY2022_Rx" SG_ 1070 Veh_V_ActlEng 1;
BA_ "U_U55X_MY2022_Rx" SG_ 1070 Veh_V_ActlEng 1;
BA_ "U_CD542_MY2021_Rx" SG_ 1070 Veh_V_ActlEng 1;
BA_ "U_T6_MCA_MY2020_Rx" SG_ 1070 Veh_V_ActlEng 1;
BA_ "U_P702_MY2021_Rx" SG_ 1070 Veh_V_ActlEng 1;
BA_ "U_CX727_MY2021_Rx" SG_ 1070 Veh_V_ActlEng 1;
BA_ "U_U55X_MY2022_Rx" SG_ 1070 PassRstrnInd_Req 1;
BA_ "U_CD542_MY2021_Rx" SG_ 1070 PassRstrnInd_Req 1;
BA_ "U_T6_MCA_MY2020_Rx" SG_ 1070 PassRstrnInd_Req 1;
BA_ "GenSigSendType" SG_ 1070 PassRstrnInd_Req 3;
BA_ "GenSigStartValue" SG_ 1070 PassRstrnInd_Req 3;
BA_ "GenSigStartValueInteger" SG_ 1070 PassRstrnInd_Req 3;
BA_ "U_CD764_MY2022_Tx" SG_ 1050 MirrorHeatOn_B_Rq 1;
BA_ "U_U55X_MY2022_Tx" SG_ 1050 MirrorHeatOn_B_Rq 1;
BA_ "U_CD542_MY2021_Tx" SG_ 1050 MirrorHeatOn_B_Rq 1;
BA_ "U_T6_MCA_MY2020_Tx" SG_ 1050 MirrorHeatOn_B_Rq 1;
BA_ "U_P702_MY2021_Tx" SG_ 1050 MirrorHeatOn_B_Rq 1;
BA_ "U_CX727_MY2021_Tx" SG_ 1050 MirrorHeatOn_B_Rq 1;
BA_ "U_CX727_MY2021_Rx" SG_ 1050 MirrorHeatOn_B_Rq 1;
BA_ "U_CD764_MY2022_Rx" SG_ 1050 MirrorHeatOn_B_Rq 1;
BA_ "U_U55X_MY2022_Rx" SG_ 1050 MirrorHeatOn_B_Rq 1;
BA_ "U_CD542_MY2021_Rx" SG_ 1050 MirrorHeatOn_B_Rq 1;
BA_ "U_T6_MCA_MY2020_Rx" SG_ 1050 MirrorHeatOn_B_Rq 1;
BA_ "U_P702_MY2021_Rx" SG_ 1050 MirrorHeatOn_B_Rq 1;
BA_ "GenSigSendType" SG_ 1050 MirrorHeatOn_B_Rq 3;
BA_ "U_CD542_MY2021_Tx" SG_ 1050 CamraRearBttn_D_Stat 1;
BA_ "U_T6_MCA_MY2020_Tx" SG_ 1050 CamraRearBttn_D_Stat 1;
BA_ "GenSigSendType" SG_ 1050 CamraRearBttn_D_Stat 3;
BA_ "U_U55X_MY2022_Tx" SG_ 1050 AutoHoldSwtch_D_Stat 1;
BA_ "U_CD542_MY2021_Tx" SG_ 1050 AutoHoldSwtch_D_Stat 1;
BA_ "U_T6_MCA_MY2020_Tx" SG_ 1050 AutoHoldSwtch_D_Stat 1;
BA_ "U_CX727_MY2021_Tx" SG_ 1050 AutoHoldSwtch_D_Stat 1;
BA_ "GenSigSendType" SG_ 1050 AutoHoldSwtch_D_Stat 3;
BA_ "U_CD764_MY2022_Tx" SG_ 1050 EcoInhbt_B_RqHvac 1;
BA_ "U_U55X_MY2022_Tx" SG_ 1050 EcoInhbt_B_RqHvac 1;
BA_ "U_CD542_MY2021_Tx" SG_ 1050 EcoInhbt_B_RqHvac 1;
BA_ "U_T6_MCA_MY2020_Tx" SG_ 1050 EcoInhbt_B_RqHvac 1;
BA_ "U_CX727_MY2021_Tx" SG_ 1050 EcoInhbt_B_RqHvac 1;
BA_ "GenSigSendType" SG_ 1050 EcoInhbt_B_RqHvac 3;
BA_ "U_CD764_MY2022_Tx" SG_ 1050 LpdbPtc3_B_Rq 1;
BA_ "U_U55X_MY2022_Tx" SG_ 1050 LpdbPtc3_B_Rq 1;
BA_ "U_CD542_MY2021_Tx" SG_ 1050 LpdbPtc3_B_Rq 1;
BA_ "U_T6_MCA_MY2020_Tx" SG_ 1050 LpdbPtc3_B_Rq 1;
BA_ "U_CX727_MY2021_Tx" SG_ 1050 LpdbPtc3_B_Rq 1;
BA_ "GenSigSendType" SG_ 1050 LpdbPtc3_B_Rq 3;
BA_ "U_CD764_MY2022_Tx" SG_ 1050 LpdbPtc2_B_Rq 1;
BA_ "U_U55X_MY2022_Tx" SG_ 1050 LpdbPtc2_B_Rq 1;
BA_ "U_CD542_MY2021_Tx" SG_ 1050 LpdbPtc2_B_Rq 1;
BA_ "U_T6_MCA_MY2020_Tx" SG_ 1050 LpdbPtc2_B_Rq 1;
BA_ "U_CX727_MY2021_Tx" SG_ 1050 LpdbPtc2_B_Rq 1;
BA_ "GenSigSendType" SG_ 1050 LpdbPtc2_B_Rq 3;
BA_ "U_CD764_MY2022_Tx" SG_ 1050 LpdbPtc1_B_Rq 1;
BA_ "U_U55X_MY2022_Tx" SG_ 1050 LpdbPtc1_B_Rq 1;
BA_ "U_CD542_MY2021_Tx" SG_ 1050 LpdbPtc1_B_Rq 1;
BA_ "U_T6_MCA_MY2020_Tx" SG_ 1050 LpdbPtc1_B_Rq 1;
BA_ "U_CX727_MY2021_Tx" SG_ 1050 LpdbPtc1_B_Rq 1;
BA_ "GenSigSendType" SG_ 1050 LpdbPtc1_B_Rq 3;
BA_ "U_CD764_MY2022_Tx" SG_ 1050 LpdbHeatWiprPrk_B_Rq 1;
BA_ "U_U55X_MY2022_Tx" SG_ 1050 LpdbHeatWiprPrk_B_Rq 1;
BA_ "U_CD542_MY2021_Tx" SG_ 1050 LpdbHeatWiprPrk_B_Rq 1;
BA_ "U_T6_MCA_MY2020_Tx" SG_ 1050 LpdbHeatWiprPrk_B_Rq 1;
BA_ "U_CX727_MY2021_Tx" SG_ 1050 LpdbHeatWiprPrk_B_Rq 1;
BA_ "GenSigSendType" SG_ 1050 LpdbHeatWiprPrk_B_Rq 3;
BA_ "U_CD764_MY2022_Tx" SG_ 1050 LpdbDfrstRearOn_B_Rq 1;
BA_ "U_U55X_MY2022_Tx" SG_ 1050 LpdbDfrstRearOn_B_Rq 1;
BA_ "U_CD542_MY2021_Tx" SG_ 1050 LpdbDfrstRearOn_B_Rq 1;
BA_ "U_T6_MCA_MY2020_Tx" SG_ 1050 LpdbDfrstRearOn_B_Rq 1;
BA_ "U_CX727_MY2021_Tx" SG_ 1050 LpdbDfrstRearOn_B_Rq 1;
BA_ "GenSigSendType" SG_ 1050 LpdbDfrstRearOn_B_Rq 3;
BA_ "U_CD764_MY2022_Tx" SG_ 1050 LpdbDfrstFrOn_B_Rq 1;
BA_ "U_U55X_MY2022_Tx" SG_ 1050 LpdbDfrstFrOn_B_Rq 1;
BA_ "U_CD542_MY2021_Tx" SG_ 1050 LpdbDfrstFrOn_B_Rq 1;
BA_ "U_T6_MCA_MY2020_Tx" SG_ 1050 LpdbDfrstFrOn_B_Rq 1;
BA_ "U_CX727_MY2021_Tx" SG_ 1050 LpdbDfrstFrOn_B_Rq 1;
BA_ "GenSigSendType" SG_ 1050 LpdbDfrstFrOn_B_Rq 3;
BA_ "U_CD764_MY2022_Tx" SG_ 1050 LpdbDfrstFlOn_B_Rq 1;
BA_ "U_U55X_MY2022_Tx" SG_ 1050 LpdbDfrstFlOn_B_Rq 1;
BA_ "U_CD542_MY2021_Tx" SG_ 1050 LpdbDfrstFlOn_B_Rq 1;
BA_ "U_T6_MCA_MY2020_Tx" SG_ 1050 LpdbDfrstFlOn_B_Rq 1;
BA_ "U_CX727_MY2021_Tx" SG_ 1050 LpdbDfrstFlOn_B_Rq 1;
BA_ "GenSigSendType" SG_ 1050 LpdbDfrstFlOn_B_Rq 3;
BA_ "U_CD764_MY2022_Tx" SG_ 1050 LpdbAuxBlwr_B_Rq 1;
BA_ "U_U55X_MY2022_Tx" SG_ 1050 LpdbAuxBlwr_B_Rq 1;
BA_ "U_CD542_MY2021_Tx" SG_ 1050 LpdbAuxBlwr_B_Rq 1;
BA_ "U_T6_MCA_MY2020_Tx" SG_ 1050 LpdbAuxBlwr_B_Rq 1;
BA_ "U_CX727_MY2021_Tx" SG_ 1050 LpdbAuxBlwr_B_Rq 1;
BA_ "GenSigSendType" SG_ 1050 LpdbAuxBlwr_B_Rq 3;
BA_ "U_CD764_MY2022_Tx" SG_ 1050 SteWhlHeat_D_Rq 1;
BA_ "U_U55X_MY2022_Tx" SG_ 1050 SteWhlHeat_D_Rq 1;
BA_ "U_CD542_MY2021_Tx" SG_ 1050 SteWhlHeat_D_Rq 1;
BA_ "U_T6_MCA_MY2020_Tx" SG_ 1050 SteWhlHeat_D_Rq 1;
BA_ "U_P702_MY2021_Tx" SG_ 1050 SteWhlHeat_D_Rq 1;
BA_ "U_CX727_MY2021_Tx" SG_ 1050 SteWhlHeat_D_Rq 1;
BA_ "GenSigSendType" SG_ 1050 SteWhlHeat_D_Rq 3;
BA_ "U_CD764_MY2022_Tx" SG_ 1050 Remote_Start_QuietMode 1;
BA_ "U_U55X_MY2022_Tx" SG_ 1050 Remote_Start_QuietMode 1;
BA_ "U_CD542_MY2021_Tx" SG_ 1050 Remote_Start_QuietMode 1;
BA_ "U_T6_MCA_MY2020_Tx" SG_ 1050 Remote_Start_QuietMode 1;
BA_ "U_P702_MY2021_Tx" SG_ 1050 Remote_Start_QuietMode 1;
BA_ "U_CX727_MY2021_Tx" SG_ 1050 Remote_Start_QuietMode 1;
BA_ "GenSigSendType" SG_ 1050 Remote_Start_QuietMode 3;
BA_ "U_CD764_MY2022_Tx" SG_ 1050 Outside_Air_Temp_Stat 1;
BA_ "U_U55X_MY2022_Tx" SG_ 1050 Outside_Air_Temp_Stat 1;
BA_ "U_CD542_MY2021_Tx" SG_ 1050 Outside_Air_Temp_Stat 1;
BA_ "U_T6_MCA_MY2020_Tx" SG_ 1050 Outside_Air_Temp_Stat 1;
BA_ "U_P702_MY2021_Tx" SG_ 1050 Outside_Air_Temp_Stat 1;
BA_ "U_CX727_MY2021_Tx" SG_ 1050 Outside_Air_Temp_Stat 1;
BA_ "U_CX727_MY2021_Rx" SG_ 1050 Outside_Air_Temp_Stat 1;
BA_ "U_CD764_MY2022_Rx" SG_ 1050 Outside_Air_Temp_Stat 1;
BA_ "U_U55X_MY2022_Rx" SG_ 1050 Outside_Air_Temp_Stat 1;
BA_ "U_CD542_MY2021_Rx" SG_ 1050 Outside_Air_Temp_Stat 1;
BA_ "U_T6_MCA_MY2020_Rx" SG_ 1050 Outside_Air_Temp_Stat 1;
BA_ "U_P702_MY2021_Rx" SG_ 1050 Outside_Air_Temp_Stat 1;
BA_ "GenSigSendType" SG_ 1050 Outside_Air_Temp_Stat 3;
BA_ "GenSigStartValue" SG_ 1050 Outside_Air_Temp_Stat 254;
BA_ "GenSigStartValueInteger" SG_ 1050 Outside_Air_Temp_Stat 254;
BA_ "U_CD764_MY2022_Rx" SG_ 1856 TesterPhysicalReqDDM 1;
BA_ "U_U55X_MY2022_Rx" SG_ 1856 TesterPhysicalReqDDM 1;
BA_ "U_CD542_MY2021_Rx" SG_ 1856 TesterPhysicalReqDDM 1;
BA_ "U_T6_MCA_MY2020_Rx" SG_ 1856 TesterPhysicalReqDDM 1;
BA_ "U_P702_MY2021_Rx" SG_ 1856 TesterPhysicalReqDDM 1;
BA_ "U_CX727_MY2021_Rx" SG_ 1856 TesterPhysicalReqDDM 1;
BA_ "GenSigSendType" SG_ 1856 TesterPhysicalReqDDM 3;
BA_ "U_CD764_MY2022_Tx" SG_ 1864 TesterPhysicalResDDM 1;
BA_ "U_U55X_MY2022_Tx" SG_ 1864 TesterPhysicalResDDM 1;
BA_ "U_CD542_MY2021_Tx" SG_ 1864 TesterPhysicalResDDM 1;
BA_ "U_T6_MCA_MY2020_Tx" SG_ 1864 TesterPhysicalResDDM 1;
BA_ "U_P702_MY2021_Tx" SG_ 1864 TesterPhysicalResDDM 1;
BA_ "U_CX727_MY2021_Tx" SG_ 1864 TesterPhysicalResDDM 1;
BA_ "GenSigSendType" SG_ 1864 TesterPhysicalResDDM 3;
BA_ "U_CD542_MY2021_Rx" SG_ 1937 TesterPhysicalReqTRM 1;
BA_ "U_T6_MCA_MY2020_Rx" SG_ 1937 TesterPhysicalReqTRM 1;
BA_ "U_P702_MY2021_Rx" SG_ 1937 TesterPhysicalReqTRM 1;
BA_ "GenSigSendType" SG_ 1937 TesterPhysicalReqTRM 3;
BA_ "WakeupSignal" SG_ 947 DimmingLvlEvnt_No_Actl 1;
BA_ "U_CX727_MY2021_Rx" SG_ 947 Backlit_LED_Status 1;
BA_ "U_CD764_MY2022_Rx" SG_ 947 Backlit_LED_Status 1;
BA_ "U_U55X_MY2022_Rx" SG_ 947 Backlit_LED_Status 1;
BA_ "U_CD542_MY2021_Rx" SG_ 947 Backlit_LED_Status 1;
BA_ "U_T6_MCA_MY2020_Rx" SG_ 947 Backlit_LED_Status 1;
BA_ "U_P702_MY2021_Rx" SG_ 947 Backlit_LED_Status 1;
BA_ "WakeupSignal" SG_ 947 Backlit_LED_Status 1;
BA_ "U_CD542_MY2021_Rx" SG_ 947 FogLghtRearOn_B_Stat 1;
BA_ "U_T6_MCA_MY2020_Rx" SG_ 947 FogLghtRearOn_B_Stat 1;
BA_ "U_P702_MY2021_Rx" SG_ 947 FogLghtRearOn_B_Stat 1;
BA_ "U_CD542_MY2021_Rx" SG_ 947 ValetMode_D_Mem 1;
BA_ "U_T6_MCA_MY2020_Rx" SG_ 947 ValetMode_D_Mem 1;
BA_ "U_CX727_MY2021_Rx" SG_ 947 ValetMode_D_Mem 1;
BA_ "U_U55X_MY2022_Rx" SG_ 947 IgnKeyType_D_Actl 1;
BA_ "U_T6_MCA_MY2020_Rx" SG_ 947 IgnKeyType_D_Actl 1;
BA_ "U_P702_MY2021_Rx" SG_ 947 IgnKeyType_D_Actl 1;
BA_ "U_CX727_MY2021_Rx" SG_ 947 IgnKeyType_D_Actl 1;
BA_ "GenSigStartValue" SG_ 947 IgnKeyType_D_Actl 14;
BA_ "GenSigStartValueInteger" SG_ 947 IgnKeyType_D_Actl 14;
BA_ "U_CX727_MY2021_Rx" SG_ 947 TurnLghtRight_D_Rq 1;
BA_ "U_CD764_MY2022_Rx" SG_ 947 TurnLghtRight_D_Rq 1;
BA_ "U_U55X_MY2022_Rx" SG_ 947 TurnLghtRight_D_Rq 1;
BA_ "U_CD542_MY2021_Rx" SG_ 947 TurnLghtRight_D_Rq 1;
BA_ "U_T6_MCA_MY2020_Rx" SG_ 947 TurnLghtRight_D_Rq 1;
BA_ "U_P702_MY2021_Rx" SG_ 947 TurnLghtRight_D_Rq 1;
BA_ "WakeupSignal" SG_ 947 TurnLghtRight_D_Rq 1;
BA_ "U_CD764_MY2022_Rx" SG_ 947 Parklamp_Status 1;
BA_ "U_U55X_MY2022_Rx" SG_ 947 Parklamp_Status 1;
BA_ "U_CD542_MY2021_Rx" SG_ 947 Parklamp_Status 1;
BA_ "U_T6_MCA_MY2020_Rx" SG_ 947 Parklamp_Status 1;
BA_ "U_P702_MY2021_Rx" SG_ 947 Parklamp_Status 1;
BA_ "U_CX727_MY2021_Rx" SG_ 947 Parklamp_Status 1;
BA_ "GenSigStartValue" SG_ 947 Parklamp_Status 1;
BA_ "GenSigStartValueInteger" SG_ 947 Parklamp_Status 1;
BA_ "WakeupSignal" SG_ 947 Parklamp_Status 1;
BA_ "U_CX727_MY2021_Rx" SG_ 947 Litval 1;
BA_ "U_CD764_MY2022_Rx" SG_ 947 Litval 1;
BA_ "U_U55X_MY2022_Rx" SG_ 947 Litval 1;
BA_ "U_CD542_MY2021_Rx" SG_ 947 Litval 1;
BA_ "U_T6_MCA_MY2020_Rx" SG_ 947 Litval 1;
BA_ "U_P702_MY2021_Rx" SG_ 947 Litval 1;
BA_ "WakeupSignal" SG_ 947 Litval 1;
BA_ "U_CD764_MY2022_Rx" SG_ 947 Key_In_Ignition_Stat 1;
BA_ "U_CD542_MY2021_Rx" SG_ 947 Key_In_Ignition_Stat 1;
BA_ "U_U55X_MY2022_Rx" SG_ 947 Key_In_Ignition_Stat 1;
BA_ "U_T6_MCA_MY2020_Rx" SG_ 947 Key_In_Ignition_Stat 1;
BA_ "U_P702_MY2021_Rx" SG_ 947 Key_In_Ignition_Stat 1;
BA_ "U_CX727_MY2021_Rx" SG_ 947 Key_In_Ignition_Stat 1;
BA_ "WakeupSignal" SG_ 947 Key_In_Ignition_Stat 1;
BA_ "U_CX727_MY2021_Rx" SG_ 947 Ignition_Status 1;
BA_ "U_CD764_MY2022_Rx" SG_ 947 Ignition_Status 1;
BA_ "U_U55X_MY2022_Rx" SG_ 947 Ignition_Status 1;
BA_ "U_CD542_MY2021_Rx" SG_ 947 Ignition_Status 1;
BA_ "U_T6_MCA_MY2020_Rx" SG_ 947 Ignition_Status 1;
BA_ "U_P702_MY2021_Rx" SG_ 947 Ignition_Status 1;
BA_ "WakeupSignal" SG_ 947 Ignition_Status 1;
BA_ "U_CX727_MY2021_Rx" SG_ 947 Dimming_Lvl 1;
BA_ "U_CD764_MY2022_Rx" SG_ 947 Dimming_Lvl 1;
BA_ "U_U55X_MY2022_Rx" SG_ 947 Dimming_Lvl 1;
BA_ "U_CD542_MY2021_Rx" SG_ 947 Dimming_Lvl 1;
BA_ "U_T6_MCA_MY2020_Rx" SG_ 947 Dimming_Lvl 1;
BA_ "U_P702_MY2021_Rx" SG_ 947 Dimming_Lvl 1;
BA_ "GenSigStartValue" SG_ 947 Dimming_Lvl 12;
BA_ "GenSigStartValueInteger" SG_ 947 Dimming_Lvl 12;
BA_ "WakeupSignal" SG_ 947 Dimming_Lvl 1;
BA_ "U_CX727_MY2021_Rx" SG_ 947 Day_Night_Status 1;
BA_ "U_CD764_MY2022_Rx" SG_ 947 Day_Night_Status 1;
BA_ "U_U55X_MY2022_Rx" SG_ 947 Day_Night_Status 1;
BA_ "U_CD542_MY2021_Rx" SG_ 947 Day_Night_Status 1;
BA_ "U_T6_MCA_MY2020_Rx" SG_ 947 Day_Night_Status 1;
BA_ "U_P702_MY2021_Rx" SG_ 947 Day_Night_Status 1;
BA_ "WakeupSignal" SG_ 947 Day_Night_Status 1;
BA_ "U_CD764_MY2022_Rx" SG_ 947 Remote_Start_Status 1;
BA_ "U_CD542_MY2021_Rx" SG_ 947 Remote_Start_Status 1;
BA_ "U_U55X_MY2022_Rx" SG_ 947 Remote_Start_Status 1;
BA_ "U_T6_MCA_MY2020_Rx" SG_ 947 Remote_Start_Status 1;
BA_ "U_P702_MY2021_Rx" SG_ 947 Remote_Start_Status 1;
BA_ "U_CX727_MY2021_Rx" SG_ 947 Remote_Start_Status 1;
BA_ "WakeupSignal" SG_ 947 Remote_Start_Status 1;
BA_ "U_CD764_MY2022_Rx" SG_ 947 DrStatTgate_B_Actl 1;
BA_ "U_CD542_MY2021_Rx" SG_ 947 DrStatTgate_B_Actl 1;
BA_ "U_U55X_MY2022_Rx" SG_ 947 DrStatTgate_B_Actl 1;
BA_ "U_T6_MCA_MY2020_Rx" SG_ 947 DrStatTgate_B_Actl 1;
BA_ "U_P702_MY2021_Rx" SG_ 947 DrStatTgate_B_Actl 1;
BA_ "U_CX727_MY2021_Rx" SG_ 947 DrStatTgate_B_Actl 1;
BA_ "WakeupSignal" SG_ 947 DrStatTgate_B_Actl 1;
BA_ "U_CD764_MY2022_Rx" SG_ 947 DrStatRr_B_Actl 1;
BA_ "U_CD542_MY2021_Rx" SG_ 947 DrStatRr_B_Actl 1;
BA_ "U_U55X_MY2022_Rx" SG_ 947 DrStatRr_B_Actl 1;
BA_ "U_T6_MCA_MY2020_Rx" SG_ 947 DrStatRr_B_Actl 1;
BA_ "U_P702_MY2021_Rx" SG_ 947 DrStatRr_B_Actl 1;
BA_ "U_CX727_MY2021_Rx" SG_ 947 DrStatRr_B_Actl 1;
BA_ "WakeupSignal" SG_ 947 DrStatRr_B_Actl 1;
BA_ "U_CD764_MY2022_Rx" SG_ 947 DrStatRl_B_Actl 1;
BA_ "U_CD542_MY2021_Rx" SG_ 947 DrStatRl_B_Actl 1;
BA_ "U_U55X_MY2022_Rx" SG_ 947 DrStatRl_B_Actl 1;
BA_ "U_T6_MCA_MY2020_Rx" SG_ 947 DrStatRl_B_Actl 1;
BA_ "U_P702_MY2021_Rx" SG_ 947 DrStatRl_B_Actl 1;
BA_ "U_CX727_MY2021_Rx" SG_ 947 DrStatRl_B_Actl 1;
BA_ "WakeupSignal" SG_ 947 DrStatRl_B_Actl 1;
BA_ "U_CD764_MY2022_Rx" SG_ 947 DrStatPsngr_B_Actl 1;
BA_ "U_U55X_MY2022_Rx" SG_ 947 DrStatPsngr_B_Actl 1;
BA_ "U_CD542_MY2021_Rx" SG_ 947 DrStatPsngr_B_Actl 1;
BA_ "U_T6_MCA_MY2020_Rx" SG_ 947 DrStatPsngr_B_Actl 1;
BA_ "U_P702_MY2021_Rx" SG_ 947 DrStatPsngr_B_Actl 1;
BA_ "U_CX727_MY2021_Rx" SG_ 947 DrStatPsngr_B_Actl 1;
BA_ "WakeupSignal" SG_ 947 DrStatPsngr_B_Actl 1;
BA_ "U_CD764_MY2022_Rx" SG_ 947 DrStatInnrTgate_B_Actl 1;
BA_ "U_CD542_MY2021_Rx" SG_ 947 DrStatInnrTgate_B_Actl 1;
BA_ "U_U55X_MY2022_Rx" SG_ 947 DrStatInnrTgate_B_Actl 1;
BA_ "U_T6_MCA_MY2020_Rx" SG_ 947 DrStatInnrTgate_B_Actl 1;
BA_ "U_P702_MY2021_Rx" SG_ 947 DrStatInnrTgate_B_Actl 1;
BA_ "U_CX727_MY2021_Rx" SG_ 947 DrStatInnrTgate_B_Actl 1;
BA_ "WakeupSignal" SG_ 947 DrStatInnrTgate_B_Actl 1;
BA_ "U_U55X_MY2022_Rx" SG_ 947 DrStatHood_B_Actl 1;
BA_ "U_T6_MCA_MY2020_Rx" SG_ 947 DrStatHood_B_Actl 1;
BA_ "U_P702_MY2021_Rx" SG_ 947 DrStatHood_B_Actl 1;
BA_ "U_CX727_MY2021_Rx" SG_ 947 DrStatHood_B_Actl 1;
BA_ "WakeupSignal" SG_ 947 DrStatHood_B_Actl 1;
BA_ "U_CD764_MY2022_Rx" SG_ 947 DrStatDrv_B_Actl 1;
BA_ "U_U55X_MY2022_Rx" SG_ 947 DrStatDrv_B_Actl 1;
BA_ "U_CD542_MY2021_Rx" SG_ 947 DrStatDrv_B_Actl 1;
BA_ "U_T6_MCA_MY2020_Rx" SG_ 947 DrStatDrv_B_Actl 1;
BA_ "U_P702_MY2021_Rx" SG_ 947 DrStatDrv_B_Actl 1;
BA_ "U_CX727_MY2021_Rx" SG_ 947 DrStatDrv_B_Actl 1;
BA_ "WakeupSignal" SG_ 947 DrStatDrv_B_Actl 1;
BA_ "U_CX727_MY2021_Rx" SG_ 947 PrkBrkActv_B_Actl 1;
BA_ "ContentDependant" SG_ 947 PrkBrkActv_B_Actl 1;
BA_ "WakeupSignal" SG_ 947 PrkBrkActv_B_Actl 1;
BA_ "U_CX727_MY2021_Rx" SG_ 947 LifeCycMde_D_Actl 1;
BA_ "U_CD764_MY2022_Rx" SG_ 947 LifeCycMde_D_Actl 1;
BA_ "U_U55X_MY2022_Rx" SG_ 947 LifeCycMde_D_Actl 1;
BA_ "U_CD542_MY2021_Rx" SG_ 947 LifeCycMde_D_Actl 1;
BA_ "U_T6_MCA_MY2020_Rx" SG_ 947 LifeCycMde_D_Actl 1;
BA_ "U_P702_MY2021_Rx" SG_ 947 LifeCycMde_D_Actl 1;
BA_ "U_CX727_MY2021_Rx" SG_ 947 Delay_Accy 1;
BA_ "U_CD764_MY2022_Rx" SG_ 947 Delay_Accy 1;
BA_ "U_U55X_MY2022_Rx" SG_ 947 Delay_Accy 1;
BA_ "U_CD542_MY2021_Rx" SG_ 947 Delay_Accy 1;
BA_ "U_P702_MY2021_Rx" SG_ 947 Delay_Accy 1;
BA_ "WakeupSignal" SG_ 947 Delay_Accy 1;
BA_ "U_CX727_MY2021_Rx" SG_ 947 TurnLghtLeft_D_Rq 1;
BA_ "U_CD764_MY2022_Rx" SG_ 947 TurnLghtLeft_D_Rq 1;
BA_ "U_U55X_MY2022_Rx" SG_ 947 TurnLghtLeft_D_Rq 1;
BA_ "U_CD542_MY2021_Rx" SG_ 947 TurnLghtLeft_D_Rq 1;
BA_ "U_T6_MCA_MY2020_Rx" SG_ 947 TurnLghtLeft_D_Rq 1;
BA_ "U_P702_MY2021_Rx" SG_ 947 TurnLghtLeft_D_Rq 1;
BA_ "WakeupSignal" SG_ 947 TurnLghtLeft_D_Rq 1;
BA_ "U_CD764_MY2022_Rx" SG_ 947 CrashEvnt_D_Stat 1;
BA_ "U_U55X_MY2022_Rx" SG_ 947 CrashEvnt_D_Stat 1;
BA_ "U_CX727_MY2021_Rx" SG_ 947 CrashEvnt_D_Stat 1;
BA_ "U_CD542_MY2021_Rx" SG_ 947 CrashEvnt_D_Stat 1;
BA_ "U_T6_MCA_MY2020_Rx" SG_ 947 CrashEvnt_D_Stat 1;
BA_ "U_P702_MY2021_Rx" SG_ 947 CrashEvnt_D_Stat 1;
BA_ "GenSigStartValue" SG_ 947 CrashEvnt_D_Stat 3;
BA_ "GenSigStartValueInteger" SG_ 947 CrashEvnt_D_Stat 3;
BA_ "WakeupSignal" SG_ 947 CrashEvnt_D_Stat 1;
BA_ "U_CD764_MY2022_Rx" SG_ 947 FuelPmpInhbt_B_Stat 1;
BA_ "U_U55X_MY2022_Rx" SG_ 947 FuelPmpInhbt_B_Stat 1;
BA_ "U_CD542_MY2021_Rx" SG_ 947 FuelPmpInhbt_B_Stat 1;
BA_ "U_T6_MCA_MY2020_Rx" SG_ 947 FuelPmpInhbt_B_Stat 1;
BA_ "U_P702_MY2021_Rx" SG_ 947 FuelPmpInhbt_B_Stat 1;
BA_ "U_CX727_MY2021_Rx" SG_ 947 FuelPmpInhbt_B_Stat 1;
BA_ "GenSigSendType" SG_ 1841 TesterPhysicalReqANT 3;
BA_ "U_U55X_MY2022_Rx" SG_ 1126 GpsUtcYr_No_Actl 1;
BA_ "U_U55X_MY2022_Rx" SG_ 1126 GpsUtcMnth_No_Actl 1;
BA_ "GenSigStartValue" SG_ 1126 GpsUtcMnth_No_Actl 1;
BA_ "GenSigStartValueInteger" SG_ 1126 GpsUtcMnth_No_Actl 1;
BA_ "U_U55X_MY2022_Rx" SG_ 1126 GpsUtcDay_No_Actl 1;
BA_ "GenSigStartValue" SG_ 1126 GpsUtcDay_No_Actl 1;
BA_ "GenSigStartValueInteger" SG_ 1126 GpsUtcDay_No_Actl 1;
BA_ "U_U55X_MY2022_Rx" SG_ 1126 GPS_UTC_seconds 1;
BA_ "U_U55X_MY2022_Rx" SG_ 1126 GPS_UTC_minutes 1;
BA_ "U_U55X_MY2022_Rx" SG_ 1126 GPS_UTC_hours 1;
BA_ "U_U55X_MY2022_Rx" SG_ 1126 GPS_Pdop 1;
BA_ "U_U55X_MY2022_Rx" SG_ 1126 GPS_Compass_direction 1;
BA_ "U_U55X_MY2022_Rx" SG_ 1126 GPS_Actual_vs_Infer_pos 1;
BA_ "GenSigSendType" SG_ 1126 GPS_Actual_vs_Infer_pos 1;
BA_ "U_U55X_MY2022_Rx" SG_ 1126 Gps_B_Falt 1;
BA_ "U_U55X_MY2022_Rx" SG_ 1125 GpsHsphLongEast_D_Actl 1;
BA_ "GenSigSendType" SG_ 1125 GpsHsphLongEast_D_Actl 1;
BA_ "U_U55X_MY2022_Rx" SG_ 1125 GpsHsphLattSth_D_Actl 1;
BA_ "U_U55X_MY2022_Rx" SG_ 1125 GPS_Longitude_Minutes 1;
BA_ "U_U55X_MY2022_Rx" SG_ 1125 GPS_Longitude_Min_dec 1;
BA_ "U_U55X_MY2022_Rx" SG_ 1125 GPS_Longitude_Degrees 1;
BA_ "GenSigStartValueInteger" SG_ 1125 GPS_Longitude_Degrees 179;
BA_ "U_U55X_MY2022_Rx" SG_ 1125 GPS_Latitude_Minutes 1;
BA_ "U_U55X_MY2022_Rx" SG_ 1125 GPS_Latitude_Min_dec 1;
BA_ "U_U55X_MY2022_Rx" SG_ 1125 GPS_Latitude_Degrees 1;
BA_ "U_CD764_MY2022_Rx" SG_ 992 MsgCntrPersIndex_D_Rq 1;
BA_ "U_U55X_MY2022_Rx" SG_ 992 MsgCntrPersIndex_D_Rq 1;
BA_ "U_CD542_MY2021_Rx" SG_ 992 MsgCntrPersIndex_D_Rq 1;
BA_ "U_T6_MCA_MY2020_Rx" SG_ 992 MsgCntrPersIndex_D_Rq 1;
BA_ "U_P702_MY2021_Rx" SG_ 992 MsgCntrPersIndex_D_Rq 1;
BA_ "U_CX727_MY2021_Rx" SG_ 992 MsgCntrPersIndex_D_Rq 1;
BA_ "GenSigStartValue" SG_ 992 MsgCntrPersIndex_D_Rq 4;
BA_ "GenSigStartValueInteger" SG_ 992 MsgCntrPersIndex_D_Rq 4;
BA_ "U_CD764_MY2022_Rx" SG_ 992 MsgCntrFeatConfigRq 1;
BA_ "U_U55X_MY2022_Rx" SG_ 992 MsgCntrFeatConfigRq 1;
BA_ "U_CD542_MY2021_Rx" SG_ 992 MsgCntrFeatConfigRq 1;
BA_ "U_T6_MCA_MY2020_Rx" SG_ 992 MsgCntrFeatConfigRq 1;
BA_ "U_P702_MY2021_Rx" SG_ 992 MsgCntrFeatConfigRq 1;
BA_ "U_CX727_MY2021_Rx" SG_ 992 MsgCntrFeatConfigRq 1;
BA_ "U_CD764_MY2022_Rx" SG_ 992 MsgCntrFeatNoRq 1;
BA_ "U_U55X_MY2022_Rx" SG_ 992 MsgCntrFeatNoRq 1;
BA_ "U_CD542_MY2021_Rx" SG_ 992 MsgCntrFeatNoRq 1;
BA_ "U_T6_MCA_MY2020_Rx" SG_ 992 MsgCntrFeatNoRq 1;
BA_ "U_P702_MY2021_Rx" SG_ 992 MsgCntrFeatNoRq 1;
BA_ "U_CX727_MY2021_Rx" SG_ 992 MsgCntrFeatNoRq 1;
BA_ "U_CD764_MY2022_Rx" SG_ 992 MsgCntrDsplyOp_D_Rq 1;
BA_ "U_U55X_MY2022_Rx" SG_ 992 MsgCntrDsplyOp_D_Rq 1;
BA_ "U_CD542_MY2021_Rx" SG_ 992 MsgCntrDsplyOp_D_Rq 1;
BA_ "U_T6_MCA_MY2020_Rx" SG_ 992 MsgCntrDsplyOp_D_Rq 1;
BA_ "U_P702_MY2021_Rx" SG_ 992 MsgCntrDsplyOp_D_Rq 1;
BA_ "U_CX727_MY2021_Rx" SG_ 992 MsgCntrDsplyOp_D_Rq 1;
BA_ "U_U55X_MY2022_Rx" SG_ 1127 GPS_Vdop 1;
BA_ "GenSigSendType" SG_ 1127 GPS_Vdop 1;
BA_ "U_U55X_MY2022_Rx" SG_ 1127 GPS_Speed 1;
BA_ "U_U55X_MY2022_Rx" SG_ 1127 GPS_Sat_num_in_view 1;
BA_ "U_U55X_MY2022_Rx" SG_ 1127 GPS_MSL_altitude 1;
BA_ "U_U55X_MY2022_Rx" SG_ 1127 GPS_Heading 1;
BA_ "U_U55X_MY2022_Rx" SG_ 1127 GPS_Hdop 1;
BA_ "U_U55X_MY2022_Rx" SG_ 1127 GPS_dimension 1;
BA_ "U_CD764_MY2022_Tx" SG_ 999 FeatNoFcimActl 1;
BA_ "U_U55X_MY2022_Tx" SG_ 999 FeatNoFcimActl 1;
BA_ "U_CD542_MY2021_Tx" SG_ 999 FeatNoFcimActl 1;
BA_ "U_T6_MCA_MY2020_Tx" SG_ 999 FeatNoFcimActl 1;
BA_ "U_P702_MY2021_Tx" SG_ 999 FeatNoFcimActl 1;
BA_ "U_CX727_MY2021_Tx" SG_ 999 FeatNoFcimActl 1;
BA_ "GenSigSendType" SG_ 999 FeatNoFcimActl 3;
BA_ "U_CD764_MY2022_Tx" SG_ 999 FeatConfigFcimActl 1;
BA_ "U_U55X_MY2022_Tx" SG_ 999 FeatConfigFcimActl 1;
BA_ "U_CD542_MY2021_Tx" SG_ 999 FeatConfigFcimActl 1;
BA_ "U_T6_MCA_MY2020_Tx" SG_ 999 FeatConfigFcimActl 1;
BA_ "U_P702_MY2021_Tx" SG_ 999 FeatConfigFcimActl 1;
BA_ "U_CX727_MY2021_Tx" SG_ 999 FeatConfigFcimActl 1;
BA_ "GenSigSendType" SG_ 999 FeatConfigFcimActl 3;
BA_ "U_CD764_MY2022_Tx" SG_ 999 PersIndexFcim_D_Actl 1;
BA_ "U_U55X_MY2022_Tx" SG_ 999 PersIndexFcim_D_Actl 1;
BA_ "U_CD542_MY2021_Tx" SG_ 999 PersIndexFcim_D_Actl 1;
BA_ "U_T6_MCA_MY2020_Tx" SG_ 999 PersIndexFcim_D_Actl 1;
BA_ "U_P702_MY2021_Tx" SG_ 999 PersIndexFcim_D_Actl 1;
BA_ "U_CX727_MY2021_Tx" SG_ 999 PersIndexFcim_D_Actl 1;
BA_ "GenSigSendType" SG_ 999 PersIndexFcim_D_Actl 3;
BA_ "GenSigStartValue" SG_ 999 PersIndexFcim_D_Actl 4;
BA_ "GenSigStartValueInteger" SG_ 999 PersIndexFcim_D_Actl 4;
BA_ "GenSigSendType" SG_ 2027 TesterPhysicalResAHCM 3;
BA_ "GenSigSendType" SG_ 2019 TesterPhysicalReqAHCM 3;
BA_ "U_CD764_MY2022_Tx" SG_ 862 HvacBlwrFront_D_Stat 1;
BA_ "U_U55X_MY2022_Tx" SG_ 862 HvacBlwrFront_D_Stat 1;
BA_ "U_CD542_MY2021_Tx" SG_ 862 HvacBlwrFront_D_Stat 1;
BA_ "U_T6_MCA_MY2020_Tx" SG_ 862 HvacBlwrFront_D_Stat 1;
BA_ "U_P702_MY2021_Tx" SG_ 862 HvacBlwrFront_D_Stat 1;
BA_ "U_CX727_MY2021_Tx" SG_ 862 HvacBlwrFront_D_Stat 1;
BA_ "U_CX727_MY2021_Rx" SG_ 862 HvacBlwrFront_D_Stat 1;
BA_ "U_CD764_MY2022_Rx" SG_ 862 HvacBlwrFront_D_Stat 1;
BA_ "U_U55X_MY2022_Rx" SG_ 862 HvacBlwrFront_D_Stat 1;
BA_ "U_CD542_MY2021_Rx" SG_ 862 HvacBlwrFront_D_Stat 1;
BA_ "U_T6_MCA_MY2020_Rx" SG_ 862 HvacBlwrFront_D_Stat 1;
BA_ "U_P702_MY2021_Rx" SG_ 862 HvacBlwrFront_D_Stat 1;
BA_ "GenSigSendType" SG_ 862 HvacBlwrFront_D_Stat 3;
BA_ "U_CD764_MY2022_Tx" SG_ 862 HvacRemoteStrt_N_Rq 1;
BA_ "U_U55X_MY2022_Tx" SG_ 862 HvacRemoteStrt_N_Rq 1;
BA_ "U_CD542_MY2021_Tx" SG_ 862 HvacRemoteStrt_N_Rq 1;
BA_ "U_T6_MCA_MY2020_Tx" SG_ 862 HvacRemoteStrt_N_Rq 1;
BA_ "U_CX727_MY2021_Tx" SG_ 862 HvacRemoteStrt_N_Rq 1;
BA_ "GenSigSendType" SG_ 862 HvacRemoteStrt_N_Rq 3;
BA_ "U_CD764_MY2022_Tx" SG_ 862 ClimtThrmlLoad_No_Actl 1;
BA_ "U_U55X_MY2022_Tx" SG_ 862 ClimtThrmlLoad_No_Actl 1;
BA_ "U_CD542_MY2021_Tx" SG_ 862 ClimtThrmlLoad_No_Actl 1;
BA_ "U_T6_MCA_MY2020_Tx" SG_ 862 ClimtThrmlLoad_No_Actl 1;
BA_ "U_P702_MY2021_Tx" SG_ 862 ClimtThrmlLoad_No_Actl 1;
BA_ "U_CX727_MY2021_Tx" SG_ 862 ClimtThrmlLoad_No_Actl 1;
BA_ "GenSigSendType" SG_ 862 ClimtThrmlLoad_No_Actl 3;
BA_ "GenSigStartValue" SG_ 862 ClimtThrmlLoad_No_Actl 255;
BA_ "GenSigStartValueInteger" SG_ 862 ClimtThrmlLoad_No_Actl 255;
BA_ "U_CD764_MY2022_Tx" SG_ 862 HvacRec_Pc_Est 1;
BA_ "U_U55X_MY2022_Tx" SG_ 862 HvacRec_Pc_Est 1;
BA_ "U_CD542_MY2021_Tx" SG_ 862 HvacRec_Pc_Est 1;
BA_ "U_T6_MCA_MY2020_Tx" SG_ 862 HvacRec_Pc_Est 1;
BA_ "U_P702_MY2021_Tx" SG_ 862 HvacRec_Pc_Est 1;
BA_ "U_CX727_MY2021_Tx" SG_ 862 HvacRec_Pc_Est 1;
BA_ "GenSigSendType" SG_ 862 HvacRec_Pc_Est 3;
BA_ "U_CD764_MY2022_Tx" SG_ 862 HvacAir_Flw_Est 1;
BA_ "U_U55X_MY2022_Tx" SG_ 862 HvacAir_Flw_Est 1;
BA_ "U_CD542_MY2021_Tx" SG_ 862 HvacAir_Flw_Est 1;
BA_ "U_T6_MCA_MY2020_Tx" SG_ 862 HvacAir_Flw_Est 1;
BA_ "U_P702_MY2021_Tx" SG_ 862 HvacAir_Flw_Est 1;
BA_ "U_CX727_MY2021_Tx" SG_ 862 HvacAir_Flw_Est 1;
BA_ "GenSigSendType" SG_ 862 HvacAir_Flw_Est 3;
BA_ "U_CD764_MY2022_Tx" SG_ 862 CamraDefog_B_Actl 1;
BA_ "U_U55X_MY2022_Tx" SG_ 862 CamraDefog_B_Actl 1;
BA_ "U_CD542_MY2021_Tx" SG_ 862 CamraDefog_B_Actl 1;
BA_ "U_T6_MCA_MY2020_Tx" SG_ 862 CamraDefog_B_Actl 1;
BA_ "U_CX727_MY2021_Tx" SG_ 862 CamraDefog_B_Actl 1;
BA_ "GenSigSendType" SG_ 862 CamraDefog_B_Actl 3;
BA_ "U_CD764_MY2022_Tx" SG_ 862 CabnAmb_Te_Actl 1;
BA_ "U_U55X_MY2022_Tx" SG_ 862 CabnAmb_Te_Actl 1;
BA_ "U_CD542_MY2021_Tx" SG_ 862 CabnAmb_Te_Actl 1;
BA_ "U_T6_MCA_MY2020_Tx" SG_ 862 CabnAmb_Te_Actl 1;
BA_ "U_P702_MY2021_Tx" SG_ 862 CabnAmb_Te_Actl 1;
BA_ "U_CX727_MY2021_Tx" SG_ 862 CabnAmb_Te_Actl 1;
BA_ "U_P702_MY2021_Rx" SG_ 862 CabnAmb_Te_Actl 1;
BA_ "U_CD542_MY2021_Rx" SG_ 862 CabnAmb_Te_Actl 1;
BA_ "U_T6_MCA_MY2020_Rx" SG_ 862 CabnAmb_Te_Actl 1;
BA_ "U_CX727_MY2021_Rx" SG_ 862 CabnAmb_Te_Actl 1;
BA_ "U_CD764_MY2022_Rx" SG_ 862 CabnAmb_Te_Actl 1;
BA_ "U_U55X_MY2022_Rx" SG_ 862 CabnAmb_Te_Actl 1;
BA_ "GenSigSendType" SG_ 862 CabnAmb_Te_Actl 3;
BA_ "GenSigStartValueInteger" SG_ 862 CabnAmb_Te_Actl 114;
BA_ "U_CD764_MY2022_Tx" SG_ 862 AutoStpHvacDelta_I_Est 1;
BA_ "U_U55X_MY2022_Tx" SG_ 862 AutoStpHvacDelta_I_Est 1;
BA_ "U_CD542_MY2021_Tx" SG_ 862 AutoStpHvacDelta_I_Est 1;
BA_ "U_T6_MCA_MY2020_Tx" SG_ 862 AutoStpHvacDelta_I_Est 1;
BA_ "U_CX727_MY2021_Tx" SG_ 862 AutoStpHvacDelta_I_Est 1;
BA_ "GenSigSendType" SG_ 862 AutoStpHvacDelta_I_Est 3;
BA_ "GenSigStartValueInteger" SG_ 862 AutoStpHvacDelta_I_Est 192;
BA_ "U_CD764_MY2022_Tx" SG_ 828 DrvSpotLight_B_Rq 1;
BA_ "U_T6_MCA_MY2020_Tx" SG_ 828 DrvSpotLight_B_Rq 1;
BA_ "U_CD764_MY2022_Rx" SG_ 828 DrvSpotLight_B_Rq 1;
BA_ "U_CD542_MY2021_Rx" SG_ 828 DrvSpotLight_B_Rq 1;
BA_ "U_T6_MCA_MY2020_Rx" SG_ 828 DrvSpotLight_B_Rq 1;
BA_ "GenSigSendType" SG_ 828 DrvSpotLight_B_Rq 3;
BA_ "U_CD764_MY2022_Tx" SG_ 828 SpotLghtRight_D_Stat 1;
BA_ "U_T6_MCA_MY2020_Tx" SG_ 828 SpotLghtRight_D_Stat 1;
BA_ "U_CD764_MY2022_Rx" SG_ 828 SpotLghtRight_D_Stat 1;
BA_ "U_U55X_MY2022_Rx" SG_ 828 SpotLghtRight_D_Stat 1;
BA_ "U_CD542_MY2021_Rx" SG_ 828 SpotLghtRight_D_Stat 1;
BA_ "ECGUsedRxSignal" SG_ 828 SpotLghtRight_D_Stat 1;
BA_ "U_T6_MCA_MY2020_Rx" SG_ 828 SpotLghtRight_D_Stat 1;
BA_ "GenSigSendType" SG_ 828 SpotLghtRight_D_Stat 3;
BA_ "U_CD764_MY2022_Tx" SG_ 828 RearPassWindowPos 1;
BA_ "U_U55X_MY2022_Tx" SG_ 828 RearPassWindowPos 1;
BA_ "U_CD542_MY2021_Tx" SG_ 828 RearPassWindowPos 1;
BA_ "U_T6_MCA_MY2020_Tx" SG_ 828 RearPassWindowPos 1;
BA_ "U_P702_MY2021_Tx" SG_ 828 RearPassWindowPos 1;
BA_ "ECGUsedRxSignal" SG_ 828 RearPassWindowPos 1;
BA_ "U_CD764_MY2022_Rx" SG_ 828 RearPassWindowPos 1;
BA_ "U_U55X_MY2022_Rx" SG_ 828 RearPassWindowPos 1;
BA_ "U_CD542_MY2021_Rx" SG_ 828 RearPassWindowPos 1;
BA_ "U_T6_MCA_MY2020_Rx" SG_ 828 RearPassWindowPos 1;
BA_ "U_P702_MY2021_Rx" SG_ 828 RearPassWindowPos 1;
BA_ "U_CX727_MY2021_Rx" SG_ 828 RearPassWindowPos 1;
BA_ "GenSigSendType" SG_ 828 RearPassWindowPos 3;
BA_ "WakeupSignal" SG_ 828 RearPassWindowPos 1;
BA_ "U_CD764_MY2022_Tx" SG_ 828 PassWindowPosition 1;
BA_ "U_U55X_MY2022_Tx" SG_ 828 PassWindowPosition 1;
BA_ "U_CD542_MY2021_Tx" SG_ 828 PassWindowPosition 1;
BA_ "U_T6_MCA_MY2020_Tx" SG_ 828 PassWindowPosition 1;
BA_ "U_P702_MY2021_Tx" SG_ 828 PassWindowPosition 1;
BA_ "ECGUsedRxSignal" SG_ 828 PassWindowPosition 1;
BA_ "U_CD764_MY2022_Rx" SG_ 828 PassWindowPosition 1;
BA_ "U_U55X_MY2022_Rx" SG_ 828 PassWindowPosition 1;
BA_ "U_CD542_MY2021_Rx" SG_ 828 PassWindowPosition 1;
BA_ "U_T6_MCA_MY2020_Rx" SG_ 828 PassWindowPosition 1;
BA_ "U_P702_MY2021_Rx" SG_ 828 PassWindowPosition 1;
BA_ "U_CX727_MY2021_Rx" SG_ 828 PassWindowPosition 1;
BA_ "GenSigSendType" SG_ 828 PassWindowPosition 3;
BA_ "WakeupSignal" SG_ 828 PassWindowPosition 1;
BA_ "U_CD764_MY2022_Tx" SG_ 828 SpotLghtLeft_D_Stat 1;
BA_ "U_T6_MCA_MY2020_Tx" SG_ 828 SpotLghtLeft_D_Stat 1;
BA_ "U_CD764_MY2022_Rx" SG_ 828 SpotLghtLeft_D_Stat 1;
BA_ "U_U55X_MY2022_Rx" SG_ 828 SpotLghtLeft_D_Stat 1;
BA_ "U_CD542_MY2021_Rx" SG_ 828 SpotLghtLeft_D_Stat 1;
BA_ "ECGUsedRxSignal" SG_ 828 SpotLghtLeft_D_Stat 1;
BA_ "U_T6_MCA_MY2020_Rx" SG_ 828 SpotLghtLeft_D_Stat 1;
BA_ "GenSigSendType" SG_ 828 SpotLghtLeft_D_Stat 3;
BA_ "U_U55X_MY2022_Rx" SG_ 1909 TesterPhysicalReqRGTM 1;
BA_ "U_CD542_MY2021_Rx" SG_ 1909 TesterPhysicalReqRGTM 1;
BA_ "U_T6_MCA_MY2020_Rx" SG_ 1909 TesterPhysicalReqRGTM 1;
BA_ "U_CX727_MY2021_Rx" SG_ 1909 TesterPhysicalReqRGTM 1;
BA_ "GenSigSendType" SG_ 1909 TesterPhysicalReqRGTM 3;
BA_ "U_U55X_MY2022_Tx" SG_ 1917 TesterPhysicalResRGTM 1;
BA_ "U_CD542_MY2021_Tx" SG_ 1917 TesterPhysicalResRGTM 1;
BA_ "U_T6_MCA_MY2020_Tx" SG_ 1917 TesterPhysicalResRGTM 1;
BA_ "U_CX727_MY2021_Tx" SG_ 1917 TesterPhysicalResRGTM 1;
BA_ "GenSigSendType" SG_ 1917 TesterPhysicalResRGTM 3;
BA_ "U_CD764_MY2022_Rx" SG_ 1860 TesterPhysicalReqDSM 1;
BA_ "U_U55X_MY2022_Rx" SG_ 1860 TesterPhysicalReqDSM 1;
BA_ "U_CD542_MY2021_Rx" SG_ 1860 TesterPhysicalReqDSM 1;
BA_ "U_T6_MCA_MY2020_Rx" SG_ 1860 TesterPhysicalReqDSM 1;
BA_ "U_P702_MY2021_Rx" SG_ 1860 TesterPhysicalReqDSM 1;
BA_ "U_CX727_MY2021_Rx" SG_ 1860 TesterPhysicalReqDSM 1;
BA_ "GenSigSendType" SG_ 1860 TesterPhysicalReqDSM 3;
BA_ "U_CD764_MY2022_Tx" SG_ 1868 TesterPhysicalResDSM 1;
BA_ "U_U55X_MY2022_Tx" SG_ 1868 TesterPhysicalResDSM 1;
BA_ "U_CD542_MY2021_Tx" SG_ 1868 TesterPhysicalResDSM 1;
BA_ "U_T6_MCA_MY2020_Tx" SG_ 1868 TesterPhysicalResDSM 1;
BA_ "U_P702_MY2021_Tx" SG_ 1868 TesterPhysicalResDSM 1;
BA_ "U_CX727_MY2021_Tx" SG_ 1868 TesterPhysicalResDSM 1;
BA_ "GenSigSendType" SG_ 1868 TesterPhysicalResDSM 3;
BA_ "U_CD764_MY2022_Rx" SG_ 1814 TesterPhysicalReqGWM_M1 1;
BA_ "U_U55X_MY2022_Rx" SG_ 1814 TesterPhysicalReqGWM_M1 1;
BA_ "U_CD542_MY2021_Rx" SG_ 1814 TesterPhysicalReqGWM_M1 1;
BA_ "ECGUsedRxSignal" SG_ 1814 TesterPhysicalReqGWM_M1 1;
BA_ "U_T6_MCA_MY2020_Rx" SG_ 1814 TesterPhysicalReqGWM_M1 1;
BA_ "GenSigSendType" SG_ 1814 TesterPhysicalReqGWM_M1 3;
BA_ "U_CD764_MY2022_Tx" SG_ 1822 TesterPhysicalResGWM_M1 1;
BA_ "U_U55X_MY2022_Tx" SG_ 1822 TesterPhysicalResGWM_M1 1;
BA_ "U_CD542_MY2021_Tx" SG_ 1822 TesterPhysicalResGWM_M1 1;
BA_ "ECGUsedTxSignal" SG_ 1822 TesterPhysicalResGWM_M1 1;
BA_ "U_T6_MCA_MY2020_Tx" SG_ 1822 TesterPhysicalResGWM_M1 1;
BA_ "GenSigSendType" SG_ 1822 TesterPhysicalResGWM_M1 3;
BA_ "U_CD764_MY2022_Tx" SG_ 826 Memory_3_Sw_Stat 1;
BA_ "U_U55X_MY2022_Tx" SG_ 826 Memory_3_Sw_Stat 1;
BA_ "U_CD542_MY2021_Tx" SG_ 826 Memory_3_Sw_Stat 1;
BA_ "U_T6_MCA_MY2020_Tx" SG_ 826 Memory_3_Sw_Stat 1;
BA_ "U_P702_MY2021_Tx" SG_ 826 Memory_3_Sw_Stat 1;
BA_ "U_CX727_MY2021_Tx" SG_ 826 Memory_3_Sw_Stat 1;
BA_ "U_CD764_MY2022_Rx" SG_ 826 Memory_3_Sw_Stat 1;
BA_ "U_CD542_MY2021_Rx" SG_ 826 Memory_3_Sw_Stat 1;
BA_ "U_T6_MCA_MY2020_Rx" SG_ 826 Memory_3_Sw_Stat 1;
BA_ "U_P702_MY2021_Rx" SG_ 826 Memory_3_Sw_Stat 1;
BA_ "U_CX727_MY2021_Rx" SG_ 826 Memory_3_Sw_Stat 1;
BA_ "GenSigSendType" SG_ 826 Memory_3_Sw_Stat 3;
BA_ "WakeupSignal" SG_ 826 Memory_3_Sw_Stat 1;
BA_ "U_CD764_MY2022_Tx" SG_ 826 Memory_2_Sw_Stat 1;
BA_ "U_U55X_MY2022_Tx" SG_ 826 Memory_2_Sw_Stat 1;
BA_ "U_CD542_MY2021_Tx" SG_ 826 Memory_2_Sw_Stat 1;
BA_ "U_T6_MCA_MY2020_Tx" SG_ 826 Memory_2_Sw_Stat 1;
BA_ "U_P702_MY2021_Tx" SG_ 826 Memory_2_Sw_Stat 1;
BA_ "U_CX727_MY2021_Tx" SG_ 826 Memory_2_Sw_Stat 1;
BA_ "U_CD764_MY2022_Rx" SG_ 826 Memory_2_Sw_Stat 1;
BA_ "U_CD542_MY2021_Rx" SG_ 826 Memory_2_Sw_Stat 1;
BA_ "U_T6_MCA_MY2020_Rx" SG_ 826 Memory_2_Sw_Stat 1;
BA_ "U_P702_MY2021_Rx" SG_ 826 Memory_2_Sw_Stat 1;
BA_ "U_CX727_MY2021_Rx" SG_ 826 Memory_2_Sw_Stat 1;
BA_ "GenSigSendType" SG_ 826 Memory_2_Sw_Stat 3;
BA_ "WakeupSignal" SG_ 826 Memory_2_Sw_Stat 1;
BA_ "U_CD764_MY2022_Tx" SG_ 826 Memory_1_Sw_Stat 1;
BA_ "U_U55X_MY2022_Tx" SG_ 826 Memory_1_Sw_Stat 1;
BA_ "U_CD542_MY2021_Tx" SG_ 826 Memory_1_Sw_Stat 1;
BA_ "U_T6_MCA_MY2020_Tx" SG_ 826 Memory_1_Sw_Stat 1;
BA_ "U_P702_MY2021_Tx" SG_ 826 Memory_1_Sw_Stat 1;
BA_ "U_CX727_MY2021_Tx" SG_ 826 Memory_1_Sw_Stat 1;
BA_ "U_CD764_MY2022_Rx" SG_ 826 Memory_1_Sw_Stat 1;
BA_ "U_CD542_MY2021_Rx" SG_ 826 Memory_1_Sw_Stat 1;
BA_ "U_T6_MCA_MY2020_Rx" SG_ 826 Memory_1_Sw_Stat 1;
BA_ "U_P702_MY2021_Rx" SG_ 826 Memory_1_Sw_Stat 1;
BA_ "U_CX727_MY2021_Rx" SG_ 826 Memory_1_Sw_Stat 1;
BA_ "GenSigSendType" SG_ 826 Memory_1_Sw_Stat 3;
BA_ "WakeupSignal" SG_ 826 Memory_1_Sw_Stat 1;
BA_ "U_CD764_MY2022_Tx" SG_ 826 Mirror_Manual_Override 1;
BA_ "U_U55X_MY2022_Tx" SG_ 826 Mirror_Manual_Override 1;
BA_ "U_CD542_MY2021_Tx" SG_ 826 Mirror_Manual_Override 1;
BA_ "U_T6_MCA_MY2020_Tx" SG_ 826 Mirror_Manual_Override 1;
BA_ "U_P702_MY2021_Tx" SG_ 826 Mirror_Manual_Override 1;
BA_ "U_CX727_MY2021_Tx" SG_ 826 Mirror_Manual_Override 1;
BA_ "U_CD764_MY2022_Rx" SG_ 826 Mirror_Manual_Override 1;
BA_ "U_CD542_MY2021_Rx" SG_ 826 Mirror_Manual_Override 1;
BA_ "U_T6_MCA_MY2020_Rx" SG_ 826 Mirror_Manual_Override 1;
BA_ "U_P702_MY2021_Rx" SG_ 826 Mirror_Manual_Override 1;
BA_ "U_CX727_MY2021_Rx" SG_ 826 Mirror_Manual_Override 1;
BA_ "GenSigSendType" SG_ 826 Mirror_Manual_Override 3;
BA_ "WakeupSignal" SG_ 826 Mirror_Manual_Override 1;
BA_ "U_CD764_MY2022_Tx" SG_ 853 RHS_Htd_Seat_Btn_Stt 1;
BA_ "U_U55X_MY2022_Tx" SG_ 853 RHS_Htd_Seat_Btn_Stt 1;
BA_ "U_CD542_MY2021_Tx" SG_ 853 RHS_Htd_Seat_Btn_Stt 1;
BA_ "U_T6_MCA_MY2020_Tx" SG_ 853 RHS_Htd_Seat_Btn_Stt 1;
BA_ "U_P702_MY2021_Tx" SG_ 853 RHS_Htd_Seat_Btn_Stt 1;
BA_ "U_CX727_MY2021_Tx" SG_ 853 RHS_Htd_Seat_Btn_Stt 1;
BA_ "GenSigSendType" SG_ 853 RHS_Htd_Seat_Btn_Stt 3;
BA_ "GenSigStartValue" SG_ 853 RHS_Htd_Seat_Btn_Stt 2;
BA_ "GenSigStartValueInteger" SG_ 853 RHS_Htd_Seat_Btn_Stt 2;
BA_ "U_CD764_MY2022_Tx" SG_ 853 RHS_Cld_Seat_Btn_Stt 1;
BA_ "U_U55X_MY2022_Tx" SG_ 853 RHS_Cld_Seat_Btn_Stt 1;
BA_ "U_CD542_MY2021_Tx" SG_ 853 RHS_Cld_Seat_Btn_Stt 1;
BA_ "U_T6_MCA_MY2020_Tx" SG_ 853 RHS_Cld_Seat_Btn_Stt 1;
BA_ "U_P702_MY2021_Tx" SG_ 853 RHS_Cld_Seat_Btn_Stt 1;
BA_ "U_CX727_MY2021_Tx" SG_ 853 RHS_Cld_Seat_Btn_Stt 1;
BA_ "GenSigSendType" SG_ 853 RHS_Cld_Seat_Btn_Stt 3;
BA_ "GenSigStartValue" SG_ 853 RHS_Cld_Seat_Btn_Stt 2;
BA_ "GenSigStartValueInteger" SG_ 853 RHS_Cld_Seat_Btn_Stt 2;
BA_ "U_CD764_MY2022_Tx" SG_ 853 Outside_Btn_Stt 1;
BA_ "U_U55X_MY2022_Tx" SG_ 853 Outside_Btn_Stt 1;
BA_ "U_CD542_MY2021_Tx" SG_ 853 Outside_Btn_Stt 1;
BA_ "U_T6_MCA_MY2020_Tx" SG_ 853 Outside_Btn_Stt 1;
BA_ "U_P702_MY2021_Tx" SG_ 853 Outside_Btn_Stt 1;
BA_ "U_CX727_MY2021_Tx" SG_ 853 Outside_Btn_Stt 1;
BA_ "GenSigSendType" SG_ 853 Outside_Btn_Stt 3;
BA_ "GenSigStartValue" SG_ 853 Outside_Btn_Stt 2;
BA_ "GenSigStartValueInteger" SG_ 853 Outside_Btn_Stt 2;
BA_ "U_CD764_MY2022_Tx" SG_ 853 LHS_Htd_Seat_Btn_Stt 1;
BA_ "U_U55X_MY2022_Tx" SG_ 853 LHS_Htd_Seat_Btn_Stt 1;
BA_ "U_CD542_MY2021_Tx" SG_ 853 LHS_Htd_Seat_Btn_Stt 1;
BA_ "U_T6_MCA_MY2020_Tx" SG_ 853 LHS_Htd_Seat_Btn_Stt 1;
BA_ "U_P702_MY2021_Tx" SG_ 853 LHS_Htd_Seat_Btn_Stt 1;
BA_ "U_CX727_MY2021_Tx" SG_ 853 LHS_Htd_Seat_Btn_Stt 1;
BA_ "GenSigSendType" SG_ 853 LHS_Htd_Seat_Btn_Stt 3;
BA_ "GenSigStartValue" SG_ 853 LHS_Htd_Seat_Btn_Stt 2;
BA_ "GenSigStartValueInteger" SG_ 853 LHS_Htd_Seat_Btn_Stt 2;
BA_ "U_CD764_MY2022_Tx" SG_ 853 LHS_Cld_Seat_Btn_Stt 1;
BA_ "U_U55X_MY2022_Tx" SG_ 853 LHS_Cld_Seat_Btn_Stt 1;
BA_ "U_CD542_MY2021_Tx" SG_ 853 LHS_Cld_Seat_Btn_Stt 1;
BA_ "U_T6_MCA_MY2020_Tx" SG_ 853 LHS_Cld_Seat_Btn_Stt 1;
BA_ "U_P702_MY2021_Tx" SG_ 853 LHS_Cld_Seat_Btn_Stt 1;
BA_ "U_CX727_MY2021_Tx" SG_ 853 LHS_Cld_Seat_Btn_Stt 1;
BA_ "GenSigSendType" SG_ 853 LHS_Cld_Seat_Btn_Stt 3;
BA_ "GenSigStartValue" SG_ 853 LHS_Cld_Seat_Btn_Stt 2;
BA_ "GenSigStartValueInteger" SG_ 853 LHS_Cld_Seat_Btn_Stt 2;
BA_ "U_CD764_MY2022_Tx" SG_ 853 FrontMnu_Buttn_Stat 1;
BA_ "U_U55X_MY2022_Tx" SG_ 853 FrontMnu_Buttn_Stat 1;
BA_ "U_CD542_MY2021_Tx" SG_ 853 FrontMnu_Buttn_Stat 1;
BA_ "U_T6_MCA_MY2020_Tx" SG_ 853 FrontMnu_Buttn_Stat 1;
BA_ "U_P702_MY2021_Tx" SG_ 853 FrontMnu_Buttn_Stat 1;
BA_ "U_CX727_MY2021_Tx" SG_ 853 FrontMnu_Buttn_Stat 1;
BA_ "GenSigSendType" SG_ 853 FrontMnu_Buttn_Stat 3;
BA_ "U_CD764_MY2022_Tx" SG_ 853 Defrost_Btn_Stt 1;
BA_ "U_U55X_MY2022_Tx" SG_ 853 Defrost_Btn_Stt 1;
BA_ "U_CD542_MY2021_Tx" SG_ 853 Defrost_Btn_Stt 1;
BA_ "U_T6_MCA_MY2020_Tx" SG_ 853 Defrost_Btn_Stt 1;
BA_ "U_P702_MY2021_Tx" SG_ 853 Defrost_Btn_Stt 1;
BA_ "U_CX727_MY2021_Tx" SG_ 853 Defrost_Btn_Stt 1;
BA_ "GenSigSendType" SG_ 853 Defrost_Btn_Stt 3;
BA_ "GenSigStartValue" SG_ 853 Defrost_Btn_Stt 2;
BA_ "GenSigStartValueInteger" SG_ 853 Defrost_Btn_Stt 2;
BA_ "U_CD764_MY2022_Tx" SG_ 853 Auto_Recirc_Btn_Stt 1;
BA_ "U_U55X_MY2022_Tx" SG_ 853 Auto_Recirc_Btn_Stt 1;
BA_ "U_CD542_MY2021_Tx" SG_ 853 Auto_Recirc_Btn_Stt 1;
BA_ "U_T6_MCA_MY2020_Tx" SG_ 853 Auto_Recirc_Btn_Stt 1;
BA_ "U_P702_MY2021_Tx" SG_ 853 Auto_Recirc_Btn_Stt 1;
BA_ "U_CX727_MY2021_Tx" SG_ 853 Auto_Recirc_Btn_Stt 1;
BA_ "GenSigSendType" SG_ 853 Auto_Recirc_Btn_Stt 3;
BA_ "GenSigStartValue" SG_ 853 Auto_Recirc_Btn_Stt 2;
BA_ "GenSigStartValueInteger" SG_ 853 Auto_Recirc_Btn_Stt 2;
BA_ "U_CD764_MY2022_Tx" SG_ 853 Front_AUTO_Blwr_Lvl 1;
BA_ "U_U55X_MY2022_Tx" SG_ 853 Front_AUTO_Blwr_Lvl 1;
BA_ "U_CD542_MY2021_Tx" SG_ 853 Front_AUTO_Blwr_Lvl 1;
BA_ "U_T6_MCA_MY2020_Tx" SG_ 853 Front_AUTO_Blwr_Lvl 1;
BA_ "U_P702_MY2021_Tx" SG_ 853 Front_AUTO_Blwr_Lvl 1;
BA_ "U_CX727_MY2021_Tx" SG_ 853 Front_AUTO_Blwr_Lvl 1;
BA_ "GenSigSendType" SG_ 853 Front_AUTO_Blwr_Lvl 3;
BA_ "U_CD764_MY2022_Tx" SG_ 853 RHS_Cond_Seat_Status 1;
BA_ "U_U55X_MY2022_Tx" SG_ 853 RHS_Cond_Seat_Status 1;
BA_ "U_CD542_MY2021_Tx" SG_ 853 RHS_Cond_Seat_Status 1;
BA_ "U_T6_MCA_MY2020_Tx" SG_ 853 RHS_Cond_Seat_Status 1;
BA_ "U_P702_MY2021_Tx" SG_ 853 RHS_Cond_Seat_Status 1;
BA_ "U_CX727_MY2021_Tx" SG_ 853 RHS_Cond_Seat_Status 1;
BA_ "GenSigSendType" SG_ 853 RHS_Cond_Seat_Status 3;
BA_ "U_CD764_MY2022_Tx" SG_ 853 LHS_Cond_Seat_Status 1;
BA_ "U_U55X_MY2022_Tx" SG_ 853 LHS_Cond_Seat_Status 1;
BA_ "U_CD542_MY2021_Tx" SG_ 853 LHS_Cond_Seat_Status 1;
BA_ "U_T6_MCA_MY2020_Tx" SG_ 853 LHS_Cond_Seat_Status 1;
BA_ "U_P702_MY2021_Tx" SG_ 853 LHS_Cond_Seat_Status 1;
BA_ "U_CX727_MY2021_Tx" SG_ 853 LHS_Cond_Seat_Status 1;
BA_ "GenSigSendType" SG_ 853 LHS_Cond_Seat_Status 3;
BA_ "U_CD764_MY2022_Tx" SG_ 853 Htd_Strg_Whl_Status 1;
BA_ "U_U55X_MY2022_Tx" SG_ 853 Htd_Strg_Whl_Status 1;
BA_ "U_CD542_MY2021_Tx" SG_ 853 Htd_Strg_Whl_Status 1;
BA_ "U_T6_MCA_MY2020_Tx" SG_ 853 Htd_Strg_Whl_Status 1;
BA_ "U_P702_MY2021_Tx" SG_ 853 Htd_Strg_Whl_Status 1;
BA_ "U_CX727_MY2021_Tx" SG_ 853 Htd_Strg_Whl_Status 1;
BA_ "GenSigSendType" SG_ 853 Htd_Strg_Whl_Status 3;
BA_ "GenSigStartValue" SG_ 853 Htd_Strg_Whl_Status 2;
BA_ "GenSigStartValueInteger" SG_ 853 Htd_Strg_Whl_Status 2;
BA_ "U_CD764_MY2022_Tx" SG_ 853 Htd_Strg_Whl_Btn_Stt 1;
BA_ "U_U55X_MY2022_Tx" SG_ 853 Htd_Strg_Whl_Btn_Stt 1;
BA_ "U_CD542_MY2021_Tx" SG_ 853 Htd_Strg_Whl_Btn_Stt 1;
BA_ "U_T6_MCA_MY2020_Tx" SG_ 853 Htd_Strg_Whl_Btn_Stt 1;
BA_ "U_P702_MY2021_Tx" SG_ 853 Htd_Strg_Whl_Btn_Stt 1;
BA_ "U_CX727_MY2021_Tx" SG_ 853 Htd_Strg_Whl_Btn_Stt 1;
BA_ "GenSigSendType" SG_ 853 Htd_Strg_Whl_Btn_Stt 3;
BA_ "GenSigStartValue" SG_ 853 Htd_Strg_Whl_Btn_Stt 2;
BA_ "GenSigStartValueInteger" SG_ 853 Htd_Strg_Whl_Btn_Stt 2;
BA_ "U_CD764_MY2022_Tx" SG_ 853 CC_Fr_Btn_User_Adj 1;
BA_ "U_U55X_MY2022_Tx" SG_ 853 CC_Fr_Btn_User_Adj 1;
BA_ "U_CD542_MY2021_Tx" SG_ 853 CC_Fr_Btn_User_Adj 1;
BA_ "U_T6_MCA_MY2020_Tx" SG_ 853 CC_Fr_Btn_User_Adj 1;
BA_ "U_P702_MY2021_Tx" SG_ 853 CC_Fr_Btn_User_Adj 1;
BA_ "U_CX727_MY2021_Tx" SG_ 853 CC_Fr_Btn_User_Adj 1;
BA_ "GenSigSendType" SG_ 853 CC_Fr_Btn_User_Adj 3;
BA_ "U_CD764_MY2022_Tx" SG_ 853 Htd_Frt_Wsh_Btn_Stt 1;
BA_ "U_U55X_MY2022_Tx" SG_ 853 Htd_Frt_Wsh_Btn_Stt 1;
BA_ "U_CD542_MY2021_Tx" SG_ 853 Htd_Frt_Wsh_Btn_Stt 1;
BA_ "U_T6_MCA_MY2020_Tx" SG_ 853 Htd_Frt_Wsh_Btn_Stt 1;
BA_ "U_P702_MY2021_Tx" SG_ 853 Htd_Frt_Wsh_Btn_Stt 1;
BA_ "U_CX727_MY2021_Tx" SG_ 853 Htd_Frt_Wsh_Btn_Stt 1;
BA_ "GenSigSendType" SG_ 853 Htd_Frt_Wsh_Btn_Stt 3;
BA_ "GenSigStartValue" SG_ 853 Htd_Frt_Wsh_Btn_Stt 2;
BA_ "GenSigStartValueInteger" SG_ 853 Htd_Frt_Wsh_Btn_Stt 2;
BA_ "U_CD764_MY2022_Tx" SG_ 853 Recirc_Btn_Stt 1;
BA_ "U_U55X_MY2022_Tx" SG_ 853 Recirc_Btn_Stt 1;
BA_ "U_CD542_MY2021_Tx" SG_ 853 Recirc_Btn_Stt 1;
BA_ "U_T6_MCA_MY2020_Tx" SG_ 853 Recirc_Btn_Stt 1;
BA_ "U_P702_MY2021_Tx" SG_ 853 Recirc_Btn_Stt 1;
BA_ "U_CX727_MY2021_Tx" SG_ 853 Recirc_Btn_Stt 1;
BA_ "U_CD542_MY2021_Rx" SG_ 853 Recirc_Btn_Stt 1;
BA_ "U_T6_MCA_MY2020_Rx" SG_ 853 Recirc_Btn_Stt 1;
BA_ "U_CX727_MY2021_Rx" SG_ 853 Recirc_Btn_Stt 1;
BA_ "GenSigSendType" SG_ 853 Recirc_Btn_Stt 3;
BA_ "GenSigStartValue" SG_ 853 Recirc_Btn_Stt 2;
BA_ "GenSigStartValueInteger" SG_ 853 Recirc_Btn_Stt 2;
BA_ "U_CD764_MY2022_Tx" SG_ 853 Rear_Defrost_Btn_Stt 1;
BA_ "U_U55X_MY2022_Tx" SG_ 853 Rear_Defrost_Btn_Stt 1;
BA_ "U_CD542_MY2021_Tx" SG_ 853 Rear_Defrost_Btn_Stt 1;
BA_ "U_T6_MCA_MY2020_Tx" SG_ 853 Rear_Defrost_Btn_Stt 1;
BA_ "U_P702_MY2021_Tx" SG_ 853 Rear_Defrost_Btn_Stt 1;
BA_ "U_CX727_MY2021_Tx" SG_ 853 Rear_Defrost_Btn_Stt 1;
BA_ "GenSigSendType" SG_ 853 Rear_Defrost_Btn_Stt 3;
BA_ "GenSigStartValue" SG_ 853 Rear_Defrost_Btn_Stt 2;
BA_ "GenSigStartValueInteger" SG_ 853 Rear_Defrost_Btn_Stt 2;
BA_ "U_CD764_MY2022_Tx" SG_ 853 My_Temp_Btn_Stt 1;
BA_ "U_U55X_MY2022_Tx" SG_ 853 My_Temp_Btn_Stt 1;
BA_ "U_CD542_MY2021_Tx" SG_ 853 My_Temp_Btn_Stt 1;
BA_ "U_T6_MCA_MY2020_Tx" SG_ 853 My_Temp_Btn_Stt 1;
BA_ "U_P702_MY2021_Tx" SG_ 853 My_Temp_Btn_Stt 1;
BA_ "U_CX727_MY2021_Tx" SG_ 853 My_Temp_Btn_Stt 1;
BA_ "GenSigSendType" SG_ 853 My_Temp_Btn_Stt 3;
BA_ "GenSigStartValue" SG_ 853 My_Temp_Btn_Stt 2;
BA_ "GenSigStartValueInteger" SG_ 853 My_Temp_Btn_Stt 2;
BA_ "U_CD764_MY2022_Tx" SG_ 853 Max_Defrost_Btn_Stt 1;
BA_ "U_U55X_MY2022_Tx" SG_ 853 Max_Defrost_Btn_Stt 1;
BA_ "U_CD542_MY2021_Tx" SG_ 853 Max_Defrost_Btn_Stt 1;
BA_ "U_T6_MCA_MY2020_Tx" SG_ 853 Max_Defrost_Btn_Stt 1;
BA_ "U_P702_MY2021_Tx" SG_ 853 Max_Defrost_Btn_Stt 1;
BA_ "U_CX727_MY2021_Tx" SG_ 853 Max_Defrost_Btn_Stt 1;
BA_ "GenSigSendType" SG_ 853 Max_Defrost_Btn_Stt 3;
BA_ "GenSigStartValue" SG_ 853 Max_Defrost_Btn_Stt 2;
BA_ "GenSigStartValueInteger" SG_ 853 Max_Defrost_Btn_Stt 2;
BA_ "U_CD764_MY2022_Tx" SG_ 853 Max_AC_Btn_Stt 1;
BA_ "U_U55X_MY2022_Tx" SG_ 853 Max_AC_Btn_Stt 1;
BA_ "U_CD542_MY2021_Tx" SG_ 853 Max_AC_Btn_Stt 1;
BA_ "U_T6_MCA_MY2020_Tx" SG_ 853 Max_AC_Btn_Stt 1;
BA_ "U_P702_MY2021_Tx" SG_ 853 Max_AC_Btn_Stt 1;
BA_ "U_CX727_MY2021_Tx" SG_ 853 Max_AC_Btn_Stt 1;
BA_ "GenSigSendType" SG_ 853 Max_AC_Btn_Stt 3;
BA_ "GenSigStartValue" SG_ 853 Max_AC_Btn_Stt 2;
BA_ "GenSigStartValueInteger" SG_ 853 Max_AC_Btn_Stt 2;
BA_ "U_CD764_MY2022_Tx" SG_ 853 Front_AUTO_Label 1;
BA_ "U_U55X_MY2022_Tx" SG_ 853 Front_AUTO_Label 1;
BA_ "U_CD542_MY2021_Tx" SG_ 853 Front_AUTO_Label 1;
BA_ "U_T6_MCA_MY2020_Tx" SG_ 853 Front_AUTO_Label 1;
BA_ "U_P702_MY2021_Tx" SG_ 853 Front_AUTO_Label 1;
BA_ "U_CX727_MY2021_Tx" SG_ 853 Front_AUTO_Label 1;
BA_ "GenSigSendType" SG_ 853 Front_AUTO_Label 3;
BA_ "GenSigStartValue" SG_ 853 Front_AUTO_Label 2;
BA_ "GenSigStartValueInteger" SG_ 853 Front_AUTO_Label 2;
BA_ "U_CD764_MY2022_Tx" SG_ 853 Windscreen_Btn_Stt 1;
BA_ "U_U55X_MY2022_Tx" SG_ 853 Windscreen_Btn_Stt 1;
BA_ "U_CD542_MY2021_Tx" SG_ 853 Windscreen_Btn_Stt 1;
BA_ "U_T6_MCA_MY2020_Tx" SG_ 853 Windscreen_Btn_Stt 1;
BA_ "U_P702_MY2021_Tx" SG_ 853 Windscreen_Btn_Stt 1;
BA_ "U_CX727_MY2021_Tx" SG_ 853 Windscreen_Btn_Stt 1;
BA_ "GenSigSendType" SG_ 853 Windscreen_Btn_Stt 3;
BA_ "GenSigStartValue" SG_ 853 Windscreen_Btn_Stt 2;
BA_ "GenSigStartValueInteger" SG_ 853 Windscreen_Btn_Stt 2;
BA_ "U_CD764_MY2022_Tx" SG_ 853 Panel_Btn_Stt 1;
BA_ "U_U55X_MY2022_Tx" SG_ 853 Panel_Btn_Stt 1;
BA_ "U_CD542_MY2021_Tx" SG_ 853 Panel_Btn_Stt 1;
BA_ "U_T6_MCA_MY2020_Tx" SG_ 853 Panel_Btn_Stt 1;
BA_ "U_P702_MY2021_Tx" SG_ 853 Panel_Btn_Stt 1;
BA_ "U_CX727_MY2021_Tx" SG_ 853 Panel_Btn_Stt 1;
BA_ "GenSigSendType" SG_ 853 Panel_Btn_Stt 3;
BA_ "GenSigStartValue" SG_ 853 Panel_Btn_Stt 2;
BA_ "GenSigStartValueInteger" SG_ 853 Panel_Btn_Stt 2;
BA_ "U_CD764_MY2022_Tx" SG_ 853 Front_Power_Btn_Stt 1;
BA_ "U_U55X_MY2022_Tx" SG_ 853 Front_Power_Btn_Stt 1;
BA_ "U_CD542_MY2021_Tx" SG_ 853 Front_Power_Btn_Stt 1;
BA_ "U_T6_MCA_MY2020_Tx" SG_ 853 Front_Power_Btn_Stt 1;
BA_ "U_P702_MY2021_Tx" SG_ 853 Front_Power_Btn_Stt 1;
BA_ "U_CX727_MY2021_Tx" SG_ 853 Front_Power_Btn_Stt 1;
BA_ "GenSigSendType" SG_ 853 Front_Power_Btn_Stt 3;
BA_ "GenSigStartValue" SG_ 853 Front_Power_Btn_Stt 2;
BA_ "GenSigStartValueInteger" SG_ 853 Front_Power_Btn_Stt 2;
BA_ "U_CD764_MY2022_Tx" SG_ 853 Front_AUTO_Btn_Stt 1;
BA_ "U_U55X_MY2022_Tx" SG_ 853 Front_AUTO_Btn_Stt 1;
BA_ "U_CD542_MY2021_Tx" SG_ 853 Front_AUTO_Btn_Stt 1;
BA_ "U_T6_MCA_MY2020_Tx" SG_ 853 Front_AUTO_Btn_Stt 1;
BA_ "U_P702_MY2021_Tx" SG_ 853 Front_AUTO_Btn_Stt 1;
BA_ "U_CX727_MY2021_Tx" SG_ 853 Front_AUTO_Btn_Stt 1;
BA_ "GenSigSendType" SG_ 853 Front_AUTO_Btn_Stt 3;
BA_ "GenSigStartValue" SG_ 853 Front_AUTO_Btn_Stt 2;
BA_ "GenSigStartValueInteger" SG_ 853 Front_AUTO_Btn_Stt 2;
BA_ "U_CD764_MY2022_Tx" SG_ 853 Floor_Btn_Stt 1;
BA_ "U_U55X_MY2022_Tx" SG_ 853 Floor_Btn_Stt 1;
BA_ "U_CD542_MY2021_Tx" SG_ 853 Floor_Btn_Stt 1;
BA_ "U_T6_MCA_MY2020_Tx" SG_ 853 Floor_Btn_Stt 1;
BA_ "U_P702_MY2021_Tx" SG_ 853 Floor_Btn_Stt 1;
BA_ "U_CX727_MY2021_Tx" SG_ 853 Floor_Btn_Stt 1;
BA_ "GenSigSendType" SG_ 853 Floor_Btn_Stt 3;
BA_ "GenSigStartValue" SG_ 853 Floor_Btn_Stt 2;
BA_ "GenSigStartValueInteger" SG_ 853 Floor_Btn_Stt 2;
BA_ "U_CD764_MY2022_Tx" SG_ 853 Dual_Button_Stt 1;
BA_ "U_U55X_MY2022_Tx" SG_ 853 Dual_Button_Stt 1;
BA_ "U_CD542_MY2021_Tx" SG_ 853 Dual_Button_Stt 1;
BA_ "U_T6_MCA_MY2020_Tx" SG_ 853 Dual_Button_Stt 1;
BA_ "U_P702_MY2021_Tx" SG_ 853 Dual_Button_Stt 1;
BA_ "U_CX727_MY2021_Tx" SG_ 853 Dual_Button_Stt 1;
BA_ "GenSigSendType" SG_ 853 Dual_Button_Stt 3;
BA_ "GenSigStartValue" SG_ 853 Dual_Button_Stt 2;
BA_ "GenSigStartValueInteger" SG_ 853 Dual_Button_Stt 2;
BA_ "U_CD764_MY2022_Tx" SG_ 853 AC_Btn_Stt 1;
BA_ "U_U55X_MY2022_Tx" SG_ 853 AC_Btn_Stt 1;
BA_ "U_CD542_MY2021_Tx" SG_ 853 AC_Btn_Stt 1;
BA_ "U_T6_MCA_MY2020_Tx" SG_ 853 AC_Btn_Stt 1;
BA_ "U_P702_MY2021_Tx" SG_ 853 AC_Btn_Stt 1;
BA_ "U_CX727_MY2021_Tx" SG_ 853 AC_Btn_Stt 1;
BA_ "GenSigSendType" SG_ 853 AC_Btn_Stt 3;
BA_ "GenSigStartValue" SG_ 853 AC_Btn_Stt 2;
BA_ "GenSigStartValueInteger" SG_ 853 AC_Btn_Stt 2;
BA_ "U_CD764_MY2022_Rx" SG_ 1034 VehicleGGCCData 1;
BA_ "U_P702_MY2021_Rx" SG_ 1034 VehicleGGCCData 1;
BA_ "U_U55X_MY2022_Rx" SG_ 1034 VehicleGGCCData 1;
BA_ "U_CD542_MY2021_Rx" SG_ 1034 VehicleGGCCData 1;
BA_ "U_T6_MCA_MY2020_Rx" SG_ 1034 VehicleGGCCData 1;
BA_ "U_CX727_MY2021_Rx" SG_ 1034 VehicleGGCCData 1;
BA_ "U_CD764_MY2022_Rx" SG_ 956 PwSrcULoFalt_D_Stat_UB 1;
BA_ "U_U55X_MY2022_Rx" SG_ 956 PwSrcULoFalt_D_Stat_UB 1;
BA_ "U_CD542_MY2021_Rx" SG_ 956 PwSrcULoFalt_D_Stat_UB 1;
BA_ "U_T6_MCA_MY2020_Rx" SG_ 956 PwSrcULoFalt_D_Stat_UB 1;
BA_ "U_P702_MY2021_Rx" SG_ 956 PwSrcULoFalt_D_Stat_UB 1;
BA_ "U_CX727_MY2021_Rx" SG_ 956 PwSrcULoFalt_D_Stat_UB 1;
BA_ "U_CD764_MY2022_Rx" SG_ 956 PwSrcULo_Pc_Mx_UB 1;
BA_ "U_U55X_MY2022_Rx" SG_ 956 PwSrcULo_Pc_Mx_UB 1;
BA_ "U_CD542_MY2021_Rx" SG_ 956 PwSrcULo_Pc_Mx_UB 1;
BA_ "U_T6_MCA_MY2020_Rx" SG_ 956 PwSrcULo_Pc_Mx_UB 1;
BA_ "U_P702_MY2021_Rx" SG_ 956 PwSrcULo_Pc_Mx_UB 1;
BA_ "U_CX727_MY2021_Rx" SG_ 956 PwSrcULo_Pc_Mx_UB 1;
BA_ "U_CD764_MY2022_Rx" SG_ 956 PwSrcULo_Pc_Mx 1;
BA_ "U_U55X_MY2022_Rx" SG_ 956 PwSrcULo_Pc_Mx 1;
BA_ "U_CD542_MY2021_Rx" SG_ 956 PwSrcULo_Pc_Mx 1;
BA_ "U_T6_MCA_MY2020_Rx" SG_ 956 PwSrcULo_Pc_Mx 1;
BA_ "U_P702_MY2021_Rx" SG_ 956 PwSrcULo_Pc_Mx 1;
BA_ "U_CX727_MY2021_Rx" SG_ 956 PwSrcULo_Pc_Mx 1;
BA_ "U_CD764_MY2022_Rx" SG_ 956 WndwFrontHeat_B_Rq_UB 1;
BA_ "U_U55X_MY2022_Rx" SG_ 956 WndwFrontHeat_B_Rq_UB 1;
BA_ "U_CD542_MY2021_Rx" SG_ 956 WndwFrontHeat_B_Rq_UB 1;
BA_ "U_CX727_MY2021_Rx" SG_ 956 WndwFrontHeat_B_Rq_UB 1;
BA_ "U_CD764_MY2022_Rx" SG_ 956 WndwFrontHeat_B_Rq 1;
BA_ "U_U55X_MY2022_Rx" SG_ 956 WndwFrontHeat_B_Rq 1;
BA_ "U_CD542_MY2021_Rx" SG_ 956 WndwFrontHeat_B_Rq 1;
BA_ "U_CX727_MY2021_Rx" SG_ 956 WndwFrontHeat_B_Rq 1;
BA_ "U_CD764_MY2022_Rx" SG_ 956 BattTrac_Te_Actl_UB 1;
BA_ "U_U55X_MY2022_Rx" SG_ 956 BattTrac_Te_Actl_UB 1;
BA_ "U_CD542_MY2021_Rx" SG_ 956 BattTrac_Te_Actl_UB 1;
BA_ "U_T6_MCA_MY2020_Rx" SG_ 956 BattTrac_Te_Actl_UB 1;
BA_ "U_CX727_MY2021_Rx" SG_ 956 BattTrac_Te_Actl_UB 1;
BA_ "U_CD764_MY2022_Rx" SG_ 956 BattTrac_Te_Actl 1;
BA_ "U_U55X_MY2022_Rx" SG_ 956 BattTrac_Te_Actl 1;
BA_ "U_CD542_MY2021_Rx" SG_ 956 BattTrac_Te_Actl 1;
BA_ "U_T6_MCA_MY2020_Rx" SG_ 956 BattTrac_Te_Actl 1;
BA_ "U_CX727_MY2021_Rx" SG_ 956 BattTrac_Te_Actl 1;
BA_ "GenSigStartValue" SG_ 956 BattTrac_Te_Actl 150;
BA_ "GenSigStartValueInteger" SG_ 956 BattTrac_Te_Actl 150;
BA_ "U_CD764_MY2022_Rx" SG_ 956 PwSrcULoFalt_D_Stat 1;
BA_ "U_U55X_MY2022_Rx" SG_ 956 PwSrcULoFalt_D_Stat 1;
BA_ "U_CD542_MY2021_Rx" SG_ 956 PwSrcULoFalt_D_Stat 1;
BA_ "U_T6_MCA_MY2020_Rx" SG_ 956 PwSrcULoFalt_D_Stat 1;
BA_ "U_P702_MY2021_Rx" SG_ 956 PwSrcULoFalt_D_Stat 1;
BA_ "U_CX727_MY2021_Rx" SG_ 956 PwSrcULoFalt_D_Stat 1;
BA_ "U_CD764_MY2022_Rx" SG_ 956 PrkBrkStatus 1;
BA_ "U_U55X_MY2022_Rx" SG_ 956 PrkBrkStatus 1;
BA_ "U_CD542_MY2021_Rx" SG_ 956 PrkBrkStatus 1;
BA_ "U_T6_MCA_MY2020_Rx" SG_ 956 PrkBrkStatus 1;
BA_ "U_CX727_MY2021_Rx" SG_ 956 PrkBrkStatus 1;
BA_ "GenSigStartValue" SG_ 956 PrkBrkStatus 7;
BA_ "GenSigStartValueInteger" SG_ 956 PrkBrkStatus 7;
BA_ "U_CD764_MY2022_Rx" SG_ 956 GearLvrPos_D_Actl_UB 1;
BA_ "U_U55X_MY2022_Rx" SG_ 956 GearLvrPos_D_Actl_UB 1;
BA_ "U_CD542_MY2021_Rx" SG_ 956 GearLvrPos_D_Actl_UB 1;
BA_ "U_T6_MCA_MY2020_Rx" SG_ 956 GearLvrPos_D_Actl_UB 1;
BA_ "U_P702_MY2021_Rx" SG_ 956 GearLvrPos_D_Actl_UB 1;
BA_ "U_CX727_MY2021_Rx" SG_ 956 GearLvrPos_D_Actl_UB 1;
BA_ "U_CD764_MY2022_Rx" SG_ 956 PrkBrkStatus_UB 1;
BA_ "U_U55X_MY2022_Rx" SG_ 956 PrkBrkStatus_UB 1;
BA_ "U_CD542_MY2021_Rx" SG_ 956 PrkBrkStatus_UB 1;
BA_ "U_T6_MCA_MY2020_Rx" SG_ 956 PrkBrkStatus_UB 1;
BA_ "U_CX727_MY2021_Rx" SG_ 956 PrkBrkStatus_UB 1;
BA_ "U_CD764_MY2022_Rx" SG_ 956 ApedPos_Pc_ActlArb 1;
BA_ "U_U55X_MY2022_Rx" SG_ 956 ApedPos_Pc_ActlArb 1;
BA_ "U_CD542_MY2021_Rx" SG_ 956 ApedPos_Pc_ActlArb 1;
BA_ "U_T6_MCA_MY2020_Rx" SG_ 956 ApedPos_Pc_ActlArb 1;
BA_ "U_P702_MY2021_Rx" SG_ 956 ApedPos_Pc_ActlArb 1;
BA_ "U_CX727_MY2021_Rx" SG_ 956 ApedPos_Pc_ActlArb 1;
BA_ "U_CD764_MY2022_Rx" SG_ 956 ApedPos_Pc_ActlArb_UB 1;
BA_ "U_U55X_MY2022_Rx" SG_ 956 ApedPos_Pc_ActlArb_UB 1;
BA_ "U_CD542_MY2021_Rx" SG_ 956 ApedPos_Pc_ActlArb_UB 1;
BA_ "U_T6_MCA_MY2020_Rx" SG_ 956 ApedPos_Pc_ActlArb_UB 1;
BA_ "U_P702_MY2021_Rx" SG_ 956 ApedPos_Pc_ActlArb_UB 1;
BA_ "U_CX727_MY2021_Rx" SG_ 956 ApedPos_Pc_ActlArb_UB 1;
BA_ "U_CD764_MY2022_Rx" SG_ 956 GearLvrPos_D_Actl 1;
BA_ "U_U55X_MY2022_Rx" SG_ 956 GearLvrPos_D_Actl 1;
BA_ "U_CD542_MY2021_Rx" SG_ 956 GearLvrPos_D_Actl 1;
BA_ "U_T6_MCA_MY2020_Rx" SG_ 956 GearLvrPos_D_Actl 1;
BA_ "U_P702_MY2021_Rx" SG_ 956 GearLvrPos_D_Actl 1;
BA_ "U_CX727_MY2021_Rx" SG_ 956 GearLvrPos_D_Actl 1;
BA_ "GenSigStartValue" SG_ 956 GearLvrPos_D_Actl 14;
BA_ "GenSigStartValueInteger" SG_ 956 GearLvrPos_D_Actl 14;
BA_ "U_CD764_MY2022_Tx" SG_ 831 MirrorTelescopic_D_Rq 1;
BA_ "U_T6_MCA_MY2020_Tx" SG_ 831 MirrorTelescopic_D_Rq 1;
BA_ "U_T6_MCA_MY2020_Rx" SG_ 831 MirrorTelescopic_D_Rq 1;
BA_ "GenSigSendType" SG_ 831 MirrorTelescopic_D_Rq 3;
BA_ "U_CD764_MY2022_Tx" SG_ 831 RearPassWindowLockCmd 1;
BA_ "U_U55X_MY2022_Tx" SG_ 831 RearPassWindowLockCmd 1;
BA_ "U_CD542_MY2021_Tx" SG_ 831 RearPassWindowLockCmd 1;
BA_ "U_T6_MCA_MY2020_Tx" SG_ 831 RearPassWindowLockCmd 1;
BA_ "U_P702_MY2021_Tx" SG_ 831 RearPassWindowLockCmd 1;
BA_ "U_CX727_MY2021_Tx" SG_ 831 RearPassWindowLockCmd 1;
BA_ "U_CD764_MY2022_Rx" SG_ 831 RearPassWindowLockCmd 1;
BA_ "U_U55X_MY2022_Rx" SG_ 831 RearPassWindowLockCmd 1;
BA_ "U_CD542_MY2021_Rx" SG_ 831 RearPassWindowLockCmd 1;
BA_ "U_T6_MCA_MY2020_Rx" SG_ 831 RearPassWindowLockCmd 1;
BA_ "U_P702_MY2021_Rx" SG_ 831 RearPassWindowLockCmd 1;
BA_ "GenSigSendType" SG_ 831 RearPassWindowLockCmd 3;
BA_ "U_CD764_MY2022_Tx" SG_ 831 RearPassWindowCmd 1;
BA_ "U_U55X_MY2022_Tx" SG_ 831 RearPassWindowCmd 1;
BA_ "U_CD542_MY2021_Tx" SG_ 831 RearPassWindowCmd 1;
BA_ "U_T6_MCA_MY2020_Tx" SG_ 831 RearPassWindowCmd 1;
BA_ "U_P702_MY2021_Tx" SG_ 831 RearPassWindowCmd 1;
BA_ "U_CX727_MY2021_Tx" SG_ 831 RearPassWindowCmd 1;
BA_ "U_CD764_MY2022_Rx" SG_ 831 RearPassWindowCmd 1;
BA_ "U_U55X_MY2022_Rx" SG_ 831 RearPassWindowCmd 1;
BA_ "U_CD542_MY2021_Rx" SG_ 831 RearPassWindowCmd 1;
BA_ "U_T6_MCA_MY2020_Rx" SG_ 831 RearPassWindowCmd 1;
BA_ "U_P702_MY2021_Rx" SG_ 831 RearPassWindowCmd 1;
BA_ "GenSigSendType" SG_ 831 RearPassWindowCmd 3;
BA_ "WakeupSignal" SG_ 831 RearPassWindowCmd 1;
BA_ "U_CD764_MY2022_Tx" SG_ 831 PassWindowCmd 1;
BA_ "U_U55X_MY2022_Tx" SG_ 831 PassWindowCmd 1;
BA_ "U_CD542_MY2021_Tx" SG_ 831 PassWindowCmd 1;
BA_ "U_T6_MCA_MY2020_Tx" SG_ 831 PassWindowCmd 1;
BA_ "U_P702_MY2021_Tx" SG_ 831 PassWindowCmd 1;
BA_ "U_CX727_MY2021_Tx" SG_ 831 PassWindowCmd 1;
BA_ "U_CD764_MY2022_Rx" SG_ 831 PassWindowCmd 1;
BA_ "U_U55X_MY2022_Rx" SG_ 831 PassWindowCmd 1;
BA_ "U_CD542_MY2021_Rx" SG_ 831 PassWindowCmd 1;
BA_ "U_T6_MCA_MY2020_Rx" SG_ 831 PassWindowCmd 1;
BA_ "U_P702_MY2021_Rx" SG_ 831 PassWindowCmd 1;
BA_ "GenSigSendType" SG_ 831 PassWindowCmd 3;
BA_ "WakeupSignal" SG_ 831 PassWindowCmd 1;
BA_ "U_CD764_MY2022_Tx" SG_ 831 PassMirrorCmd 1;
BA_ "U_U55X_MY2022_Tx" SG_ 831 PassMirrorCmd 1;
BA_ "U_CD542_MY2021_Tx" SG_ 831 PassMirrorCmd 1;
BA_ "U_T6_MCA_MY2020_Tx" SG_ 831 PassMirrorCmd 1;
BA_ "U_P702_MY2021_Tx" SG_ 831 PassMirrorCmd 1;
BA_ "U_CX727_MY2021_Tx" SG_ 831 PassMirrorCmd 1;
BA_ "U_CD764_MY2022_Rx" SG_ 831 PassMirrorCmd 1;
BA_ "U_U55X_MY2022_Rx" SG_ 831 PassMirrorCmd 1;
BA_ "U_CD542_MY2021_Rx" SG_ 831 PassMirrorCmd 1;
BA_ "U_T6_MCA_MY2020_Rx" SG_ 831 PassMirrorCmd 1;
BA_ "U_P702_MY2021_Rx" SG_ 831 PassMirrorCmd 1;
BA_ "GenSigSendType" SG_ 831 PassMirrorCmd 3;
BA_ "WakeupSignal" SG_ 831 PassMirrorCmd 1;
BA_ "U_CD764_MY2022_Tx" SG_ 831 DipMirrorPosPassenger 1;
BA_ "U_U55X_MY2022_Tx" SG_ 831 DipMirrorPosPassenger 1;
BA_ "U_CD542_MY2021_Tx" SG_ 831 DipMirrorPosPassenger 1;
BA_ "U_T6_MCA_MY2020_Tx" SG_ 831 DipMirrorPosPassenger 1;
BA_ "U_P702_MY2021_Tx" SG_ 831 DipMirrorPosPassenger 1;
BA_ "U_CX727_MY2021_Tx" SG_ 831 DipMirrorPosPassenger 1;
BA_ "U_CD764_MY2022_Rx" SG_ 831 DipMirrorPosPassenger 1;
BA_ "U_CD542_MY2021_Rx" SG_ 831 DipMirrorPosPassenger 1;
BA_ "U_T6_MCA_MY2020_Rx" SG_ 831 DipMirrorPosPassenger 1;
BA_ "U_P702_MY2021_Rx" SG_ 831 DipMirrorPosPassenger 1;
BA_ "GenSigSendType" SG_ 831 DipMirrorPosPassenger 3;
BA_ "U_CD764_MY2022_Tx" SG_ 831 ActiveStoragePassenger 1;
BA_ "U_U55X_MY2022_Tx" SG_ 831 ActiveStoragePassenger 1;
BA_ "U_CD542_MY2021_Tx" SG_ 831 ActiveStoragePassenger 1;
BA_ "U_T6_MCA_MY2020_Tx" SG_ 831 ActiveStoragePassenger 1;
BA_ "U_P702_MY2021_Tx" SG_ 831 ActiveStoragePassenger 1;
BA_ "U_CX727_MY2021_Tx" SG_ 831 ActiveStoragePassenger 1;
BA_ "U_CD764_MY2022_Rx" SG_ 831 ActiveStoragePassenger 1;
BA_ "U_CD542_MY2021_Rx" SG_ 831 ActiveStoragePassenger 1;
BA_ "U_T6_MCA_MY2020_Rx" SG_ 831 ActiveStoragePassenger 1;
BA_ "U_P702_MY2021_Rx" SG_ 831 ActiveStoragePassenger 1;
BA_ "GenSigSendType" SG_ 831 ActiveStoragePassenger 3;
BA_ "U_CD764_MY2022_Tx" SG_ 831 RearDriverWindowPos 1;
BA_ "U_U55X_MY2022_Tx" SG_ 831 RearDriverWindowPos 1;
BA_ "U_CD542_MY2021_Tx" SG_ 831 RearDriverWindowPos 1;
BA_ "U_T6_MCA_MY2020_Tx" SG_ 831 RearDriverWindowPos 1;
BA_ "U_P702_MY2021_Tx" SG_ 831 RearDriverWindowPos 1;
BA_ "U_CX727_MY2021_Tx" SG_ 831 RearDriverWindowPos 1;
BA_ "ECGUsedRxSignal" SG_ 831 RearDriverWindowPos 1;
BA_ "U_CD764_MY2022_Rx" SG_ 831 RearDriverWindowPos 1;
BA_ "U_U55X_MY2022_Rx" SG_ 831 RearDriverWindowPos 1;
BA_ "U_CD542_MY2021_Rx" SG_ 831 RearDriverWindowPos 1;
BA_ "U_T6_MCA_MY2020_Rx" SG_ 831 RearDriverWindowPos 1;
BA_ "U_P702_MY2021_Rx" SG_ 831 RearDriverWindowPos 1;
BA_ "U_CX727_MY2021_Rx" SG_ 831 RearDriverWindowPos 1;
BA_ "GenSigSendType" SG_ 831 RearDriverWindowPos 3;
BA_ "WakeupSignal" SG_ 831 RearDriverWindowPos 1;
BA_ "U_CD764_MY2022_Tx" SG_ 831 DriverWindowPosition 1;
BA_ "U_U55X_MY2022_Tx" SG_ 831 DriverWindowPosition 1;
BA_ "U_CD542_MY2021_Tx" SG_ 831 DriverWindowPosition 1;
BA_ "U_T6_MCA_MY2020_Tx" SG_ 831 DriverWindowPosition 1;
BA_ "U_P702_MY2021_Tx" SG_ 831 DriverWindowPosition 1;
BA_ "U_CX727_MY2021_Tx" SG_ 831 DriverWindowPosition 1;
BA_ "ECGUsedRxSignal" SG_ 831 DriverWindowPosition 1;
BA_ "U_CD764_MY2022_Rx" SG_ 831 DriverWindowPosition 1;
BA_ "U_U55X_MY2022_Rx" SG_ 831 DriverWindowPosition 1;
BA_ "U_CD542_MY2021_Rx" SG_ 831 DriverWindowPosition 1;
BA_ "U_T6_MCA_MY2020_Rx" SG_ 831 DriverWindowPosition 1;
BA_ "U_P702_MY2021_Rx" SG_ 831 DriverWindowPosition 1;
BA_ "U_CX727_MY2021_Rx" SG_ 831 DriverWindowPosition 1;
BA_ "GenSigSendType" SG_ 831 DriverWindowPosition 3;
BA_ "WakeupSignal" SG_ 831 DriverWindowPosition 1;
BA_ "U_U55X_MY2022_Tx" SG_ 787 DrLckCnt_No_ActlTgate 1;
BA_ "U_CD542_MY2021_Tx" SG_ 787 DrLckCnt_No_ActlTgate 1;
BA_ "U_T6_MCA_MY2020_Tx" SG_ 787 DrLckCnt_No_ActlTgate 1;
BA_ "U_CX727_MY2021_Tx" SG_ 787 DrLckCnt_No_ActlTgate 1;
BA_ "WakeupSignal" SG_ 787 DrLckCnt_No_ActlTgate 1;
BA_ "U_U55X_MY2022_Tx" SG_ 787 DrTgateChime2_D_Rq 1;
BA_ "U_CD542_MY2021_Tx" SG_ 787 DrTgateChime2_D_Rq 1;
BA_ "U_T6_MCA_MY2020_Tx" SG_ 787 DrTgateChime2_D_Rq 1;
BA_ "U_CX727_MY2021_Tx" SG_ 787 DrTgateChime2_D_Rq 1;
BA_ "GenSigSendType" SG_ 787 DrTgateChime2_D_Rq 3;
BA_ "WakeupSignal" SG_ 787 DrTgateChime2_D_Rq 1;
BA_ "U_U55X_MY2022_Tx" SG_ 787 DrTGate_D_Rq 1;
BA_ "U_CD542_MY2021_Tx" SG_ 787 DrTGate_D_Rq 1;
BA_ "U_T6_MCA_MY2020_Tx" SG_ 787 DrTGate_D_Rq 1;
BA_ "U_CX727_MY2021_Tx" SG_ 787 DrTGate_D_Rq 1;
BA_ "U_CD764_MY2022_Rx" SG_ 787 DrTGate_D_Rq 1;
BA_ "U_U55X_MY2022_Rx" SG_ 787 DrTGate_D_Rq 1;
BA_ "U_CD542_MY2021_Rx" SG_ 787 DrTGate_D_Rq 1;
BA_ "U_T6_MCA_MY2020_Rx" SG_ 787 DrTGate_D_Rq 1;
BA_ "U_CX727_MY2021_Rx" SG_ 787 DrTGate_D_Rq 1;
BA_ "GenSigSendType" SG_ 787 DrTGate_D_Rq 3;
BA_ "WakeupSignal" SG_ 787 DrTGate_D_Rq 1;
BA_ "U_U55X_MY2022_Tx" SG_ 787 PwLftgtIntSw_B_Stat 1;
BA_ "U_CD542_MY2021_Tx" SG_ 787 PwLftgtIntSw_B_Stat 1;
BA_ "U_T6_MCA_MY2020_Tx" SG_ 787 PwLftgtIntSw_B_Stat 1;
BA_ "U_CX727_MY2021_Tx" SG_ 787 PwLftgtIntSw_B_Stat 1;
BA_ "GenSigSendType" SG_ 787 PwLftgtIntSw_B_Stat 3;
BA_ "WakeupSignal" SG_ 787 PwLftgtIntSw_B_Stat 1;
BA_ "U_U55X_MY2022_Tx" SG_ 787 Power_Liftgate_Mode_Stt 1;
BA_ "U_CD542_MY2021_Tx" SG_ 787 Power_Liftgate_Mode_Stt 1;
BA_ "U_T6_MCA_MY2020_Tx" SG_ 787 Power_Liftgate_Mode_Stt 1;
BA_ "U_CX727_MY2021_Tx" SG_ 787 Power_Liftgate_Mode_Stt 1;
BA_ "GenSigSendType" SG_ 787 Power_Liftgate_Mode_Stt 3;
VAL_ 376 GasPrtc_D_RqDsply 7 "NotUsed_5" 6 "NotUsed_4" 5 "NotUsed_3" 4 "NotUsed_2" 3 "NotUsed_1" 2 "GpfOverLimit" 1 "GpfAtLimit" 0 "NormalOperation" ;
VAL_ 376 AslIconDsply_D_Rq 3 "On_Passive_Overridden" 2 "On_Active" 1 "On_Passive" 0 "Off" ;
VAL_ 376 AslChime_B_Rq 1 "Yes" 0 "No" ;
VAL_ 376 PtcHtr_D_Cmd 3 "TurnOn" 2 "AutoMode" 1 "TurnOff" 0 "NoDecision_Initializing" ;
VAL_ 376 HvacHtrCore2_Te_Actl 1023 "Faulty" ;
VAL_ 376 LnchCtlSys_D_Stat 7 "NotUsed3" 6 "NotUsed2" 5 "NotUsed1" 4 "On_LC_Unavailable_TC_On" 3 "On_LC_Unavailable" 2 "On_LC_Available" 1 "On_LC_Active" 0 "LC_OFF" ;
VAL_ 376 EcssLamp_D_RqDsply 3 "Not_Used" 2 "Flash" 1 "On" 0 "Off" ;
VAL_ 376 AirAmbTe_D_Qf 3 "OK" 2 "Not_Within_Specifications" 1 "No_Data_Exists" 0 "Faulty" ;
VAL_ 376 DynoMde_B_Cmd 1 "DynomometerMode" 0 "NormalOperation" ;
VAL_ 376 AirAmb_P_Actl 63 "Fault" 62 "NoDataExists" ;
VAL_ 1068 HvacAirFullOut_B_Rq_UB 1 "Fresh_data" 0 "Unchanged_data" ;
VAL_ 1068 HvacAirFullOut_B_Rq 1 "Yes" 0 "No" ;
VAL_ 1068 HvacCmprLim_D_Stat_UB 1 "Fresh_data" 0 "Unchanged_data" ;
VAL_ 1068 HvacCmprLim_D_Stat 7 "NotUsed_2" 6 "NotUsed_1" 5 "CompressorHeadPressure" 4 "AvailableTorque" 3 "PedalPosition" 2 "RPM" 1 "ECT" 0 "NoLimit" ;
VAL_ 1068 HvacAirFlw_B_RqBatt_UB 1 "Fresh_data" 0 "Unchanged_data" ;
VAL_ 1068 HvacAirFlw_B_RqBatt 1 "Request" 0 "NoRequest" ;
VAL_ 1068 HvacRec_D_RqMxBatt_UB 1 "Fresh_data" 0 "Unchanged_data" ;
VAL_ 1068 HvacRec_D_RqMxBatt 15 "NotUsed5" 14 "NotUsed4" 13 "NotUsed3" 12 "NotUsed2" 11 "NotUsed1" 10 "No_Override" 9 "90Percent_RecircMax" 8 "80Percent_RecircMax" 7 "70Percent_RecircMax" 6 "60Percent_RecircMax" 5 "50Percent_RecircMax" 4 "40Percent_RecircMax" 3 "30Percent_RecircMax" 2 "20Percent_RecircMax" 1 "10Percent_RecircMax" 0 "0Percent_RecircFullOpen" ;
VAL_ 1068 Batt_Lo_SoC_B_UB 1 "Fresh_data" 0 "Unchanged_data" ;
VAL_ 1068 Batt_Lo_SoC_B 1 "Active" 0 "Inactive" ;
VAL_ 1068 Batt_Crit_SoC_B_UB 1 "Fresh_data" 0 "Unchanged_data" ;
VAL_ 1068 Batt_Crit_SoC_B 1 "Active" 0 "Inactive" ;
VAL_ 1068 Shed_T_Eng_Off_B_UB 1 "Fresh_data" 0 "Unchanged_data" ;
VAL_ 1068 Shed_T_Eng_Off_B 1 "Active" 0 "Inactive" ;
VAL_ 1068 Shed_Level_Req_UB 1 "Fresh_data" 0 "Unchanged_data" ;
VAL_ 1068 Shed_Level_Req 7 "SHED3" 6 "Loads_On" 5 "SHED_ENG_OFF" 4 "SOON_ENG_OFF" 3 "SHED2_CONTIN" 2 "SHED2_TRANS" 1 "SHED1" 0 "NO_SHED" ;
VAL_ 1068 Shed_Feature_Group_ID_UB 1 "Fresh_data" 0 "Unchanged_data" ;
VAL_ 1068 Shed_Feature_Group_ID 16 "PtcHeater" 30 "NotUsed_7" 29 "NotUsed_6" 28 "NotUsed_5" 27 "NotUsed_4" 26 "NotUsed_3" 25 "NotUsed_2" 24 "NotUsed_1" 23 "Dcac" 22 "UpFitter_6" 21 "UpFitter_5" 20 "UpFitter_4" 19 "UpFitter_3" 18 "UpFitter_2" 17 "UpFitter_1" 14 "HtdMirr" 13 "HvacRearBlwr_Third" 12 "HvacRearBlwr_Second" 11 "HvacRearBlwr_First" 31 "All LSHED1 Features" 10 "Htd_Windscrn" 9 "SpltHtdBcklight_HtdMirr" 8 "HtdBcklight_HtdMirr" 7 "HtdCoolSeat_FrtDriver" 6 "HtdCoolSeat_FrtPass" 5 "HtdCoolSeat_RearPass" 4 "HtdCoolSeat_RearDriver" 3 "SmartTrlrTowBattCharge" 2 "Htd_StrWhl" 1 "Htd_Washer_Fluid" 0 "No_LSHED1_Features" 15 "Engine_Coolant_Fan" ;
VAL_ 1068 Shed_Drain_Eng_Off_B_UB 1 "Fresh_data" 0 "Unchanged_data" ;
VAL_ 1068 Shed_Drain_Eng_Off_B 1 "Active" 0 "Inactive" ;
VAL_ 1068 HvacAir_Flw_EstBatt_UB 1 "Fresh_data" 0 "Unchanged_data" ;
VAL_ 1068 HvacAir_Flw_EstBatt 255 "Invalid" ;
VAL_ 1068 AirCondRec_B_Rq_UB 1 "Fresh_data" 0 "Unchanged_data" ;
VAL_ 1068 AirCondFluidHi_P_Actl_UB 1 "Fresh_data" 0 "Unchanged_data" ;
VAL_ 1068 AirCondClutch_B_Stats_UB 1 "Fresh_data" 0 "Unchanged_data" ;
VAL_ 1068 AirCondRec_B_Rq 1 "Yes" 0 "No" ;
VAL_ 1068 AirCondFluidHi_P_Actl 255 "Fault" 254 "Unknown" ;
VAL_ 1068 AirCondClutch_B_Stats 1 "Yes" 0 "No" ;
VAL_ 963 Illuminated_Entry_Stat 3 "Invalid" 2 "Unknown" 1 "On" 0 "Off" ;
VAL_ 963 Dr_Courtesy_Light_Stat 3 "Invalid" 2 "Unknown" 1 "On" 0 "Off" ;
VAL_ 963 ImpactEvntFdbck_D_Stat 3 "NotUsed" 2 "EventComplete" 1 "EventInProgress" 0 "Normal" ;
VAL_ 963 DrTgateLck_D_Stat 3 "NotUsed" 2 "Unlock" 1 "Lock" 0 "Null" ;
VAL_ 963 PudLampPsngr_D_Rq 3 "Ramp_Down" 2 "Ramp_Up" 1 "On" 0 "Off" ;
VAL_ 963 HeadLampLoOut_B_Stat 1 "Out" 0 "Null" ;
VAL_ 963 HeadLghtHiFdbck_D_Stat 3 "NotUsed" 2 "Cancel" 1 "Hold" 0 "Allow_Change" ;
VAL_ 963 PrkLightChime_B_Rq 1 "On" 0 "Off" ;
VAL_ 963 TrnNotInPrkChime_B_Rq 1 "On" 0 "Off" ;
VAL_ 963 HomeSafeLtChime_B_Rq 1 "On" 0 "Off" ;
VAL_ 963 StopLghtOn_B_Stat 1 "On" 0 "Off" ;
VAL_ 963 RvrseLghtOn_B_Stat 1 "On" 0 "Off" ;
VAL_ 963 PrkLght_D_Stat 3 "Park_Both" 2 "Park_Right" 1 "Park_Left" 0 "Off" ;
VAL_ 963 HeadLghtSwtch_D_Stat 3 "Autolamp" 2 "Headlamp" 1 "Parklamp" 0 "Off" ;
VAL_ 963 KeyInIgnWarn_B_Cmd 1 "On" 0 "Off" ;
VAL_ 963 HeadLampLoFrOn_B_Stat 1 "Low" 0 "Not_Low" ;
VAL_ 963 HeadLampLoFlOn_B_Stat 1 "Low" 0 "Not_Low" ;
VAL_ 963 Headlamp_On_Wrning_Cmd 1 "On" 0 "Off" ;
VAL_ 963 HeadLampLoActv_B_Stat 1 "On" 0 "Off" ;
VAL_ 963 HeadLghtHiOn_B_Stat 1 "On" 0 "Off" ;
VAL_ 963 Park_Brake_Chime_Rqst 1 "On" 0 "Off" ;
VAL_ 963 BrkWarnInd_B_Rq 1 "On" 0 "Off" ;
VAL_ 963 Brk_Fluid_Lvl_Low 3 "Invalid" 2 "Unknown" 1 "Low" 0 "OK" ;
VAL_ 963 ReducedGuard_D_Stat 3 "NotUsed" 2 "Alarm_On" 1 "Alarm_Off_Previously_On" 0 "Alarm_Off" ;
VAL_ 963 Courtesy_BSave_Stat 3 "Invalid" 2 "Unknown" 1 "No_Effect" 0 "Off" ;
VAL_ 963 DayRnngLampOn_B_Stat 1 "On" 0 "Off" ;
VAL_ 963 PerimeterAlarmChimeRq 1 "On" 0 "Off" ;
VAL_ 963 PudLampDrv_D_Rq 3 "Ramp_Down" 2 "Ramp_Up" 1 "On" 0 "Off" ;
VAL_ 963 Courtesy_Delay_Status 3 "Invalid" 2 "Unknown" 1 "On" 0 "Off" ;
VAL_ 963 Perimeter_Alarm_Status 3 "Activated" 2 "Armed" 1 "Prearmed" 0 "Disarmed" ;
VAL_ 963 WndwGlbl_D_Cmd 7 "NotUsed3" 6 "NotUsed2" 5 "NotUsed1" 4 "GLEARN" 3 "GCLOSE" 2 "GOPEN" 1 "GSTOP" 0 "Null" ;
VAL_ 963 PudLamp_D_Rq 3 "RAMP_DOWN" 2 "RAMP_UP" 1 "ON" 0 "OFF" ;
VAL_ 964 FohEng_D_Rq_UB 1 "Fresh_data" 0 "Unchanged_data" ;
VAL_ 964 FohEng_D_Rq 3 "AutoEnable_ParkEnable" 2 "AutoDisable_ParkEnable" 1 "AutoEnable_ParkDisable" 0 "Disable_Stop" ;
VAL_ 964 EcoMode_B_Stat_UB 1 "Fresh_data" 0 "Unchanged_data" ;
VAL_ 964 Cta_D_Rq_UB 1 "Fresh_data" 0 "Unchanged_data" ;
VAL_ 964 Cta_D_Rq 3 "Unused" 2 "NoDataExists" 1 "On" 0 "Off" ;
VAL_ 964 GearRvrse_D_Actl_UB 1 "Fresh_data" 0 "Unchanged_data" ;
VAL_ 964 GearRvrse_D_Actl 7 "Fault" 6 "NotUsed_3" 5 "NotUsed_2" 4 "NotUsed_1" 3 "Active_confirmed" 2 "Active_not_confirmed" 1 "Inactive_confirmed" 0 "Inactive_not_confirmed" ;
VAL_ 964 TurnLghtSwtch_D_Stat_UB 1 "Fresh_data" 0 "Unchanged_data" ;
VAL_ 964 TurnLghtSwtch_D_Stat 3 "Unused_Treat_As_Off" 2 "Right" 1 "Left" 0 "Off" ;
VAL_ 964 Power_Liftgate_Mode_Cmd_UB 1 "Fresh_data" 0 "Unchanged_data" ;
VAL_ 964 Power_Liftgate_Mode_Cmd 1 "Enable" 0 "Disable" ;
VAL_ 964 EcoMode_B_Stat 1 "On" 0 "Off" ;
VAL_ 964 MetricActvTe_B_Actl_UB 1 "Fresh_data" 0 "Unchanged_data" ;
VAL_ 964 MetricActvTe_B_Actl 1 "Active" 0 "Inactive" ;
VAL_ 964 EngClntTe_D_Qf 3 "OK" 2 "Not_Within_Specifications" 1 "No_Data_Exists" 0 "Faulty" ;
VAL_ 964 Sod_D_Rq 2 "BLIS_On_Second_Warning_ON" 1 "BLIS_On_Second_Warning_OFF" 0 "Off" ;
VAL_ 964 MetricActv_B_Actl 1 "Active" 0 "Inactive" ;
VAL_ 964 MetricActv_B_Actl_UB 1 "Fresh_data" 0 "Unchanged_data" ;
VAL_ 964 EngClnt_Te_Actl_UB 1 "Fresh_data" 0 "Unchanged_data" ;
VAL_ 964 OCSSensrDataUpperLim_UB 1 "Fresh_data" 0 "Unchanged_data" ;
VAL_ 964 OCSSensrDataUpperLim 255 "Invalid" ;
VAL_ 964 OCSSensrDataLowerLim_UB 1 "Fresh_data" 0 "Unchanged_data" ;
VAL_ 964 PrkAid_D_Falt 7 "NotUsed2" 6 "NotUsed1" 5 "Failure_Front_PSM_Sensors" 4 "No_Data_Exists" 3 "Failure_Rear_Sensors" 2 "Speaker_Fault" 1 "ECU_Fault" 0 "No_Fault" ;
VAL_ 964 OCSSensrDataLowerLim 255 "Invalid" ;
VAL_ 964 PrkAid_D_Falt_UB 1 "Fresh_data" 0 "Unchanged_data" ;
VAL_ 964 WiprFront_D_Stat_UB 1 "Fresh_data" 0 "Unchanged_data" ;
VAL_ 964 WiprFront_D_Stat 15 "NO_DATA_EXISTS" 14 "STALLED" 13 "RESERVED" 12 "AUTO_ADJUST" 11 "COURTESYWIPE" 10 "AUTO_HIGH" 9 "AUTO_LOW" 8 "WASH" 7 "MIST_FLICK" 6 "MAN_HIGH" 5 "MAN_LOW" 4 "MAN_INT_ON" 3 "MAN_INT_OFF" 2 "OFF_MOVING" 1 "AUTO_OFF" 0 "OFF" ;
VAL_ 964 CamraDefog_B_Req_UB 1 "Fresh_data" 0 "Unchanged_data" ;
VAL_ 964 Sod_D_Rq_UB 1 "Fresh_data" 0 "Unchanged_data" ;
VAL_ 964 CamraDefog_B_Req 1 "On" 0 "Off" ;
VAL_ 993 EmButtn_D_Stat 7 "ButtonAssociationFailed" 6 "ButtonAssociationExited" 5 "ButtonAssociationEntered" 4 "Button4Pressed" 3 "Button3Pressed" 2 "Button2Pressed" 1 "Button1Pressed" 0 "Null" ;
VAL_ 993 MemStoreMsgTxt_D_Rq 10 "NotUsed_2" 9 "NotUsed_1" 8 "Mem4Saved_ShowLinkMsg" 7 "Mem3Saved_ShowLinkMsg" 6 "Mem2Saved_ShowLinkMsg" 5 "Mem1Saved_ShowLinkMsg" 4 "Mem4Saved_DoNotShowLinkMsg" 3 "Mem3Saved_DoNotShowLinkMsg" 2 "Mem2Saved_DoNotShowLinkMsg" 1 "Mem1Saved_DoNotShowLinkMsg" 0 "Null" ;
VAL_ 993 MemSetButtnMsgTxt_D_Rq 3 "NotUsed" 2 "Press1or2or3" 1 "Press1or2" 0 "Null" ;
VAL_ 993 PersStore_D_Actl 3 "Unused" 2 "Null" 1 "InProgress" 0 "Complete" ;
VAL_ 993 MemSwtch_D_RqRecall 7 "Unused_3" 6 "Unused_2" 5 "Unused_1" 4 "PERS_4" 3 "PERS_3" 2 "PERS_2" 1 "PERS_1" 0 "Null" ;
VAL_ 993 MemSwtch_D_RqAssoc 7 "Unused_3" 6 "Unused_2" 5 "Unused_1" 4 "PERS_4" 3 "PERS_3" 2 "PERS_2" 1 "PERS_1" 0 "Null" ;
VAL_ 993 PersIndexDsm_D_Actl 7 "Unused_3" 6 "Unused_2" 5 "Unused_1" 4 "Vehicle" 3 "PERS_4" 2 "PERS_3" 1 "PERS_2" 0 "PERS_1" ;
VAL_ 806 ClimtHeatRear_D_Rq 7 "NotUsed4" 6 "NotUsed3" 5 "HtrCoreClntFlwOnly" 4 "PtcHtrTestMde" 3 "Defrost_Defog" 2 "FastTempPullDownHeatingReq" 1 "OpportunisticHeatingReq" 0 "NoHeatingRequest" ;
VAL_ 806 ClimtDeltaLoad_Pw_Actl 63 "Faulty" 62 "NoDataExists" ;
VAL_ 806 StopStrtDrvMde_B_RqBtn 1 "Pressed" 0 "Not_Pressed" ;
VAL_ 806 WndwFrontHeat_B_Stat 1 "On" 0 "Off" ;
VAL_ 806 HtrCorePump_B_Rq 1 "On" 0 "Off" ;
VAL_ 806 ClimtHeat_D_Rq 7 "NotUsed4" 6 "NotUsed3" 5 "HtrCoreClntFlwOnly" 4 "PtcHtrTestMde" 3 "Defrost_Defog" 2 "FastTempPullDownHeatingReq" 1 "OpportunisticHeatingReq" 0 "NoHeatingRequest" ;
VAL_ 806 ClimtCool_D_Rq 7 "NotUsed4" 6 "NotUsed3" 5 "NotUsed2" 4 "ElACTestMde" 3 "Defrost_Defog" 2 "FastTempPullDownCoolReq" 1 "OpportunisticCoolingReq" 0 "NoCoolingRequest" ;
VAL_ 806 HvacEvap_Te_Actl 1023 "Fault" ;
VAL_ 806 HvacAirCond_B_Rq 1 "Yes" 0 "No" ;
VAL_ 806 ClimtPw_B_Rq 1 "Yes" 0 "No" ;
VAL_ 950 Modulation_Ctrl 3 "Unused" 2 "FSK" 1 "ASK_FSK" 0 "ASK" ;
VAL_ 950 TirePress_Filter_Ctrl 3 "Streaming" 2 "Filter" 1 "Not_Used" 0 "Null" ;
VAL_ 857 LHS_Temp_Disp_Digit3 2 "_5" 1 "_0" 0 "OFF" ;
VAL_ 857 Front_Blower_Ind 15 "Display_Blank" 14 "14_Indicators_On" 13 "13_Indicators_On" 12 "12_Indicators_On" 11 "11_Indicators_On" 10 "10_Indicators_On" 9 "9_Indicators_On" 8 "8_Indicators_On" 7 "7_Indicators_On" 6 "6_Indicators_On" 5 "5_Indicators_On" 4 "4_Indicators_On" 3 "3_Indicators_On" 2 "2_Indicators_On" 1 "1_Indicator_On" 0 "Indicators_Off" ;
VAL_ 857 EATC_LHS_Unit 2 "Fahrenheit" 1 "Celsius" 0 "Off" ;
VAL_ 856 Frt_Blower_Speed2 15 "NotUsed_6" 14 "NotUsed_5" 13 "NotUsed_4" 12 "NotUsed_3" 11 "NotUsed_2" 10 "Zero_Blower" 9 "Max_Blower" 8 "Min_Blower" 7 "Blower_Speed_7" 6 "Blower_Speed_6" 5 "Blower_Speed_5" 4 "Blower_Speed_4" 3 "Blower_Speed_3" 2 "Blower_Speed_2" 1 "Blower_Speed_1" 0 "No_Request" ;
VAL_ 856 Psngr_Set_Temp 31 "HI" 30 "_29_5" 29 "_29_0" 28 "_28_5" 27 "_28_0" 26 "_27_5" 25 "_27_0" 24 "_26_5" 23 "_26_0" 22 "_25_5" 21 "_25_0" 20 "_24_5" 19 "_24_0" 18 "_23_5" 17 "_23_0" 16 "_22_5" 15 "_22_0" 14 "_21_5" 13 "_21_0" 12 "_20_5" 11 "_20_0" 10 "_19_5" 9 "_19_0" 8 "_18_5" 7 "_18_0" 6 "_17_5" 5 "_17_0" 4 "_16_5" 3 "_16_0" 2 "_15_5" 1 "LO" 0 "No_Request" ;
VAL_ 856 SnowPlowOn_B_Rq 1 "On" 0 "Off" ;
VAL_ 856 ClimtRearView_D_Stat 3 "ThirdRow" 2 "SecondRow" 1 "Both" 0 "NotDisplayed" ;
VAL_ 856 Rr_Btn_Status_2nd 31 "NotUsed_7" 30 "NotUsed_6" 29 "NotUsed_5" 28 "NotUsed_4" 27 "NotUsed_3" 26 "NotUsed_2" 25 "NotUsed_1" 24 "Third_Sync_Pressed" 23 "Third_Rr_Pwr_Pressed" 22 "Third_Auto_Pressed" 21 "Third_Pnl_Flr_Pressed" 20 "Third_Floor_Pressed" 19 "Third_Panel_Pressed" 18 "Third_Blwr_Dec_Pressed" 17 "Third_Blwr_Inc_Pressed" 16 "Rear_Lock_Pressed" 15 "RHS_Cld_Seat_Pressed" 14 "LHS_Cld_Seat_Pressed" 13 "RHS_Htd_Seat_Pressed" 12 "LHS_Htd_Seat_Pressed" 11 "Rear_Power_Pressed" 10 "AUTO_Pressed" 9 "Blwr_Dec_Pressed" 8 "Blwr_Inc_Pressed" 7 "RHS_Temp_Dec_Pressed" 6 "RHS_Temp_Inc_Pressed" 5 "LHS_Temp_Dec_Pressed" 4 "LHS_Temp_Inc_Pressed" 3 "Floor_Pressed" 2 "Panel_Floor_Pressed" 1 "Panel_Pressed" 0 "None_Pressed" ;
VAL_ 856 Rr_Btn_Status_1st 31 "NotUsed_7" 30 "NotUsed_6" 29 "NotUsed_5" 28 "NotUsed_4" 27 "NotUsed_3" 26 "NotUsed_2" 25 "NotUsed_1" 24 "Third_Sync_Pressed" 23 "Third_Rr_Pwr_Pressed" 22 "Third_Auto_Pressed" 21 "Third_Pnl_Flr_Pressed" 20 "Third_Floor_Pressed" 19 "Third_Panel_Pressed" 18 "Third_Blwr_Dec_Pressed" 17 "Third_Blwr_Inc_Pressed" 16 "Rear_Lock_Pressed" 15 "RHS_Cld_Seat_Pressed" 14 "LHS_Cld_Seat_Pressed" 13 "RHS_Htd_Seat_Pressed" 12 "LHS_Htd_Seat_Pressed" 11 "Rear_Power_Pressed" 10 "AUTO_Pressed" 9 "Blwr_Dec_Pressed" 8 "Blwr_Inc_Pressed" 7 "RHS_Temp_Dec_Pressed" 6 "RHS_Temp_Inc_Pressed" 5 "LHS_Temp_Dec_Pressed" 4 "LHS_Temp_Inc_Pressed" 3 "Floor_Pressed" 2 "Panel_Floor_Pressed" 1 "Panel_Pressed" 0 "None_Pressed" ;
VAL_ 856 Frt_Btn_Status_2nd 4 "Floor_Ws_Pressed" 5 "AC_Pressed" 6 "Dual_Pressed" 7 "LHS_Temp_Inc_Pressed" 0 "None_Pressed" 1 "Panel_Pressed" 2 "Panel_Floor_Pressed" 3 "Floor_Pressed" 8 "LHS_Temp_Dec_Pressed" 9 "RHS_Temp_Inc_Pressed" 10 "RHS_Temp_Dec_Pressed" 11 "Blwr_Inc_Pressed" 12 "Blwr_Dec_Pressed" 13 "AUTO_Pressed" 14 "Max_AC_Pressed" 15 "Recirc_Pressed" 16 "Outside_Pressed" 17 "Auto_Recirc_Pressed" 18 "Htd_Frt_Wsh_Pressed" 19 "Windscreen_Pressed" 20 "Pnl_Ws_Pressed" 21 "Pnl_Flr_Ws_Pressed" 22 "Rear_Defrost_Pressed" 23 "Front_Power_Pressed" 24 "My_Temp_Pressed" 25 "Max_Defrost_Pressed" 26 "LHS_Htd_Seat_Pressed" 27 "RHS_Htd_Seat_Pressed" 28 "LHS_Cld_Seat_Pressed" 29 "RHS_Cld_Seat_Pressed" 30 "Htg_Strg_Whl_Pressed" 31 "Defrost_Pressed" 37 "DrvrFcsdMde_PRessed" 38 "LHS_Seat_Off_Pressed" 39 "LHS_Htd_Seat1_Pressed" 40 "LHS_Htd_Seat2_Pressed" 41 "LHS_Htd_Seat3_Pressed" 42 "LHS_Auto_Seat_Pressed" 43 "RHS_Seat_Off_Pressed" 44 "RHS_Htd_Seat1_Pressed" 45 "RHS_Htd_Seat2_Pressed" 46 "RHS_Htd_Seat3_Pressed" 47 "RHS_Auto_Seat_Pressed" 48 "LHS_Cld_Seat1_Pressed" 49 "LHS_Cld_Seat2_Pressed" 50 "LHS_Cld_Seat3_Pressed" 51 "RHS_Cld_Seat1_Pressed" 52 "RHS_Cld_Seat2_Pressed" 53 "RHS_Cld_Seat3_Pressed" 54 "AUTO_Lo_Pressed" 55 "AUTO_Med_Pressed" 56 "AUTO_Hi_Pressed" 57 "AUTO_Inc_Pressed" 58 "AUTO_Dec_Pressed" 59 "NotUsed_6" 60 "NotUsed_7" 61 "NotUsed_8" 62 "NotUsed_9" 63 "NotUsed_10" 32 "FrontMnu_Pressed" 33 "RearMnu_Pressed" 34 "Heat_Pressed" 35 "AAR_Pressed" 36 "MdeMnu_Pressed" ;
VAL_ 856 Frt_Btn_Status_1st 4 "Floor_Ws_Pressed" 5 "AC_Pressed" 6 "Dual_Pressed" 7 "LHS_Temp_Inc_Pressed" 0 "None_Pressed" 1 "Panel_Pressed" 2 "Panel_Floor_Pressed" 3 "Floor_Pressed" 8 "LHS_Temp_Dec_Pressed" 9 "RHS_Temp_Inc_Pressed" 10 "RHS_Temp_Dec_Pressed" 11 "Blwr_Inc_Pressed" 12 "Blwr_Dec_Pressed" 13 "AUTO_Pressed" 14 "Max_AC_Pressed" 15 "Recirc_Pressed" 16 "Outside_Pressed" 17 "Auto_Recirc_Pressed" 18 "Htd_Frt_Wsh_Pressed" 19 "Windscreen_Pressed" 20 "Pnl_Ws_Pressed" 21 "Pnl_Flr_Ws_Pressed" 22 "Rear_Defrost_Pressed" 23 "Front_Power_Pressed" 24 "My_Temp_Pressed" 25 "Max_Defrost_Pressed" 26 "LHS_Htd_Seat_Pressed" 27 "RHS_Htd_Seat_Pressed" 28 "LHS_Cld_Seat_Pressed" 29 "RHS_Cld_Seat_Pressed" 30 "Htg_Strg_Whl_Pressed" 31 "Defrost_Pressed" 37 "DrvrFcsdMde_PRessed" 38 "LHS_Seat_Off_Pressed" 39 "LHS_Htd_Seat1_Pressed" 40 "LHS_Htd_Seat2_Pressed" 41 "LHS_Htd_Seat3_Pressed" 42 "LHS_Auto_Seat_Pressed" 43 "RHS_Seat_Off_Pressed" 44 "RHS_Htd_Seat1_Pressed" 45 "RHS_Htd_Seat2_Pressed" 46 "RHS_Htd_Seat3_Pressed" 47 "RHS_Auto_Seat_Pressed" 48 "LHS_Cld_Seat1_Pressed" 49 "LHS_Cld_Seat2_Pressed" 50 "LHS_Cld_Seat3_Pressed" 51 "RHS_Cld_Seat1_Pressed" 52 "RHS_Cld_Seat2_Pressed" 53 "RHS_Cld_Seat3_Pressed" 54 "AUTO_Lo_Pressed" 55 "AUTO_Med_Pressed" 56 "AUTO_Hi_Pressed" 57 "AUTO_Inc_Pressed" 58 "AUTO_Dec_Pressed" 59 "NotUsed_6" 60 "NotUsed_7" 61 "NotUsed_8" 62 "NotUsed_9" 63 "NotUsed_10" 32 "FrontMnu_Pressed" 33 "RearMnu_Pressed" 34 "Heat_Pressed" 35 "AAR_Pressed" 36 "MdeMnu_Pressed" ;
VAL_ 856 Frt_Blower_Speed 3 "NotUsed" 2 "Max_Blower" 1 "Min_Blower" 0 "No_Request" ;
VAL_ 856 Drv_Set_Temp 31 "HI" 30 "29_5" 29 "29_0" 28 "28_5" 27 "28_0" 26 "27_5" 25 "27_0" 24 "26_5" 23 "26_0" 22 "25_5" 21 "25_0" 20 "24_5" 19 "24_0" 18 "23_5" 17 "23_0" 16 "22_5" 15 "22_0" 14 "21_5" 13 "21_0" 12 "20_5" 11 "20_0" 10 "19_5" 9 "19_0" 8 "18_5" 7 "18_0" 6 "17_5" 5 "17_0" 4 "16_5" 3 "16_0" 2 "15_5" 1 "LO" 0 "No_Request" ;
VAL_ 854 SelDrvMdeSwtch_D_Stat2 3 "Faulty" 2 "SwitchState2" 1 "SwitchState1" 0 "NotPressed" ;
VAL_ 854 LHS_Auto_Seat_Btn_Stt 3 "Unused" 2 "Disabled" 1 "Active" 0 "Enabled_Inactive" ;
VAL_ 854 RHS_Auto_Seat_Btn_Stt 3 "Unused" 2 "Disabled" 1 "Active" 0 "Enabled_Inactive" ;
VAL_ 854 CC_Fr_Stat_User_Adj 7 "Unused4" 6 "RHS_AUTO_St_Selection" 5 "LHS_AUTO_St_Selection" 4 "DrvrFcsdMde_Selection" 3 "Fr_Blwr_Spd_Selection" 2 "FRHS_SetPt_Selection" 1 "FLHS_SetPt_Selection" 0 "None" ;
VAL_ 854 Front_Blower_Indicate 15 "Display_Blank" 14 "14_Indicators_On" 13 "13_Indicators_On" 12 "12_Indicators_On" 11 "11_Indicators_On" 10 "10_Indicators_On" 9 "9_Indicators_On" 8 "8_Indicators_On" 7 "7_Indicators_On" 6 "6_Indicators_On" 5 "5_Indicators_On" 4 "4_Indicators_On" 3 "3_Indicators_On" 2 "2_Indicators_On" 1 "1_Indicator_On" 0 "Indicators_Off" ;
VAL_ 854 CC_Diagnostics_Active 1 "Yes" 0 "No" ;
VAL_ 854 RHS_Temp_Display_Digit3 2 "_5" 1 "_0" 0 "OFF" ;
VAL_ 854 LHS_Temp_Display_Digit3 2 "_5" 1 "_0" 0 "OFF" ;
VAL_ 854 EATC_RHS_Units 2 "Fahrenheit" 1 "Celsius" 0 "Off" ;
VAL_ 854 EATC_LHS_Units 2 "Fahrenheit" 1 "Celsius" 0 "Off" ;
VAL_ 534 WhlDirRr_D_Actl 3 "Faulty" 2 "NoDataExists" 1 "Backward" 0 "Forward" ;
VAL_ 534 WhlDirRl_D_Actl 3 "Faulty" 2 "NoDataExists" 1 "Backward" 0 "Forward" ;
VAL_ 534 WhlDirFr_D_Actl 3 "Faulty" 2 "NoDataExists" 1 "Backward" 0 "Forward" ;
VAL_ 534 WhlDirFl_D_Actl 3 "Faulty" 2 "NoDataExists" 1 "Backward" 0 "Forward" ;
VAL_ 772 SeatScrnDrvOn_B_Rq 1 "On" 0 "Off" ;
VAL_ 772 SeatPos_D_Stat 7 "NotUsed3" 6 "NotUsed2" 5 "Error" 4 "Drive" 3 "Moving" 2 "Pending" 1 "EasyEntry" 0 "Null" ;
VAL_ 772 MemDrvDeny_B_Stat 1 "Yes" 0 "No" ;
VAL_ 772 Memory_Feedback_Rqst 1 "Yes" 0 "No" ;
VAL_ 772 Easy_Entry_Rqst 2 "Easy_Entry" 1 "Drive" 0 "Null" ;
VAL_ 772 Memory_Cmd 7 "Recall_3" 4 "Store_4" 3 "Store_3" 6 "Recall_2" 5 "Recall_1" 2 "Store_2" 1 "Store_1" 0 "Null" 8 "Recall_4" ;
VAL_ 772 Cancel_Auto_Movement 1 "Cancel" 0 "Null" ;
VAL_ 1070 StopStrtStdby_D_Indic_UB 1 "Fresh_data" 0 "Unchanged_data" ;
VAL_ 1070 PassRstrnInd_Req_UB 1 "Fresh_data" 0 "Unchanged_data" ;
VAL_ 1070 HiElPwInhbt_B_Stat_UB 1 "Fresh_data" 0 "Unchanged_data" ;
VAL_ 1070 HiElPwInhbt_B_Stat 1 "Inhibit" 0 "No_Inibit" ;
VAL_ 1070 StopStrtStdby_D_Indic 6 "Telltale_On_Grey" 5 "Telltale_Struck_Out" 4 "Telltale_Flashing_Amber" 3 "Telltale_On_Amber" 2 "Telltale_Flashing_Green" 1 "Telltale_On_Green" 0 "Telltale_Off" 7 "NotUsed3" ;
VAL_ 1070 CoolantFanStepAct_UB 1 "Fresh_data" 0 "Unchanged_data" ;
VAL_ 1070 CoolantFanStepAct 31 "Unused7" 30 "Unused6" 29 "Unused5" 28 "Unused4" 27 "Unused3" 26 "Unused2" 25 "Unused1" 23 "Step23" 22 "Step22" 21 "Step21" 20 "Step20" 19 "Step19" 18 "Step18" 17 "Step17" 16 "Step16" 15 "Step15" 14 "Step14" 13 "Step13" 12 "Step12" 11 "Step11" 10 "Step10" 9 "Step9" 8 "Step8" 7 "Step7" 6 "Step6" 5 "Step5" 4 "Step4" 3 "Step3" 2 "Step2" 1 "Step1" 24 "Max_Fan_Speed_Req" 0 "Fan_Cmd_Off" ;
VAL_ 1070 Reserve_UB 1 "Fresh_data" 0 "Unchanged_data" ;
VAL_ 1070 RstrnImpactEvntStatus_UB 1 "Fresh_data" 0 "Unchanged_data" ;
VAL_ 1070 EngAirIn_Te_Actl_UB 1 "Fresh_data" 0 "Unchanged_data" ;
VAL_ 1070 RstrnImpactEvntStatus 7 "Invalid" 6 "Not_Used_4" 5 "Threshold_2_Exceeded" 4 "Not_Used_3" 3 "Threshold_1_Exceeded" 2 "Not_Used_2" 1 "Not_Used_1" 0 "Normal" ;
VAL_ 1070 EngAirIn_Te_Actl 1023 "Fault" 1022 "Unknown" ;
VAL_ 1070 EngAout_N_Actl_UB 1 "Fresh_data" 0 "Unchanged_data" ;
VAL_ 1070 VehVActlEng_D_Qf 3 "OK" 2 "Not_Within_Specifications" 1 "No_Data_Exists" 0 "Faulty" ;
VAL_ 1070 Veh_V_ActlEng_UB 1 "Fresh_data" 0 "Unchanged_data" ;
VAL_ 1070 PassRstrnInd_Req 3 "ABOnNotIllum_OffNotIllum" 2 "AirbagOnNot_Illum_OffIllum" 1 "AirbagOn_Illum_OffNotIllum" 0 "AirbagOn_Illum_Off_Illum" ;
VAL_ 1050 MirrorHeatOn_B_Rq 1 "True" 0 "False" ;
VAL_ 1050 CamraRearBttn_D_Stat 1 "Pressed" 0 "Not_Pressed" ;
VAL_ 1050 AutoHoldSwtch_D_Stat 3 "Faulty" 2 "NotUsed" 1 "Pressed" 0 "Not_Pressed" ;
VAL_ 1050 EcoInhbt_B_RqHvac 1 "Yes" 0 "No" ;
VAL_ 1050 LpdbPtc3_B_Rq 1 "On" 0 "Off" ;
VAL_ 1050 LpdbPtc2_B_Rq 1 "On" 0 "Off" ;
VAL_ 1050 LpdbPtc1_B_Rq 1 "On" 0 "Off" ;
VAL_ 1050 LpdbHeatWiprPrk_B_Rq 1 "On" 0 "Off" ;
VAL_ 1050 LpdbDfrstRearOn_B_Rq 1 "On" 0 "Off" ;
VAL_ 1050 LpdbDfrstFrOn_B_Rq 1 "On" 0 "Off" ;
VAL_ 1050 LpdbDfrstFlOn_B_Rq 1 "On" 0 "Off" ;
VAL_ 1050 LpdbAuxBlwr_B_Rq 1 "On" 0 "Off" ;
VAL_ 1050 SteWhlHeat_D_Rq 15 "NotUsed6" 14 "NotUsed5" 13 "NotUsed4" 12 "NotUsed3" 11 "NotUsed2" 10 "NotUsed1" 9 "Reserved_3" 8 "Reserved_2" 7 "Reserved_1" 6 "Level_3_Heating" 5 "Level_3_Heating_LS" 4 "Level_2_Heating" 3 "Level_2_Heating_LS" 2 "Level_1_Heating" 1 "Level_1_Heating_LS" 0 "Off" ;
VAL_ 1050 Remote_Start_QuietMode 1 "Quiet" 0 "Not_Quiet" ;
VAL_ 1050 Outside_Air_Temp_Stat 255 "Invalid" 254 "Unknown" ;
VAL_ 947 DrStatDrvErrCnt_B_Stat 1 "Yes" 0 "No" ;
VAL_ 947 TurnLghtRightOn_B_Stat 1 "On" 0 "Off" ;
VAL_ 947 TurnLghtLeftOn_B_Stat 1 "On" 0 "Off" ;
VAL_ 947 Backlit_LED_Status 15 "Unused3" 14 "Unused2" 13 "Unused1" 12 "Night_12" 11 "Night_11" 10 "Night_10" 9 "Night_9" 8 "Night_8" 7 "Night_7" 6 "Night_6" 5 "Night_5" 4 "Night_4" 3 "Night_3" 2 "Night_2" 1 "Night_1" 0 "Off" ;
VAL_ 947 FogLghtRearOn_B_Stat 1 "On" 0 "Off" ;
VAL_ 947 ValetMode_D_Mem 1 "On" 0 "Off" ;
VAL_ 947 IgnKeyType_D_Actl 15 "Invalid" 14 "Unknown" 3 "Key_Not_Prgrm_Read_Failure" 2 "Key_In_Ign_My_Key" 1 "Key_In_Ign_Standard_Key" 0 "Key_Read_In_Progress" ;
VAL_ 947 TurnLghtRight_D_Rq 3 "Seq" 2 "On" 1 "Off" 0 "Null" ;
VAL_ 947 Parklamp_Status 3 "Invalid" 2 "Unknown" 1 "On" 0 "Off" ;
VAL_ 947 Litval 255 "Invalid" 254 "Unknown" 5 "Day" 4 "Twilight_4" 3 "Twilight_3" 2 "Twilight_2" 1 "Twilight_1" 0 "Night" ;
VAL_ 947 Key_In_Ignition_Stat 1 "In" 0 "Out" ;
VAL_ 947 Ignition_Status 0 "Unknown" 1 "Off" 15 "Invalid" 8 "Start" 4 "Run" 2 "Accessory" ;
VAL_ 947 Dimming_Lvl 255 "Invalid" 254 "Unknown" 18 "Day_6" 17 "Day_5" 16 "Day_4" 15 "Day_3" 14 "Day_2" 13 "Day_1" 12 "Night_12" 11 "Night_11" 10 "Night_10" 9 "Night_9" 8 "Night_8" 7 "Night_7" 6 "Night_6" 5 "Night_5" 4 "Night_4" 3 "Night_3" 2 "Night_2" 1 "Night_1" 0 "Off" ;
VAL_ 947 Day_Night_Status 3 "NotUsed" 2 "Night" 1 "Day" 0 "Null" ;
VAL_ 947 Remote_Start_Status 3 "Invalid" 2 "Unknown" 1 "Remote" 0 "Null" ;
VAL_ 947 DrStatTgate_B_Actl 1 "Ajar" 0 "Closed" ;
VAL_ 947 DrStatRr_B_Actl 1 "Ajar" 0 "Closed" ;
VAL_ 947 DrStatRl_B_Actl 1 "Ajar" 0 "Closed" ;
VAL_ 947 DrStatPsngr_B_Actl 1 "Ajar" 0 "Closed" ;
VAL_ 947 DrStatInnrTgate_B_Actl 1 "Ajar" 0 "Closed" ;
VAL_ 947 DrStatHood_B_Actl 1 "Ajar" 0 "Closed" ;
VAL_ 947 DrStatDrv_B_Actl 1 "Ajar" 0 "Closed" ;
VAL_ 947 PrkBrkActv_B_Actl 1 "Active" 0 "Inactive" ;
VAL_ 947 LifeCycMde_D_Actl 3 "Transport" 2 "NotUsed" 1 "Factory" 0 "Normal" ;
VAL_ 947 Delay_Accy 1 "On" 0 "Off" ;
VAL_ 947 FogLghtFrontOn_B_Stat 1 "On" 0 "Off" ;
VAL_ 947 TurnLghtLeft_D_Rq 3 "Seq" 2 "On" 1 "Off" 0 "Null" ;
VAL_ 947 CrashEvnt_D_Stat 3 "Invalid" 2 "Fuel_Cutoff_Event" 1 "Deploy_Event" 0 "No_Event" ;
VAL_ 947 FuelPmpInhbt_B_Stat 1 "Inhibit" 0 "No_Inibit" ;
VAL_ 947 BodySrvcRqd_B_Rq 1 "Yes" 0 "No" ;
VAL_ 1126 GpsUtcYr_No_Actl 31 "Fault" ;
VAL_ 1126 GpsUtcMnth_No_Actl 15 "Fault" ;
VAL_ 1126 GPS_UTC_seconds 63 "Fault" 62 "Unknown" ;
VAL_ 1126 GPS_UTC_minutes 63 "Fault" 62 "Unknown" ;
VAL_ 1126 GPS_UTC_hours 31 "Invalid" 30 "Unknown" ;
VAL_ 1126 GPS_Pdop 31 "Invalid" 30 "Unknown" ;
VAL_ 1126 GPS_Compass_direction 7 "NorthWest" 6 "West" 5 "SouthWest" 4 "South" 3 "SouthEast" 2 "East" 1 "NorthEast" 0 "North" ;
VAL_ 1126 GPS_Actual_vs_Infer_pos 1 "Inferred_Position" 0 "Actual_Postition" ;
VAL_ 1126 Gps_B_Falt 1 "Yes" 0 "No" ;
VAL_ 1125 GpsHsphLongEast_D_Actl 0 "Invalid" 1 "Eastern" 2 "Western" 3 "Fault" ;
VAL_ 1125 GpsHsphLattSth_D_Actl 3 "Fault" 2 "Northern" 1 "Southern" 0 "Invalid" ;
VAL_ 1125 GPS_Longitude_Minutes 63 "Fault" 62 "Unknown" ;
VAL_ 1125 GPS_Longitude_Min_dec 16383 "Invalid" 16382 "Unknown" ;
VAL_ 1125 GPS_Longitude_Degrees 511 "Fault" 510 "Unknown" ;
VAL_ 1125 GPS_Latitude_Minutes 63 "Fault" 62 "Unknown" ;
VAL_ 1125 GPS_Latitude_Min_dec 16383 "Invalid" 16382 "Unknown" ;
VAL_ 1125 GPS_Latitude_Degrees 255 "Invalid" 254 "Unknown" ;
VAL_ 992 MsgCntrPersIndex_D_Rq 7 "Unused_3" 6 "Unused_2" 5 "Unused_1" 4 "Vehicle" 3 "PERS_4" 2 "PERS_3" 1 "PERS_2" 0 "PERS_1" ;
VAL_ 992 MsgCntrDsplyOp_D_Rq 7 "Unused_2" 6 "Unused_1" 5 "Copy" 4 "Restore" 3 "Upload" 2 "Set" 1 "Query" 0 "Null" ;
VAL_ 1127 GPS_Vdop 31 "Invalid" 30 "Unknown" ;
VAL_ 1127 GPS_Speed 255 "Invalid" 254 "Unknown" ;
VAL_ 1127 GPS_Sat_num_in_view 31 "Invalid" 30 "Unknown" ;
VAL_ 1127 GPS_MSL_altitude 4095 "Fault" 4094 "Unknown" ;
VAL_ 1127 GPS_Heading 65535 "Fault" 65534 "Unknown" ;
VAL_ 1127 GPS_Hdop 31 "Invalid" 30 "Unknown" ;
VAL_ 1127 GPS_dimension 2 "_3D" 1 "_2D" 0 "No_Fix" ;
VAL_ 999 PersIndexFcim_D_Actl 7 "Unused_3" 6 "Unused_2" 5 "Unused_1" 4 "Vehicle" 3 "PERS_4" 2 "PERS_3" 1 "PERS_2" 0 "PERS_1" ;
VAL_ 862 HvacBlwrFront_D_Stat 31 "Not_Used" 20 "Full_On" 19 "95_Percent" 18 "90_Percent" 17 "85_Percent" 16 "80_Percent" 15 "75_Percent" 14 "70_Percent" 13 "65_Percent" 12 "60_Percent" 11 "55_Percent" 10 "50_Percent" 9 "45_Percent" 8 "40_Percent" 7 "35_Percent" 6 "30_Percent" 5 "25_Percent" 4 "20_Percent" 3 "15_Percent" 2 "10_Percent" 1 "5_Percent" 0 "Off" ;
VAL_ 862 ClimtThrmlLoad_No_Actl 255 "Fault" ;
VAL_ 862 CamraDefog_B_Actl 1 "On" 0 "Off" ;
VAL_ 862 CabnAmb_Te_Actl 255 "Fault" ;
VAL_ 862 AutoStpHvacDelta_I_Est 255 "Fault" ;
VAL_ 828 DrvSpotLight_B_Rq 1 "Yes" 0 "No" ;
VAL_ 828 SpotLghtRight_D_Stat 1 "On" 0 "Off" ;
VAL_ 828 RearPassWindowPos 7 "Unused2" 6 "Unused1" 5 "Fully_Open" 4 "Bet60Percent_FullyOpen" 3 "Bet10Percent_60Percent" 2 "BetFully_10PercentOpen" 1 "Fully_Closed" 0 "Undefined" ;
VAL_ 828 PassWindowPosition 7 "Unused2" 6 "Unused1" 5 "Fully_Open" 4 "Bet60Percent_FullyOpen" 3 "Bet10Percent_60Percent" 2 "BetFully_10PercentOpen" 1 "Fully_Closed" 0 "Undefined" ;
VAL_ 828 SpotLghtLeft_D_Stat 1 "On" 0 "Off" ;
VAL_ 826 Memory_3_Sw_Stat 1 "Pressed" 0 "Null" ;
VAL_ 826 Memory_2_Sw_Stat 1 "Pressed" 0 "Null" ;
VAL_ 826 Memory_1_Sw_Stat 1 "Pressed" 0 "Null" ;
VAL_ 826 Mirror_Manual_Override 1 "Override" 0 "Null" ;
VAL_ 853 RHS_Htd_Seat_Btn_Stt 3 "Unused" 2 "Disabled" 1 "Active" 0 "Enabled_Inactive" ;
VAL_ 853 RHS_Cld_Seat_Btn_Stt 3 "Unused" 2 "Disabled" 1 "Active" 0 "Enabled_Inactive" ;
VAL_ 853 Outside_Btn_Stt 3 "Unused" 2 "Disabled" 1 "Active" 0 "Enabled_Inactive" ;
VAL_ 853 LHS_Htd_Seat_Btn_Stt 3 "Unused" 2 "Disabled" 1 "Active" 0 "Enabled_Inactive" ;
VAL_ 853 LHS_Cld_Seat_Btn_Stt 3 "Unused" 2 "Disabled" 1 "Active" 0 "Enabled_Inactive" ;
VAL_ 853 FrontMnu_Buttn_Stat 1 "Pressed" 0 "Not_Pressed" ;
VAL_ 853 Defrost_Btn_Stt 3 "Unused" 2 "Disabled" 1 "Active" 0 "Enabled_Inactive" ;
VAL_ 853 Auto_Recirc_Btn_Stt 3 "Unused" 2 "Disabled" 1 "Active" 0 "Enabled_Inactive" ;
VAL_ 853 Front_AUTO_Blwr_Lvl 3 "High" 2 "Medium" 1 "Low" 0 "Off" ;
VAL_ 853 RHS_Cond_Seat_Status 7 "Unused" 6 "Level_3_Heating" 5 "Level_2_Heating" 4 "Level_1_Heating" 3 "Level_3_Cooling" 2 "Level_2_Cooling" 1 "Level_1_Cooling" 0 "Off" ;
VAL_ 853 LHS_Cond_Seat_Status 7 "Unused" 6 "Level_3_Heating" 5 "Level_2_Heating" 4 "Level_1_Heating" 3 "Level_3_Cooling" 2 "Level_2_Cooling" 1 "Level_1_Cooling" 0 "Off" ;
VAL_ 853 Htd_Strg_Whl_Status 3 "Level_3_Heating" 2 "Level_2_Heating" 1 "Level_1_Heating" 0 "Off" ;
VAL_ 853 Htd_Strg_Whl_Btn_Stt 3 "Unused" 2 "Disabled" 1 "Active" 0 "Enabled_Inactive" ;
VAL_ 853 CC_Fr_Btn_User_Adj 31 "Unused15" 30 "Unused14" 29 "Unused13" 28 "Unused12" 27 "Unused11" 26 "Unused10" 25 "Unused9" 24 "Unused8" 23 "Unused7" 22 "Unused6" 21 "RHS_Cld_St_Selection" 20 "LHS_Cld_St_Selection" 19 "UFC_Interrupted" 18 "UFC_Complete" 17 "UFC_Active" 16 "Htd_WS_Selection" 15 "RHS_Htd_St_Selection" 14 "LHS_Htd_St_Selection" 13 "HSW_Selection" 12 "Dual_Selection" 11 "Rear_Defrost_Selection" 10 "Max_Defrost_Selection" 9 "Defrost_Selection" 8 "Fr_Air_Dist_Selection" 7 "Max_AC_Selection" 6 "Fr_Power_Selection" 5 "Recirc_Selection" 4 "AC_Selection" 3 "Fr_Auto_Selection" 2 "Use_MyTemp_Selection" 1 "Save_MyTemp_Selection" 0 "None" ;
VAL_ 853 Htd_Frt_Wsh_Btn_Stt 3 "Unused" 2 "Disabled" 1 "Active" 0 "Enabled_Inactive" ;
VAL_ 853 Recirc_Btn_Stt 3 "Unused" 2 "Disabled" 1 "Active" 0 "Enabled_Inactive" ;
VAL_ 853 Rear_Defrost_Btn_Stt 3 "Unused" 2 "Disabled" 1 "Active" 0 "Enabled_Inactive" ;
VAL_ 853 My_Temp_Btn_Stt 3 "Unused" 2 "Disabled" 1 "Active" 0 "Enabled_Inactive" ;
VAL_ 853 Max_Defrost_Btn_Stt 3 "Unused" 2 "Disabled" 1 "Active" 0 "Enabled_Inactive" ;
VAL_ 853 Max_AC_Btn_Stt 3 "Unused" 2 "Disabled" 1 "Active" 0 "Enabled_Inactive" ;
VAL_ 853 Front_AUTO_Label 3 "Full" 2 "Mode" 1 "Blower" 0 "Off" ;
VAL_ 853 Windscreen_Btn_Stt 3 "Unused" 2 "Disabled" 1 "Active" 0 "Enabled_Inactive" ;
VAL_ 853 Panel_Btn_Stt 3 "Unused" 2 "Disabled" 1 "Active" 0 "Enabled_Inactive" ;
VAL_ 853 Front_Power_Btn_Stt 3 "Unused" 2 "Disabled" 1 "Active" 0 "Enabled_Inactive" ;
VAL_ 853 Front_AUTO_Btn_Stt 3 "Unused" 2 "Disabled" 1 "Active" 0 "Enabled_Inactive" ;
VAL_ 853 Floor_Btn_Stt 3 "Unused" 2 "Disabled" 1 "Active" 0 "Enabled_Inactive" ;
VAL_ 853 Dual_Button_Stt 3 "Unused" 2 "Disabled" 1 "Active" 0 "Enabled_Inactive" ;
VAL_ 853 AC_Btn_Stt 3 "Unused" 2 "Disabled" 1 "Active" 0 "Enabled_Inactive" ;
VAL_ 956 PwSrcULoFalt_D_Stat_UB 1 "Fresh_data" 0 "Unchanged_data" ;
VAL_ 956 PwSrcULo_Pc_Mx_UB 1 "Fresh_data" 0 "Unchanged_data" ;
VAL_ 956 PwSrcULo_Pc_Mx 255 "Fault" ;
VAL_ 956 WndwFrontHeat_B_Rq_UB 1 "Fresh_data" 0 "Unchanged_data" ;
VAL_ 956 WndwFrontHeat_B_Rq 1 "On" 0 "Off" ;
VAL_ 956 BattTrac_Te_Actl_UB 1 "Fresh_data" 0 "Unchanged_data" ;
VAL_ 956 BattTrac_Te_Actl 1023 "Fault" 1022 "Unknown" ;
VAL_ 956 PwSrcULoFalt_D_Stat 3 "Fault_No_Output" 2 "Fault_Reduced_Output" 1 "Fault_NonSpecific" 0 "No_Fault" ;
VAL_ 956 PrkBrkStatus 7 "GeneralFault_MaintenceMode" 6 "ECD_by_Brake_ECU_Active" 5 "EPB_Limphome_Active" 4 "Rear_Caliper_Open" 3 "RWU_By_EPB_Active" 2 "Rear_Caliper_Transition" 1 "Rear_Caliper_Closed" 0 "Not_Supported" ;
VAL_ 956 GearLvrPos_D_Actl_UB 1 "Fresh_data" 0 "Unchanged_data" ;
VAL_ 956 PrkBrkStatus_UB 1 "Fresh_data" 0 "Unchanged_data" ;
VAL_ 956 ApedPos_Pc_ActlArb_UB 1 "Fresh_data" 0 "Unchanged_data" ;
VAL_ 956 GearLvrPos_D_Actl 15 "Fault" 14 "Unknown_Position" 13 "Undefined_Treat_as__Fault" 12 "Undefined_Treat_as_Fault" 11 "sixth" 10 "fifth" 9 "fourth" 8 "third" 7 "second" 6 "first" 5 "Low" 4 "Sport_DriveSport" 3 "Drive" 2 "Neutral" 1 "Reverse" 0 "Park" ;
VAL_ 831 MirrorTelescopic_D_Rq 3 "NotUsed" 2 "Retract" 1 "Extend" 0 "Null" ;
VAL_ 831 RearPassWindowLockCmd 1 "Enable" 0 "Disable" ;
VAL_ 831 RearPassWindowCmd 7 "Unused2" 6 "Unused1" 5 "NotDefined" 4 "Audo_Down" 3 "Manual_Down" 2 "Auto_Up" 1 "Manual_Up" 0 "Idle" ;
VAL_ 831 PassWindowCmd 7 "Unused2" 6 "Unused1" 5 "NotDefined" 4 "Audo_Down" 3 "Manual_Down" 2 "Auto_Up" 1 "Manual_Up" 0 "Idle" ;
VAL_ 831 PassMirrorCmd 7 "Unused" 6 "Unfold" 5 "Fold" 4 "Right" 3 "Left" 2 "Down" 1 "Up" 0 "Idle" ;
VAL_ 831 DipMirrorPosPassenger 1 "Dipped" 0 "Off" ;
VAL_ 831 ActiveStoragePassenger 7 "Unused3" 6 "Unused2" 5 "Unused1" 4 "StoreDipMemoryButton4" 3 "StoreDipMemoryButton3" 2 "StoreDipMemoryButton2" 1 "StoreDipMemoryButton1" 0 "Off" ;
VAL_ 831 RearDriverWindowPos 7 "Unused2" 6 "Unused1" 5 "Fully_Open" 4 "Bet60Percent_FullyOpen" 3 "Bet10Percent_60Percent" 2 "BetFully_10PercentOpen" 1 "Fully_Closed" 0 "Undefined" ;
VAL_ 831 DriverWindowPosition 7 "Unused2" 6 "Unused1" 5 "Fully_Open" 4 "Bet60Percent_FullyOpen" 3 "Bet10Percent_60Percent" 2 "BetFully_10PercentOpen" 1 "Fully_Closed" 0 "Undefined" ;
VAL_ 787 DrTgateChime2_D_Rq 7 "NotUsed3" 6 "NotUsed2" 5 "NotUsed1" 4 "Long_Repeated" 3 "Fast" 2 "Short" 1 "Long" 0 "Off" ;
VAL_ 787 DrTGate_D_Rq 3 "NotUsed" 2 "Closing" 1 "Opening" 0 "Not_Moving" ;
VAL_ 787 PwLftgtIntSw_B_Stat 1 "Pressed" 0 "Null" ;
VAL_ 787 Power_Liftgate_Mode_Stt 2 "Unused" 3 "Not_Supported" 1 "Enabled" 0 "Disabled" ;
